VERSION ""

NS_ :

BS_:

BU_: BSM BSM2 CADM CVADAS ECM EPS ORC CANOE EVCU2

BO_ 2654552167 TRSC_Detection_DebugMessage: 64 CVADAS
 SG_ FD14_averageIllumination : 384|32@1+ (0.1,0) [0|300] ""  CANOE
 SG_ FD14_hitchCalibrationAngle : 352|32@1- (0.1,0) [-110|110] "deg"  CANOE
 SG_ FD14_rightCalibrationAngle : 320|32@1- (0.1,0) [-110|110] "deg"  CANOE
 SG_ FD14_leftCalibrationAngle : 288|32@1- (0.1,0) [-110|110] "deg"  CANOE
 SG_ FD14_Trailer_tracking_confidence : 95|32@1- (1,0) [0|100] ""  CANOE
 SG_ FD14_Trailer_Recognition_Confide : 127|32@1- (1,0) [0|100] ""  CANOE
 SG_ FD14_OBTLRecalibrate : 48|1@1+ (1,0) [0|1] ""  CANOE
 SG_ FD14_Presentinfo : 49|3@1+ (1,0) [0|2] ""  CANOE
 SG_ FD14_RecognitionInfo : 52|1@1+ (1,0) [0|1] ""  CANOE
 SG_ FD14_trailerCalibrationDelay : 47|1@1+ (1,0) [0|1] ""  CANOE
 SG_ FD14_trailerCalibrationCount : 70|11@1+ (1,0) [0|10] ""  CANOE
 SG_ FD14_TrailerCalFailInfo : 53|3@1+ (1,0) [0|2] ""  CANOE
 SG_ FD14_Trailercalinfo : 56|3@1+ (1,0) [0|2] ""  CANOE
 SG_ FD14_turnaroundSubState : 59|3@1+ (1,0) [0|2] ""  CANOE
 SG_ FD14_calibrationCompleted : 39|1@1+ (1,0) [0|1] ""  CANOE
 SG_ FD14_JackknifeThrAngle : 159|32@1- (0.01,0) [-110|110] "deg"  CANOE
 SG_ FD14_JackknifeAngle : 191|32@1- (0.01,0) [-110|110] "deg"  CANOE
 SG_ FD14_hitchLength : 223|32@1- (0.01,0) [1000|2500] "mm"  CANOE
 SG_ FD14_curState : 62|8@1+ (1,0) [0|7] ""  CANOE
 SG_ FD14_CurrentTrailer_ID : 40|7@1+ (1,0) [0|6] ""  CANOE
 SG_ FD14_calibrationSubState : 36|3@1+ (1,0) [0|2] ""  CANOE
 SG_ FD14_TADAngleRate : 255|32@1- (0.01,0) [-110|110] "deg"  CANOE
 SG_ FD14_TrailerAngleSign : 32|4@1+ (1,0) [0|3] ""  CANOE
 SG_ FD14_trailerAngle : 0|32@1- (0.01,0) [-110|110] "deg"  CANOE

BO_ 2654552168 TRSC_FID_DebugMessage: 64 CVADAS
 SG_ FD14_m_QM_FID_TRSC_ASCMDef : 40|8@1+ (1,0) [0|255] ""  CANOE
 SG_ FD14_m_QM_FID_TRSC_LIMITED_DefVi : 32|8@1+ (1,0) [0|255] ""  CANOE
 SG_ FD14_m_QM_FID_TRSC_CAM_CAL_ABORT : 24|8@1+ (1,0) [0|255] ""  CANOE
 SG_ FD14_m_QM_FID_TRSC_LIMITED_View : 16|8@1+ (1,0) [0|255] ""  CANOE
 SG_ FD14_m_QM_FID_TRSC_DISABLED : 8|8@1+ (1,0) [0|255] ""  CANOE

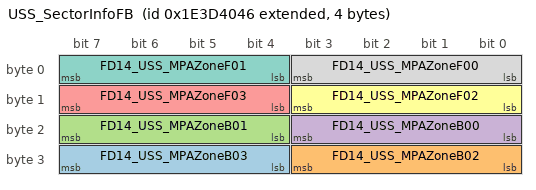
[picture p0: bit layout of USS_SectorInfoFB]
BO_ 2654814278 USS_SectorInfoFB: 4 CVADAS
 SG_ FD14_USS_MPAZoneB03 : 28|4@1+ (1,0) [0|15] ""  CANOE
 SG_ FD14_USS_MPAZoneB02 : 24|4@1+ (1,0) [0|15] ""  CANOE
 SG_ FD14_USS_MPAZoneB01 : 20|4@1+ (1,0) [0|15] ""  CANOE
 SG_ FD14_USS_MPAZoneB00 : 16|4@1+ (1,0) [0|15] ""  CANOE
 SG_ FD14_USS_MPAZoneF03 : 12|4@1+ (1,0) [0|15] ""  CANOE
 SG_ FD14_USS_MPAZoneF02 : 8|4@1+ (1,0) [0|15] ""  CANOE
 SG_ FD14_USS_MPAZoneF01 : 4|4@1+ (1,0) [0|15] ""  CANOE
 SG_ FD14_USS_MPAZoneF00 : 0|4@1+ (1,0) [0|15] ""  CANOE

BO_ 2654552328 USSDebugInfo1: 64 CVADAS
 SG_ FD14_stUSSParkingSlot1DataSlotID : 296|8@1+ (1,0) [0|6] ""  CANOE
 SG_ FD14_stUSSParkingSlot4DataSlotSi : 288|8@1+ (1,0) [0|2] ""  CANOE
 SG_ FD14_stUSSParkingSlot1DataSlotSi : 280|8@1+ (1,0) [0|2] ""  CANOE
 SG_ FD14_stUSSParkingSlot4SlotType : 40|8@1+ (1,0) [0|3] ""  CANOE
 SG_ FD14_stUSSParkingSlot1SlotType : 272|8@1+ (1,0) [0|3] ""  CANOE
 SG_ FD14_stUSSParkingSlot4RearRightY : 240|32@1- (1,0) [0|640] ""  CANOE
 SG_ FD14_stUSSParkingSlot4FrontLeftY : 208|32@1- (1,0) [0|640] ""  CANOE
 SG_ FD14_stUSSParkingSlot1RearRightY : 176|32@1- (1,0) [0|640] ""  CANOE
 SG_ FD14_stUSSParkingSlot1FrontLeftY : 144|32@1- (1,0) [0|640] ""  CANOE
 SG_ FD14_stUSSParkingSlot4RearRightX : 112|32@1- (1,0) [0|400] ""  CANOE
 SG_ FD14_stUSSParkingSlot4FrontLeftX : 80|32@1- (1,0) [0|400] ""  CANOE
 SG_ FD14_stUSSParkingSlot1RearRightX : 48|32@1- (1,0) [0|400] ""  CANOE
 SG_ FD14_stUSSParkingSlot1FrontLeftX : 7|32@1- (1,0) [0|400] ""  CANOE
 SG_ FD14_stUSSParkingSlot6SlotValid : 6|1@1+ (1,0) [0|1] ""  CANOE
 SG_ FD14_stUSSParkingSlot5SlotValid : 5|1@1+ (1,0) [0|1] ""  CANOE
 SG_ FD14_stUSSParkingSlot4SlotValid : 4|1@1+ (1,0) [0|1] ""  CANOE
 SG_ FD14_stUSSParkingSlot3SlotValid : 3|1@1+ (1,0) [0|1] ""  CANOE
 SG_ FD14_stUSSParkingSlot2SlotValid : 2|1@1+ (1,0) [0|1] ""  CANOE
 SG_ FD14_stUSSParkingSlot1SlotValid : 1|1@1+ (1,0) [0|1] ""  CANOE
 SG_ FD14_isUSSInitSuccess_b : 0|1@1+ (1,0) [0|1] ""  CANOE

BO_ 2654552329 USSDebugInfo2: 64 CVADAS
 SG_ FD14_stnumPointsR : 192|16@1+ (1,0) [0|400] ""  CANOE
 SG_ FD14_stnumPointsL : 161|16@1+ (1,0) [0|400] ""  CANOE
 SG_ FD14_stRightObjectList4Valid : 160|1@1+ (1,0) [0|1] ""  CANOE
 SG_ FD14_stRightObjectList3Valid : 159|1@1+ (1,0) [0|1] ""  CANOE
 SG_ FD14_stRightObjectList2Valid : 158|1@1+ (1,0) [0|1] ""  CANOE
 SG_ FD14_stRightObjectList1Valid : 157|1@1+ (1,0) [0|1] ""  CANOE
 SG_ FD14_stLeftObjectList4Valid : 156|1@1+ (1,0) [0|1] ""  CANOE
 SG_ FD14_stLeftObjectList3Valid : 155|1@1+ (1,0) [0|1] ""  CANOE
 SG_ FD14_stLeftObjectList2Valid : 154|1@1+ (1,0) [0|1] ""  CANOE
 SG_ FD14_stLeftObjectList1Valid : 153|1@1+ (1,0) [0|1] ""  CANOE
 SG_ FD14_stUSSLockedSlotDataSlotVali : 152|1@1+ (1,0) [0|1] ""  CANOE
 SG_ FD14_stUSSLockedSlotDataSlotID : 144|8@1+ (1,0) [0|6] ""  CANOE
 SG_ FD14_stUSSLockedSlotDataSlotSide : 136|8@1+ (1,0) [0|2] ""  CANOE
 SG_ FD14_stUSSLockedSlotDataSlotType : 128|8@1+ (1,0) [0|3] ""  CANOE
 SG_ FD14_stUSSLockedSlotDataRearRigh : 96|32@1- (1,0) [0|640] ""  CANOE
 SG_ FD14_stUSSLockedSlotDataFrontLef : 64|32@1- (1,0) [0|640] ""  CANOE
 SG_ FD14_stUSSLockedSlotDataRea_0000 : 32|32@1- (1,0) [0|400] ""  CANOE
 SG_ FD14_stUSSLockedSlotDataFro_0000 : 0|32@1- (1,0) [0|400] ""  CANOE

BO_ 1456 ADAS_FD_HMI: 32 CADM
 SG_ FD14_ACC_Blind : 75|1@0+ (1,0) [0|1] "-"  BSM,ORC
 SG_ FD14_ACC_DispPopupSts : 22|7@0+ (1,0) [0|127] "-"  ORC
 SG_ FD14_ACC_FailSts : 81|1@0+ (1,0) [0|1] "-"  BSM,ORC
 SG_ FD14_ACC_Limit_Fail : 73|1@0+ (1,0) [0|1] "-"  ORC
 SG_ FD14_ACC_Limited : 87|1@0+ (1,0) [0|1] "-"  ORC
 SG_ FD14_ACC_Set_Speed_Strike : 92|1@0+ (1,0) [0|1] "-" Vector__XXX
 SG_ FD14_AEB_Blind : 76|1@0+ (1,0) [0|1] "-"  ORC
 SG_ FD14_AEB_DispPopupSts : 37|6@0+ (1,0) [0|63] "-"  ORC
 SG_ FD14_AEB_FailSts : 83|1@0+ (1,0) [0|1] "-"  BSM,BSM2,ORC
 SG_ FD14_AEB_Limit_Fail : 74|1@0+ (1,0) [0|1] "-"  ORC
 SG_ FD14_AEB_Limited : 72|1@0+ (1,0) [0|1] "-"  BSM,ORC
 SG_ FD14_BlindSpotLeftWarn : 105|2@0+ (1,0) [0|2] ""  ORC
 SG_ FD14_BlindSpotRightWarn : 171|2@0+ (1,0) [0|2] ""  ORC
 SG_ FD14_BSS_Blind_RQSts : 101|1@0+ (1,0) [0|1] ""  ORC
 SG_ FD14_BSS_CFG_STATSts : 103|2@0+ (1,0) [0|2] ""  ORC
 SG_ FD14_BSS_SRV_RQSts : 88|1@0+ (1,0) [0|1] ""  ORC
 SG_ FD14_Chime_Priority : 91|3@0+ (1,0) [0|4] "-" Vector__XXX
 SG_ FD14_Chime_RepRate : 43|4@0+ (1,0) [0|15] "Hz" Vector__XXX
 SG_ FD14_Chime_TypSts : 47|4@0+ (1,0) [0|15] "-"  ORC
 SG_ FD14_CRC_ADAS_FD_HMI : 191|8@0+ (1,0) [0|255] "-"  BSM,BSM2,ECM,EPS
 SG_ FD14_DDD_DispPopupSts : 39|2@0+ (1,0) [0|2] "-"  ORC
 SG_ FD14_DDD_FailSts : 96|1@0+ (1,0) [0|1] "" Vector__XXX
 SG_ FD14_DisplaySts_ACC : 51|4@0+ (1,0) [0|15] "-"  ORC
 SG_ FD14_DisplaySts_Curve : 109|2@0+ (1,0) [0|2] "" Vector__XXX
 SG_ FD14_DisplaySts_OFF : 68|3@0+ (1,0) [0|7] "-" Vector__XXX
 SG_ FD14_DisplaySts_Veh : 63|3@0+ (1,0) [0|7] "-" Vector__XXX
 SG_ FD14_Driver_Model : 107|2@0+ (1,0) [0|3] ""  ORC
 SG_ FD14_FCW_Setting_Avail : 77|1@0+ (1,0) [0|1] "-" Vector__XXX
 SG_ FD14_HAS_Blind : 85|1@0+ (1,0) [0|1] "-"  ORC
 SG_ FD14_HAS_Escalation_Sts : 117|4@0+ (1,0) [0|8] "" Vector__XXX
 SG_ FD14_HAS_FailSts : 80|1@0+ (1,0) [0|1] "-"  ORC
 SG_ FD14_HAS_TelltaleSts : 54|3@0+ (1,0) [0|6] "-"  ORC
 SG_ FD14_HAS_TurnSignalRequest : 111|2@0+ (1,0) [0|2] "" Vector__XXX
 SG_ FD14_ICA_Blind : 55|1@0+ (1,0) [0|1] "-" Vector__XXX
 SG_ FD14_Lane_DisplaySts_Left : 71|3@0+ (1,0) [0|7] "-"  ORC
 SG_ FD14_Lane_DisplaySts_Right : 60|3@0+ (1,0) [0|7] "-"  ORC
 SG_ FD14_Lane_DispPopupSts : 127|8@0+ (1,0) [0|255] "-"  ORC
 SG_ FD14_LF_Chime_RqSts : 93|1@0+ (1,0) [0|1] "-"  ORC
 SG_ FD14_LKA_Blind : 86|1@0+ (1,0) [0|1] "-"  ORC
 SG_ FD14_LKA_FailSts : 84|1@0+ (1,0) [0|1] "-"  ORC
 SG_ FD14_LKA_Status : 23|1@0+ (1,0) [0|1] "-"  ORC
 SG_ FD14_LR_Chime_RqSts : 100|1@0+ (1,0) [0|1] ""  ORC
 SG_ FD14_MessageCounter_ADAS_FD_HMI : 179|4@0+ (1,0) [0|15] "-"  BSM,BSM2,ECM,EPS
 SG_ FD14_NCC_FailSts : 82|1@0+ (1,0) [0|1] "-"  ORC
 SG_ FD14_PEB_Setting_Avail : 78|1@0+ (1,0) [0|1] "-" Vector__XXX
 SG_ FD14_RF_Chime_RqSts : 95|1@0+ (1,0) [0|1] "-"  ORC
 SG_ FD14_RR_Chime_RqSts : 99|1@0+ (1,0) [0|1] ""  ORC
 SG_ FD14_Set_Speed_KPH : 7|8@0+ (1,0) [0|255] "kph"  ECM,ORC
 SG_ FD14_Set_Speed_MPH : 15|8@0+ (1,0) [0|255] "mph"  ECM
 SG_ FD14_SVI_Request : 31|2@0+ (1,0) [0|3] "-" Vector__XXX

BO_ 280 ADAS_FD_INFO: 32 CADM
 SG_ FD14_ACC_Drive_Cmd : 151|1@0+ (1,0) [0|1] "-"  BSM
 SG_ FD14_ACC_StopStart : 97|2@0+ (1,0) [0|2] "-"  ECM
 SG_ FD14_ACC_Systemsts : 183|4@0+ (1,0) [0|14] "-"  BSM,BSM2,CVADAS,ORC
 SG_ FD14_AEB_Sensitivity_Setting : 1|2@0+ (1,0) [0|2] "" Vector__XXX
 SG_ FD14_AEB_Systemsts : 99|2@0+ (1,0) [0|2] "-"  ORC
 SG_ FD14_AEB_Type : 167|4@0+ (1,0) [0|14] "-"  BSM,BSM2,ORC
 SG_ FD14_Brake_Jerk_Req : 100|1@0+ (1,0) [0|1] "-"  BSM,BSM2
 SG_ FD14_CADM_OpStat : 7|3@0+ (1,0) [0|5] "" Vector__XXX
 SG_ FD14_CADM2_EPSSEC_FAIL : 8|1@0+ (1,0) [0|1] ""  EPS
 SG_ FD14_CIPV_Fused : 101|1@0+ (1,0) [0|1] "-"  ORC
 SG_ FD14_CRC_ADAS_FD_INFO : 191|8@0+ (1,0) [0|255] "-"  BSM,BSM2,CVADAS,ECM,EPS
 SG_ FD14_DDD_Setting_Avail : 102|1@0+ (1,0) [0|1] "-" Vector__XXX
 SG_ FD14_DDD_SystemSts : 103|1@0+ (1,0) [0|1] "-"  ORC
 SG_ FD14_ESA_FailSts : 17|1@0+ (1,0) [0|1] "-"  BSM,EPS
 SG_ FD14_ESA_LaneClear_Status : 26|3@0+ (1,0) [0|6] "-"  BSM
 SG_ FD14_ESA_LAT_CTRL_RequestSts : 28|2@0+ (1,0) [0|2] "-"  EPS
 SG_ FD14_ESA_TorqueOverlaySteeringRe : 39|32@0+ (0.0048828125,-5) [-5|20971514.9951172] "-"  EPS
 SG_ FD14_ESASystemSts : 31|3@0+ (1,0) [0|6] "-"  BSM,EPS
 SG_ FD14_ESCALATION_TYPE : 12|3@0+ (1,0) [0|4] ""  ORC
 SG_ FD14_GrMax_Rq_ACC : 150|4@0+ (1,0) [0|15] "-"  BSM
 SG_ FD14_HAS_LAT_CTRL_RequestSts : 110|2@0+ (1,0) [0|3] "-"  EPS
 SG_ FD14_HAS_OpStat_Prim : 4|3@0+ (1,0) [0|5] ""  ORC
 SG_ FD14_HAS_Status : 106|2@0+ (1,0) [0|3] ""  BSM,BSM2,CVADAS
 SG_ FD14_HIS_Req : 89|1@0+ (1,0) [0|1] "-"  BSM,BSM2,ORC
 SG_ FD14_Intervention : 163|12@0+ (0.01,-16) [-16|24.95] "m/s2"  BSM,BSM2,ORC
 SG_ FD14_LANE_CHANGE_SIDE : 95|2@0+ (1,0) [0|2] ""  ORC
 SG_ FD14_LANE_CHANGE_STATUS : 71|4@0+ (1,0) [0|14] ""  ORC
 SG_ FD14_LC_Jerk : 104|1@0+ (1,0) [0|1] "-"  BSM
 SG_ FD14_LKA_LAT_CTRL_RequestSts : 108|2@0+ (1,0) [0|3] "-"  EPS
 SG_ FD14_MessageCounter_ADAS_FD_INFO : 179|4@0+ (1,0) [0|15] "-"  BSM,BSM2,CVADAS,ECM,EPS
 SG_ FD14_MRM_STATUS : 23|3@0+ (1,0) [0|6] ""  BSM,ORC
 SG_ FD14_Object_Dist : 127|8@0+ (1,0) [0|255] "m"  BSM,ORC
 SG_ FD14_PEB_SystemSts : 90|1@0+ (1,0) [0|1] "-"  ORC
 SG_ FD14_Prefill_Req : 91|1@0+ (1,0) [0|1] "-"  BSM,BSM2
 SG_ FD14_SteeringVibration_Rq : 135|1@0+ (1,0) [0|1] "-"  EPS
 SG_ FD14_SteeringVibration_Type : 67|4@0+ (1,0) [0|14] "-"  EPS
 SG_ FD14_TorqueOverlaySteeringReq : 130|11@0+ (0.0048828125,-5) [-5|4.995117188] "-"  EPS,ORC

BO_ 299 ADAS_FD_INFO3: 32 CADM
 SG_ FD14_ACC_Axle_Torque : 7|16@0+ (2,-65534) [-65534|65536] "Nm"  BSM
 SG_ FD14_ACC_Axle_Torque_Enabled : 180|1@0+ (1,0) [0|1] ""  BSM
 SG_ FD14_CRC_ADAS_FD_INFO3 : 191|8@0+ (1,0) [0|255] "-"  BSM
 SG_ FD14_MessageCounter_ADAS_FD_0000 : 179|4@0+ (1,0) [0|15] "-"  BSM

BO_ 730 ADAS_FD_LANES_1: 64 CVADAS
 SG_ FD14_Camera_Status : 23|4@0+ (1,0) [0|15] ""  CADM
 SG_ FD14_Cntr_ADAS_FD_LANES_1 : 455|16@0+ (1,0) [0|65535] "-"  CADM
 SG_ FD14_CRC_ADAS_FD_LANES_1 : 447|8@0+ (1,0) [0|255] "-"  CADM
 SG_ FD14_FOD_Confidence : 335|2@0+ (1,0) [0|3] ""  CADM
 SG_ FD14_Frame_Index_Lanes_1 : 7|16@0+ (1,0) [0|65535] ""  CADM
 SG_ FD14_Health_Front_Object_Detecti : 17|2@0+ (1,0) [0|3] ""  CADM
 SG_ FD14_Health_Lane_Detection : 19|2@0+ (1,0) [0|3] ""  CADM
 SG_ FD14_Line_1_Confidence : 159|4@0+ (0.1,0) [0|1.5] ""  CADM
 SG_ FD14_Line_1_Curvature : 31|16@0+ (9.77E-007,-0.032) [-0.032|0.032027695] ""  CADM
 SG_ FD14_Line_1_Curvature_Rate : 95|16@0+ (3.7252902985E-009,-0.000122) [-0.000122|0.000122136899712198] ""  CADM
 SG_ FD14_Line_1_End_Range : 303|7@0+ (0.5,-25) [-25|38.5] "m"  CADM
 SG_ FD14_Line_1_Heading : 231|10@0+ (0.0009765625,-0.357) [-0.357|0.6420234375] "rad"  CADM
 SG_ FD14_Line_1_Offset : 191|10@0+ (0.01,-5) [-5|5.23] "m"  CADM
 SG_ FD14_Line_1_Start_Range : 271|7@0+ (0.5,-25) [-25|38.5] "m"  CADM
 SG_ FD14_Line_1_Type : 175|4@0+ (1,0) [0|15] ""  CADM
 SG_ FD14_Line_2_Confidence : 155|4@0+ (0.1,0) [0|1.5] ""  CADM
 SG_ FD14_Line_2_Curvature : 47|16@0+ (9.77E-007,-0.032) [-0.032|0.032027695] ""  CADM
 SG_ FD14_Line_2_Curvature_Rate : 111|16@0+ (3.7252902985E-009,-0.000122) [-0.000122|0.000122136899712198] ""  CADM
 SG_ FD14_Line_2_End_Range : 310|7@0+ (0.5,-25) [-25|38.5] "m"  CADM
 SG_ FD14_Line_2_Heading : 237|10@0+ (0.0009765625,-0.357) [-0.357|0.6420234375] "rad"  CADM
 SG_ FD14_Line_2_Offset : 197|10@0+ (0.01,-5) [-5|5.23] "m"  CADM
 SG_ FD14_Line_2_Start_Range : 278|7@0+ (0.5,-25) [-25|38.5] "m"  CADM
 SG_ FD14_Line_2_Type : 171|4@0+ (1,0) [0|15] ""  CADM
 SG_ FD14_Line_3_Confidence : 167|4@0+ (0.1,0) [0|1.5] ""  CADM
 SG_ FD14_Line_3_Curvature : 63|16@0+ (9.77E-007,-0.032) [-0.032|0.032027695] ""  CADM
 SG_ FD14_Line_3_Curvature_Rate : 127|16@0+ (3.7252902985E-009,-0.000122) [-0.000122|0.000122136899712198] ""  CADM
 SG_ FD14_Line_3_End_Range : 319|7@0+ (0.5,-25) [-25|38.5] "m"  CADM
 SG_ FD14_Line_3_Heading : 243|10@0+ (0.0009765625,-0.357) [-0.357|0.6420234375] "rad"  CADM
 SG_ FD14_Line_3_Offset : 203|10@0+ (0.01,-5) [-5|5.23] "m"  CADM
 SG_ FD14_Line_3_Start_Range : 287|7@0+ (0.5,-25) [-25|38.5] "m"  CADM
 SG_ FD14_Line_3_Type : 183|4@0+ (1,0) [0|15] ""  CADM
 SG_ FD14_Line_4_Confidence : 163|4@0+ (0.1,0) [0|1.5] ""  CADM
 SG_ FD14_Line_4_Curvature : 79|16@0+ (9.77E-007,-0.032) [-0.032|0.032027695] ""  CADM
 SG_ FD14_Line_4_Curvature_Rate : 143|16@0+ (3.7252902985E-009,-0.000122) [-0.000122|0.000122136899712198] ""  CADM
 SG_ FD14_Line_4_End_Range : 326|7@0+ (0.5,-25) [-25|38.5] "m"  CADM
 SG_ FD14_Line_4_Heading : 249|10@0+ (0.0009765625,-0.357) [-0.357|0.6420234375] "rad"  CADM
 SG_ FD14_Line_4_Offset : 209|10@0+ (0.01,-5) [-5|5.23] "m"  CADM
 SG_ FD14_Line_4_Start_Range : 294|7@0+ (0.5,-25) [-25|38.5] "m"  CADM
 SG_ FD14_Line_4_Type : 179|4@0+ (1,0) [0|15] ""  CADM
 SG_ FD14_MAC_ADAS_FD_LANES_1 : 471|48@0+ (1,0) [0|0] "-"  CADM
 SG_ FD14_MessageCounter_ADAS_FD_LANE : 435|4@0+ (1,0) [0|15] "-"  CADM
 SG_ FD14_Reserved_for_functional_saf : 431|12@0+ (1,0) [0|0] ""  CADM

BO_ 734 ADAS_FD_LANES_2: 64 CVADAS
 SG_ FD14_Cntr_ADAS_FD_LANES_2 : 455|16@0+ (1,0) [0|65535] "-"  CADM
 SG_ FD14_CRC_ADAS_FD_LANES_2 : 447|8@0+ (1,0) [0|255] "-"  CADM
 SG_ FD14_Frame_Index_Lanes_2 : 7|16@0+ (1,0) [0|65535] ""  CADM
 SG_ FD14_MAC_ADAS_FD_LANES_2 : 471|48@0+ (1,0) [0|0] "-"  CADM
 SG_ FD14_MessageCounter_ADAS_FD_0001 : 435|4@0+ (1,0) [0|15] "-"  CADM
 SG_ FD14_Reserved_for_functiona_0000 : 431|12@0+ (1,0) [0|0] ""  CADM
 SG_ FD14_Segment_1_Confidence : 391|4@0+ (0.1,0) [0|1.5] ""  CADM
 SG_ FD14_Segment_1_ID : 23|4@0+ (1,0) [0|15] ""  CADM
 SG_ FD14_Segment_1_X1 : 55|11@0+ (0.03,-21) [-21|40.41] "m"  CADM
 SG_ FD14_Segment_1_X2 : 223|11@0+ (0.03,-21) [-21|40.41] "m"  CADM
 SG_ FD14_Segment_1_Y1 : 143|10@0+ (0.01,-5) [-5|5.23] "m"  CADM
 SG_ FD14_Segment_1_Y2 : 311|10@0+ (0.01,-5) [-5|5.23] "m"  CADM
 SG_ FD14_Segment_2_Confidence : 387|4@0+ (0.1,0) [0|1.5] ""  CADM
 SG_ FD14_Segment_2_ID : 19|4@0+ (1,0) [0|15] ""  CADM
 SG_ FD14_Segment_2_X1 : 60|11@0+ (0.03,-21) [-21|40.41] "m"  CADM
 SG_ FD14_Segment_2_X2 : 228|11@0+ (0.03,-21) [-21|40.41] "m"  CADM
 SG_ FD14_Segment_2_Y1 : 149|10@0+ (0.01,-5) [-5|5.23] "m"  CADM
 SG_ FD14_Segment_2_Y2 : 317|10@0+ (0.01,-5) [-5|5.23] "m"  CADM
 SG_ FD14_Segment_3_Confidence : 399|4@0+ (0.1,0) [0|1.5] ""  CADM
 SG_ FD14_Segment_3_ID : 31|4@0+ (1,0) [0|15] ""  CADM
 SG_ FD14_Segment_3_X1 : 65|11@0+ (0.03,-21) [-21|40.41] "m"  CADM
 SG_ FD14_Segment_3_X2 : 233|11@0+ (0.03,-21) [-21|40.41] "m"  CADM
 SG_ FD14_Segment_3_Y1 : 155|10@0+ (0.01,-5) [-5|5.23] "m"  CADM
 SG_ FD14_Segment_3_Y2 : 323|10@0+ (0.01,-5) [-5|5.23] "m"  CADM
 SG_ FD14_Segment_4_Confidence : 395|4@0+ (0.1,0) [0|1.5] ""  CADM
 SG_ FD14_Segment_4_ID : 27|4@0+ (1,0) [0|15] ""  CADM
 SG_ FD14_Segment_4_X1 : 86|11@0+ (0.03,-21) [-21|40.41] "m"  CADM
 SG_ FD14_Segment_4_X2 : 254|11@0+ (0.03,-21) [-21|40.41] "m"  CADM
 SG_ FD14_Segment_4_Y1 : 161|10@0+ (0.01,-5) [-5|5.23] "m"  CADM
 SG_ FD14_Segment_4_Y2 : 329|10@0+ (0.01,-5) [-5|5.23] "m"  CADM
 SG_ FD14_Segment_5_Confidence : 407|4@0+ (0.1,0) [0|1.5] ""  CADM
 SG_ FD14_Segment_5_ID : 39|4@0+ (1,0) [0|15] ""  CADM
 SG_ FD14_Segment_5_X1 : 91|11@0+ (0.03,-21) [-21|40.41] "m"  CADM
 SG_ FD14_Segment_5_X2 : 259|11@0+ (0.03,-21) [-21|40.41] "m"  CADM
 SG_ FD14_Segment_5_Y1 : 183|10@0+ (0.01,-5) [-5|5.23] "m"  CADM
 SG_ FD14_Segment_5_Y2 : 351|10@0+ (0.01,-5) [-5|5.23] "m"  CADM
 SG_ FD14_Segment_6_Confidence : 403|4@0+ (0.1,0) [0|1.5] ""  CADM
 SG_ FD14_Segment_6_ID : 35|4@0+ (1,0) [0|15] ""  CADM
 SG_ FD14_Segment_6_X1 : 96|11@0+ (0.03,-21) [-21|40.41] "m"  CADM
 SG_ FD14_Segment_6_X2 : 264|11@0+ (0.03,-21) [-21|40.41] "m"  CADM
 SG_ FD14_Segment_6_Y1 : 189|10@0+ (0.01,-5) [-5|5.23] "m"  CADM
 SG_ FD14_Segment_6_Y2 : 357|10@0+ (0.01,-5) [-5|5.23] "m"  CADM
 SG_ FD14_Segment_7_Confidence : 415|4@0+ (0.1,0) [0|1.5] ""  CADM
 SG_ FD14_Segment_7_ID : 47|4@0+ (1,0) [0|15] ""  CADM
 SG_ FD14_Segment_7_X1 : 117|11@0+ (0.03,-21) [-21|40.41] "m"  CADM
 SG_ FD14_Segment_7_X2 : 285|11@0+ (0.03,-21) [-21|40.41] "m"  CADM
 SG_ FD14_Segment_7_Y1 : 195|10@0+ (0.01,-5) [-5|5.23] "m"  CADM
 SG_ FD14_Segment_7_Y2 : 363|10@0+ (0.01,-5) [-5|5.23] "m"  CADM
 SG_ FD14_Segment_8_Confidence : 411|4@0+ (0.1,0) [0|1.5] ""  CADM
 SG_ FD14_Segment_8_ID : 43|4@0+ (1,0) [0|15] ""  CADM
 SG_ FD14_Segment_8_X1 : 122|11@0+ (0.03,-21) [-21|40.41] "m"  CADM
 SG_ FD14_Segment_8_X2 : 290|11@0+ (0.03,-21) [-21|40.41] "m"  CADM
 SG_ FD14_Segment_8_Y1 : 201|10@0+ (0.01,-5) [-5|5.23] "m"  CADM
 SG_ FD14_Segment_8_Y2 : 369|10@0+ (0.01,-5) [-5|5.23] "m"  CADM

BO_ 204 AXLE_TORQUE_FD_1: 48 ECM
 SG_ FD14_Axle_Torque_DrvReqMod : 55|16@0+ (2,-65534) [-65534|65536] "Nm"  CADM
 SG_ FD14_Axle_TorqueStatic_D_TTC : 39|16@0+ (2,-65534) [-65534|65536] "Nm"  CADM
 SG_ FD14_CRC_AXLE_TORQUE_FD_1 : 319|8@0+ (1,0) [0|255] "-"  BSM,CADM
 SG_ FD14_MessageCounter_AXLE_TORQUE_ : 307|4@0+ (1,0) [0|15] "-"  BSM,CADM
 SG_ FD14_Total_AxleTorque_Max : 7|16@0+ (2,-65534) [-65534|65536] "Nm"  CADM
 SG_ FD14_Total_AxleTorque_Min : 23|16@0+ (2,-65534) [-65534|65536] "Nm"  CADM

BO_ 513 BRAKE_FD_1: 32 BSM
 SG_ FD14_ACCFSafe : 7|8@0+ (1,0) [0|255] "-"  BSM2,CADM
 SG_ FD14_Brk_Jrk_Resp : 60|1@0+ (1,0) [0|1] "-"  CADM,ORC
 SG_ FD14_Brk_Thermdl : 151|1@0+ (1,0) [0|1] "-"  CADM
 SG_ FD14_BrkTrq : 94|15@0+ (3,0) [0|98301] "Nm"  CADM,CVADAS
 SG_ FD14_BrkTrq_Driver : 150|15@0+ (3,0) [0|98301] "Nm"  BSM2,CADM,CVADAS
 SG_ FD14_CRC_BRAKE1 : 191|8@0+ (1,0) [0|255] "-"  BSM2,CADM
 SG_ FD14_DASEngReqPos : 61|1@0+ (1,0) [0|1] "-"  CADM
 SG_ FD14_EngSpdInterv : 163|16@0+ (1,0) [0|65535] "rpm" Vector__XXX
 SG_ FD14_EngSpdIntervReq : 95|1@0+ (1,0) [0|1] "-" Vector__XXX
 SG_ FD14_ExternalBrkRequestsDisabled : 109|2@0+ (1,0) [0|2] "-"  CADM,CVADAS
 SG_ FD14_GrMax_Rq_BSM : 123|4@0+ (1,0) [0|15] "-"  CADM
 SG_ FD14_GrMin_Rq_BSM : 139|4@0+ (1,0) [0|15] "-" Vector__XXX
 SG_ FD14_MessageCounter_BRAKE1 : 179|4@0+ (1,0) [0|15] "-"  BSM2,CADM
 SG_ FD14_REF_VEH_SPEED : 57|10@0+ (0.5,0) [0|511] "kph"  CVADAS
 SG_ FD14_SelectSpdSts : 165|2@0+ (1,0) [0|2] "-" Vector__XXX
 SG_ FD14_SelSpdLmp : 59|2@0+ (1,0) [0|0] "-" Vector__XXX
 SG_ FD14_VehicleStandStillSts : 111|2@0+ (1,0) [0|2] "-"  BSM2,CADM,CVADAS,EPS

BO_ 258 BRAKE_FD_2: 64 BSM
 SG_ FD14_ABSActive : 83|1@0+ (1,0) [0|1] "-"  CADM,ECM
 SG_ FD14_BrakeBoostPressure : 370|11@0+ (0.1,0) [0|200] "bar" Vector__XXX
 SG_ FD14_BrakeBoostStat : 439|4@0+ (1,0) [0|14] "-" Vector__XXX
 SG_ FD14_BrakeInterventionSts : 103|1@0+ (1,0) [0|1] "-"  BSM2,CADM
 SG_ FD14_BrakePedalPressure : 386|11@0+ (0.1,0) [0|200] "bar" Vector__XXX
 SG_ FD14_Brk_Stat : 343|2@0+ (1,0) [0|2] "-"  CADM,CVADAS,ECM
 SG_ FD14_BSM_ESASystemSts : 239|3@0+ (1,0) [0|6] ""  CADM,EPS
 SG_ FD14_CRC_BRAKE2 : 447|8@0+ (1,0) [0|255] "-"  BSM2,CADM,CVADAS,ECM,EPS
 SG_ FD14_ESCActive : 84|1@0+ (1,0) [0|1] "-"  CADM
 SG_ FD14_ESP_Sys_Stat : 71|2@0+ (1,0) [0|3] "-" Vector__XXX
 SG_ FD14_InternalError_BSM : 191|1@0+ (1,0) [0|1] "-"  CADM
 SG_ FD14_LatAcceleration_BSM : 19|12@0+ (0.02,-40.96) [-40.96|40.92] "m/s^2"  CADM,CVADAS,EPS
 SG_ FD14_LatAccelerationFailSts_BSM : 68|1@0+ (1,0) [0|1] "-"  CADM,CVADAS
 SG_ FD14_LongAcceleration_BSM : 35|12@0+ (0.02,-40.96) [-40.96|40.92] "m/s^2"  CADM,CVADAS,EPS
 SG_ FD14_LongAccelerationFailSts_BSM : 69|1@0+ (1,0) [0|1] "-"  CADM,CVADAS
 SG_ FD14_MessageCounter_BRAKE2 : 435|4@0+ (1,0) [0|15] "-"  BSM2,CADM,CVADAS,ECM,EPS
 SG_ FD14_ParkingGearShiftReq_BSM : 22|3@0+ (1,0) [0|6] ""  CVADAS
 SG_ FD14_ParkingInterventionSts : 7|2@0+ (1,0) [0|3] ""  CVADAS
 SG_ FD14_PrefillActive : 86|1@0+ (1,0) [0|1] "-"  CADM
 SG_ FD14_Slope : 135|8@0+ (1,-100) [-100|154] "%"  CVADAS
 SG_ FD14_VehicleSpeedVSOSig : 4|13@0+ (0.0625,0) [0|511.875] "Km/h"  BSM2,CADM,CVADAS,EPS
 SG_ FD14_WheelRPM_FL : 279|16@0+ (0.001953125,0) [0|127.9961] "Rev/s"  EPS
 SG_ FD14_WheelRPM_FR : 295|16@0+ (0.001953125,0) [0|127.9961] "Rev/s"  EPS
 SG_ FD14_YawRate_BSM : 67|12@0+ (0.08,-163.84) [-163.84|163.68] "deg/s"  CADM,CVADAS,EPS
 SG_ FD14_YawRateFailSts_BSM : 87|1@0+ (1,0) [0|1] "-"  CADM,CVADAS,EPS

BO_ 259 BRAKE_FD_3: 32 BSM
 SG_ FD14_CRC__BRAKE3 : 191|8@0+ (1,0) [0|255] "-"  BSM2,CADM,CVADAS,EPS
 SG_ FD14_LatAccelerationOffset_BSM : 127|8@0+ (0.02,-2.56) [-2.56|2.52] "m/s^2"  BSM2,CVADAS
 SG_ FD14_LHF_FastPulseCounter : 167|8@0+ (1,0) [0|255] "pulse"  BSM2,CADM,CVADAS,EPS
 SG_ FD14_LHF_Spin : 23|2@0+ (1,0) [0|3] "-"  BSM2,CADM,CVADAS,EPS
 SG_ FD14_LHF_WheelSensorFailSts : 181|1@0+ (1,0) [0|1] "-"  BSM2,CADM,CVADAS,EPS
 SG_ FD14_LHFWheelSpeed : 20|13@0+ (0.0625,0) [0|511.875] "Km/h"  BSM2,CADM,CVADAS,EPS
 SG_ FD14_LHR_FastPulseCounter : 151|8@0+ (1,0) [0|255] "pulse"  BSM2,CADM,CVADAS,EPS
 SG_ FD14_LHR_Spin : 86|2@0+ (1,0) [0|3] "-"  BSM2,CADM,CVADAS
 SG_ FD14_LHR_WheelSensorFailSts : 87|1@0+ (1,0) [0|1] "-"  BSM2,CADM,CVADAS,EPS
 SG_ FD14_LHRWheelSpeed : 4|13@0+ (0.0625,0) [0|511.875] "Km/h"  BSM2,CADM,CVADAS,EPS
 SG_ FD14_LongAccelerationOffset_BSM : 119|8@0+ (0.02,-2.56) [-2.56|2.52] "m/s^2"  BSM2,CVADAS
 SG_ FD14_LwsAngleOffset_BSM : 81|10@0+ (0.1,-51.1) [-51.1|51.1] "°"  BSM2,CADM
 SG_ FD14_MessageCounter_BRAKE3 : 179|4@0+ (1,0) [0|15] "-"  BSM2,CADM,CVADAS,EPS
 SG_ FD14_RHF_FastPulseCounter : 175|8@0+ (1,0) [0|255] "pulse"  BSM2,CADM,CVADAS,EPS
 SG_ FD14_RHF_Spin : 7|2@0+ (1,0) [0|3] "-"  BSM2,CADM,CVADAS,EPS
 SG_ FD14_RHF_WheelSensorFailSts : 182|1@0+ (1,0) [0|1] "-"  BSM2,CADM,CVADAS,EPS
 SG_ FD14_RHFWheelSpeed : 52|13@0+ (0.0625,0) [0|511.875] "Km/h"  BSM2,CADM,CVADAS,EPS
 SG_ FD14_RHR_FastPulseCounter : 159|8@0+ (1,0) [0|255] "pulse"  BSM2,CADM,CVADAS,EPS
 SG_ FD14_RHR_Spin : 102|2@0+ (1,0) [0|3] "-"  BSM2,CADM,CVADAS
 SG_ FD14_RHR_WheelSensorFailSts : 103|1@0+ (1,0) [0|1] "-"  BSM2,CADM,CVADAS,EPS
 SG_ FD14_RHRWheelSpeed : 68|13@0+ (0.0625,0) [0|511.875] "Km/h"  BSM2,CADM,CVADAS,EPS
 SG_ FD14_YawRateOffset_BSM : 111|8@0+ (0.08,-10.24) [-6.96|6.96] "°/s"  BSM2

BO_ 609 BRAKE_FD_4: 32 BSM
 SG_ FD14_ASRActive : 90|1@0+ (1,0) [0|1] "-" Vector__XXX
 SG_ FD14_BSM_LnchAbrtSts : 33|2@0+ (1,0) [0|2] "-" Vector__XXX
 SG_ FD14_BSM_LnchCtrl_SftBtn_SelectS : 0|1@0+ (1,0) [0|1] "-" Vector__XXX
 SG_ FD14_BSM_LnchMode : 55|3@0+ (1,0) [0|6] "-" Vector__XXX
 SG_ FD14_CRC_BRAKE4 : 191|8@0+ (1,0) [0|255] "-"  CADM
 SG_ FD14_EPBSts : 115|4@0+ (1,0) [0|14] "-"  CADM,CVADAS
 SG_ FD14_ESC_OFF_Hrd_Sft_Button_sts : 151|3@0+ (1,0) [0|6] "-" Vector__XXX
 SG_ FD14_LaunchRPMsetting_BSM : 63|6@0+ (100,1000) [1000|7300] "rpm" Vector__XXX
 SG_ FD14_MessageCounter_BRAKE4 : 179|4@0+ (1,0) [0|15] "-"  CADM
 SG_ FD14_MSRActive : 92|1@0+ (1,0) [0|1] "-" Vector__XXX
 SG_ FD14_TravelDistance : 87|8@0+ (1,0) [0|255] "m" Vector__XXX

CM_ SG_ 2654552168 FD14_m_QM_FID_TRSC_ASCMDef "FID TRSC ASCMDef";
CM_ SG_ 2654552168 FD14_m_QM_FID_TRSC_LIMITED_DefVi "FID TRSC Limited DefView";
CM_ SG_ 2654552168 FD14_m_QM_FID_TRSC_CAM_CAL_ABORT "FID TRSC Camera Calibration Abort";
CM_ SG_ 2654552168 FD14_m_QM_FID_TRSC_LIMITED_View "FID TRSC Limited View";
CM_ SG_ 2654552168 FD14_m_QM_FID_TRSC_DISABLED "FID TRSC Disabled";
CM_ SG_ 1456 FD14_ACC_Blind "ACC_Blind";
CM_ SG_ 1456 FD14_ACC_DispPopupSts "ACC Dips Pop Up";
CM_ SG_ 1456 FD14_ACC_FailSts "ACC_FailSts";
CM_ SG_ 1456 FD14_ACC_Limit_Fail "ACC_Limit_Fail";
CM_ SG_ 1456 FD14_ACC_Limited "ACC_Limited";
CM_ SG_ 1456 FD14_ACC_Set_Speed_Strike "ACC Set Speed Strike";
CM_ SG_ 1456 FD14_AEB_Blind "AEB_Blind";
CM_ SG_ 1456 FD14_AEB_DispPopupSts "AEB Dips Pop Up";
CM_ SG_ 1456 FD14_AEB_FailSts "AEB_FailSts";
CM_ SG_ 1456 FD14_AEB_Limit_Fail "AEB_Limit_Fail";
CM_ SG_ 1456 FD14_AEB_Limited "AEB_Limited";
CM_ SG_ 1456 FD14_BlindSpotLeftWarn "BlindSpotLeftWarn";
CM_ SG_ 1456 FD14_BlindSpotRightWarn "BlindSpotRightWarn";
CM_ SG_ 1456 FD14_BSS_Blind_RQSts "Sensor blinded request from BSS";
CM_ SG_ 1456 FD14_BSS_CFG_STATSts "Blind Spot configuration status";
CM_ SG_ 1456 FD14_BSS_SRV_RQSts "BSS service warning request";
CM_ SG_ 1456 FD14_Chime_Priority "Chime Priority";
CM_ SG_ 1456 FD14_Chime_RepRate "DASM Chime Repetition Rate";
CM_ SG_ 1456 FD14_Chime_TypSts "DASM Chime Type Status";
CM_ SG_ 1456 FD14_CRC_ADAS_FD_HMI "CRC according to SAE J1850 standard at each frame transmission.";
CM_ SG_ 1456 FD14_DDD_DispPopupSts "DDD Disp Pop Up";
CM_ SG_ 1456 FD14_DDD_FailSts "DDD Fail Sts CADM2";
CM_ SG_ 1456 FD14_DisplaySts_ACC "Display status ACC";
CM_ SG_ 1456 FD14_DisplaySts_Curve "Indication that Curve Speed Control is reducing vehicle target speed in response to tight curve";
CM_ SG_ 1456 FD14_DisplaySts_OFF "Display Status Off";
CM_ SG_ 1456 FD14_DisplaySts_Veh "Display Status Veh";
CM_ SG_ 1456 FD14_Driver_Model "Overall assessment of whether driver is attentive to the driving task according to driver model";
CM_ SG_ 1456 FD14_FCW_Setting_Avail "FCW setting availability";
CM_ SG_ 1456 FD14_HAS_Blind "HAS_Blind";
CM_ SG_ 1456 FD14_HAS_Escalation_Sts "HAS_Escalation_Sts";
CM_ SG_ 1456 FD14_HAS_FailSts "HAS_FailSts";
CM_ SG_ 1456 FD14_HAS_TelltaleSts "Highway Assist telltale status in cluster";
CM_ SG_ 1456 FD14_HAS_TurnSignalRequest "Request from the primary controller to actuate the turn signals";
CM_ SG_ 1456 FD14_ICA_Blind "This signal is used to indicate the presence of an occlusion of the ICA feature";
CM_ SG_ 1456 FD14_Lane_DisplaySts_Left "Lane Display Status Left";
CM_ SG_ 1456 FD14_Lane_DisplaySts_Right "Lane Display Status Right";
CM_ SG_ 1456 FD14_Lane_DispPopupSts "Lane Management Pop-up Messages.TEXT MSG n corresponds to a raw value of 'n'";
CM_ SG_ 1456 FD14_LF_Chime_RqSts "DASM_LF_Chime_RqSts";
CM_ SG_ 1456 FD14_LKA_Blind "LKA_Blind";
CM_ SG_ 1456 FD14_LKA_FailSts "LKA_FailSts";
CM_ SG_ 1456 FD14_LKA_Status "None";
CM_ SG_ 1456 FD14_LR_Chime_RqSts "BSM Left rear chime on request";
CM_ SG_ 1456 FD14_MessageCounter_ADAS_FD_HMI "This signal is a counter used for safety checks strategies. This counter is incremented of 1 (one) unit at each frame transmission.";
CM_ SG_ 1456 FD14_NCC_FailSts "NCC_FailSts";
CM_ SG_ 1456 FD14_PEB_Setting_Avail "PEB setting availability";
CM_ SG_ 1456 FD14_RF_Chime_RqSts "DASM_RF_Chime_RqSts";
CM_ SG_ 1456 FD14_RR_Chime_RqSts "BSM right rear chime on request";
CM_ SG_ 1456 FD14_Set_Speed_KPH "Speed shown by IPC, which ACC is controlling in KPH";
CM_ SG_ 1456 FD14_Set_Speed_MPH "Speed shown by IPC, which ACC is controlling in MPH";
CM_ SG_ 1456 FD14_SVI_Request "Request to activate Secondary Visual Indication";
CM_ SG_ 280 FD14_ACC_Drive_Cmd "ACC Drive Command";
CM_ SG_ 280 FD14_ACC_StopStart "Allows StopStart when ACC is engaged";
CM_ SG_ 280 FD14_ACC_Systemsts "ACC System Status";
CM_ SG_ 280 FD14_AEB_Sensitivity_Setting "AEB sensitivity status";
CM_ SG_ 280 FD14_AEB_Systemsts "AEB System Status";
CM_ SG_ 280 FD14_AEB_Type "AEB Type";
CM_ SG_ 280 FD14_Brake_Jerk_Req "Request from DASM to perform Jerk Warning";
CM_ SG_ 280 FD14_CADM_OpStat "Capability of primary controller to sense and compute a valid trajectory path based on external data dependencies and internal failures";
CM_ SG_ 280 FD14_CADM2_EPSSEC_FAIL "CADM2 detection of failure to communicate to EPS";
CM_ SG_ 280 FD14_CIPV_Fused "Closest in-path vehicle is fused True = 1";
CM_ SG_ 280 FD14_CRC_ADAS_FD_INFO "CRC according to SAE J1850 standard at each frame transmission.";
CM_ SG_ 280 FD14_DDD_Setting_Avail "DDD_Setting Av Status";
CM_ SG_ 280 FD14_DDD_SystemSts "DDD System Status";
CM_ SG_ 280 FD14_ESA_FailSts "ESA Failure Status";
CM_ SG_ 280 FD14_ESA_LaneClear_Status "Lane Clear Information";
CM_ SG_ 280 FD14_ESA_LAT_CTRL_RequestSts "ESA Lateral Control Request Status";
CM_ SG_ 280 FD14_ESA_TorqueOverlaySteeringRe "ESA Steering Torque Overlay Request";
CM_ SG_ 280 FD14_ESASystemSts "ESA System Status";
CM_ SG_ 280 FD14_ESCALATION_TYPE "Type of HMI escalation to be provided to driver from primary controller";
CM_ SG_ 280 FD14_GrMax_Rq_ACC "Used to request Max Gear from TCM";
CM_ SG_ 280 FD14_HAS_LAT_CTRL_RequestSts "HAS_LAT_CTRL_RequestSts";
CM_ SG_ 280 FD14_HAS_OpStat_Prim "Capability of the primary controller to perform sensing, computing, and actuation";
CM_ SG_ 280 FD14_HAS_Status "Highway Assist System Status as reported by the main controller";
CM_ SG_ 280 FD14_HIS_Req "Used to command Stop during Stop and Go ACC and FSFCW+";
CM_ SG_ 280 FD14_Intervention "Request to set target acceleration/deceleration for any feature";
CM_ SG_ 280 FD14_LANE_CHANGE_SIDE "Direction of the currently in-progress lane change from a vehicle perspective";
CM_ SG_ 280 FD14_LANE_CHANGE_STATUS "Status of assisted lane change maneuver";
CM_ SG_ 280 FD14_LC_Jerk "Lane Centering request for brake jerk";
CM_ SG_ 280 FD14_LKA_LAT_CTRL_RequestSts "LKA_LAT_CTRL_RequestSts";
CM_ SG_ 280 FD14_MessageCounter_ADAS_FD_INFO "This signal is a counter used for safety checks strategies. This counter is incremented of 1 (one) unit at each frame transmission.";
CM_ SG_ 280 FD14_MRM_STATUS "Status of the minimum risk maneuver to handle system faults or driver abuse as understood by primary controller";
CM_ SG_ 280 FD14_Object_Dist "It indicates the distance to the recognized object";
CM_ SG_ 280 FD14_PEB_SystemSts "PEB System Status";
CM_ SG_ 280 FD14_Prefill_Req "Prefill command of Brake System by DASM";
CM_ SG_ 280 FD14_SteeringVibration_Rq "Request to activate Steering Wheel Vibration";
CM_ SG_ 280 FD14_SteeringVibration_Type "Type of Steering Wheel Vibration Request";
CM_ SG_ 280 FD14_TorqueOverlaySteeringReq "TorqueOverlaySteeringReq";
CM_ SG_ 299 FD14_ACC_Axle_Torque "ACC requested Axle Torque";
CM_ SG_ 299 FD14_ACC_Axle_Torque_Enabled "An enable bit that axle torque commands should be followed";
CM_ SG_ 299 FD14_CRC_ADAS_FD_INFO3 "CRC according to SAE J1850 standard at each frame transmission.";
CM_ SG_ 299 FD14_MessageCounter_ADAS_FD_0000 "This signal is a counter used for safety checks strategies. This counter is incremented of 1 (one) unit at each frame transmission.";
CM_ SG_ 730 FD14_Camera_Status "List of which cameras are active";
CM_ SG_ 730 FD14_CRC_ADAS_FD_LANES_1 "CRC according to SAE J1850 standard at each frame transmission.";
CM_ SG_ 730 FD14_FOD_Confidence "Front Object Detection Confidence";
CM_ SG_ 730 FD14_Frame_Index_Lanes_1 "Frame index number for lanes_1 data";
CM_ SG_ 730 FD14_Health_Front_Object_Detecti "Health of the Front Object Detection system";
CM_ SG_ 730 FD14_Health_Lane_Detection "Health of the Lane Marker Detection system";
CM_ SG_ 730 FD14_Line_1_Confidence "Lane marker 1 confidence";
CM_ SG_ 730 FD14_Line_1_Curvature "Lane marker 1 curvature rate (2nd order)";
CM_ SG_ 730 FD14_Line_1_Curvature_Rate "Lane marker 1 curvature rate (3rd order)";
CM_ SG_ 730 FD14_Line_1_End_Range "Lane marker 1 end range/view range";
CM_ SG_ 730 FD14_Line_1_Heading "Lane marker 1 heading angle (1st order)";
CM_ SG_ 730 FD14_Line_1_Offset "Lane marker 1 offset distance";
CM_ SG_ 730 FD14_Line_1_Start_Range "Lane marker 1 start range/view range";
CM_ SG_ 730 FD14_Line_1_Type "Lane marker 1 type";
CM_ SG_ 730 FD14_Line_2_Confidence "Lane marker 2 confidence";
CM_ SG_ 730 FD14_Line_2_Curvature "Lane marker 2 curvature rate (2nd order)";
CM_ SG_ 730 FD14_Line_2_Curvature_Rate "Lane marker 2 curvature rate (3rd order)";
CM_ SG_ 730 FD14_Line_2_End_Range "Lane marker 2 end range/view range";
CM_ SG_ 730 FD14_Line_2_Heading "Lane marker 2 heading angle (1st order)";
CM_ SG_ 730 FD14_Line_2_Offset "Lane marker 2 offset distance";
CM_ SG_ 730 FD14_Line_2_Start_Range "Lane marker 2 start range/view range";
CM_ SG_ 730 FD14_Line_2_Type "Lane marker 2 type";
CM_ SG_ 730 FD14_Line_3_Confidence "Lane marker 3 confidence";
CM_ SG_ 730 FD14_Line_3_Curvature "Lane marker 3 curvature rate (2nd order)";
CM_ SG_ 730 FD14_Line_3_Curvature_Rate "Lane marker 3 curvature rate (3rd order)";
CM_ SG_ 730 FD14_Line_3_End_Range "Lane marker 3 end range/view range";
CM_ SG_ 730 FD14_Line_3_Heading "Lane marker 3 heading angle (1st order)";
CM_ SG_ 730 FD14_Line_3_Offset "Lane marker 3 offset distance";
CM_ SG_ 730 FD14_Line_3_Start_Range "Lane marker 3 start range/view range";
CM_ SG_ 730 FD14_Line_3_Type "Lane marker 3 type";
CM_ SG_ 730 FD14_Line_4_Confidence "Lane marker 4 confidence";
CM_ SG_ 730 FD14_Line_4_Curvature "Lane marker 4 curvature rate (2nd order)";
CM_ SG_ 730 FD14_Line_4_Curvature_Rate "Lane marker 4 curvature rate (3rd order)";
CM_ SG_ 730 FD14_Line_4_End_Range "Lane marker 4 end range/view range";
CM_ SG_ 730 FD14_Line_4_Heading "Lane marker 4 heading angle (1st order)";
CM_ SG_ 730 FD14_Line_4_Offset "Lane marker 4 offset distance";
CM_ SG_ 730 FD14_Line_4_Start_Range "Lane marker 4 start range/view range";
CM_ SG_ 730 FD14_Line_4_Type "Lane marker 4 type";
CM_ SG_ 730 FD14_MAC_ADAS_FD_LANES_1 "-";
CM_ SG_ 730 FD14_MessageCounter_ADAS_FD_LANE "This signal is a counter used for safety checks strategies. This counter is incremented of 1 (one) unit at each frame transmission.";
CM_ SG_ 734 FD14_CRC_ADAS_FD_LANES_2 "CRC according to SAE J1850 standard at each frame transmission.";
CM_ SG_ 734 FD14_Frame_Index_Lanes_2 "Frame index number for lanes_2 data";
CM_ SG_ 734 FD14_MAC_ADAS_FD_LANES_2 "-";
CM_ SG_ 734 FD14_MessageCounter_ADAS_FD_0001 "This signal is a counter used for safety checks strategies. This counter is incremented of 1 (one) unit at each frame transmission.";
CM_ SG_ 734 FD14_Segment_1_Confidence "Line segment 1 confidence";
CM_ SG_ 734 FD14_Segment_1_ID "ID value of line segment 1";
CM_ SG_ 734 FD14_Segment_1_X1 "Line segment 1 start point longitudinal position";
CM_ SG_ 734 FD14_Segment_1_X2 "Line segment 1 end point longitudinal position";
CM_ SG_ 734 FD14_Segment_1_Y1 "Line segment 1 start point lateral position";
CM_ SG_ 734 FD14_Segment_1_Y2 "Line segment 1 end point lateral position";
CM_ SG_ 734 FD14_Segment_2_Confidence "Line segment 2 confidence";
CM_ SG_ 734 FD14_Segment_2_ID "ID value of line segment 2";
CM_ SG_ 734 FD14_Segment_2_X1 "Line segment 2 start point longitudinal position";
CM_ SG_ 734 FD14_Segment_2_X2 "Line segment 2 end point longitudinal position";
CM_ SG_ 734 FD14_Segment_2_Y1 "Line segment 2 start point lateral position";
CM_ SG_ 734 FD14_Segment_2_Y2 "Line segment 2 end point lateral position";
CM_ SG_ 734 FD14_Segment_3_Confidence "Line segment 3 confidence";
CM_ SG_ 734 FD14_Segment_3_ID "ID value of line segment 3";
CM_ SG_ 734 FD14_Segment_3_X1 "Line segment 3 start point longitudinal position";
CM_ SG_ 734 FD14_Segment_3_X2 "Line segment 3 end point longitudinal position";
CM_ SG_ 734 FD14_Segment_3_Y1 "Line segment 3 start point lateral position";
CM_ SG_ 734 FD14_Segment_3_Y2 "Line segment 3 end point lateral position";
CM_ SG_ 734 FD14_Segment_4_Confidence "Line segment 4 confidence";
CM_ SG_ 734 FD14_Segment_4_ID "ID value of line segment 4";
CM_ SG_ 734 FD14_Segment_4_X1 "Line segment 4 start point longitudinal position";
CM_ SG_ 734 FD14_Segment_4_X2 "Line segment 4 end point longitudinal position";
CM_ SG_ 734 FD14_Segment_4_Y1 "Line segment 4 start point lateral position";
CM_ SG_ 734 FD14_Segment_4_Y2 "Line segment 4 end point lateral position";
CM_ SG_ 734 FD14_Segment_5_Confidence "Line segment 5 confidence";
CM_ SG_ 734 FD14_Segment_5_ID "ID value of line segment 5";
CM_ SG_ 734 FD14_Segment_5_X1 "Line segment 5 start point longitudinal position";
CM_ SG_ 734 FD14_Segment_5_X2 "Line segment 5 end point longitudinal position";
CM_ SG_ 734 FD14_Segment_5_Y1 "Line segment 5 start point lateral position";
CM_ SG_ 734 FD14_Segment_5_Y2 "Line segment 5 end point lateral position";
CM_ SG_ 734 FD14_Segment_6_Confidence "Line segment 6 confidence";
CM_ SG_ 734 FD14_Segment_6_ID "ID value of line segment 6";
CM_ SG_ 734 FD14_Segment_6_X1 "Line segment 6 start point longitudinal position";
CM_ SG_ 734 FD14_Segment_6_X2 "Line segment 6 end point longitudinal position";
CM_ SG_ 734 FD14_Segment_6_Y1 "Line segment 6 start point lateral position";
CM_ SG_ 734 FD14_Segment_6_Y2 "Line segment 6 end point lateral position";
CM_ SG_ 734 FD14_Segment_7_Confidence "Line segment 7 confidence";
CM_ SG_ 734 FD14_Segment_7_ID "ID value of line segment 7";
CM_ SG_ 734 FD14_Segment_7_X1 "Line segment 7 start point longitudinal position";
CM_ SG_ 734 FD14_Segment_7_X2 "Line segment 7 end point longitudinal position";
CM_ SG_ 734 FD14_Segment_7_Y1 "Line segment 7 start point lateral position";
CM_ SG_ 734 FD14_Segment_7_Y2 "Line segment 7 end point lateral position";
CM_ SG_ 734 FD14_Segment_8_Confidence "Line segment 8 confidence";
CM_ SG_ 734 FD14_Segment_8_ID "ID value of line segment 8";
CM_ SG_ 734 FD14_Segment_8_X1 "Line segment 8 start point longitudinal position";
CM_ SG_ 734 FD14_Segment_8_X2 "Line segment 8 end point longitudinal position";
CM_ SG_ 734 FD14_Segment_8_Y1 "Line segment 8 start point lateral position";
CM_ SG_ 734 FD14_Segment_8_Y2 "Line segment 8 end point lateral position";
CM_ SG_ 204 FD14_Axle_Torque_DrvReqMod "Driver requested Axle torque raw (no torque shaping)";
CM_ SG_ 204 FD14_Axle_TorqueStatic_D_TTC "Driver requested Axle torque (filtered/ torque shaped)";
CM_ SG_ 204 FD14_CRC_AXLE_TORQUE_FD_1 "CRC according to SAE J1850 standard at each frame transmission.";
CM_ SG_ 204 FD14_MessageCounter_AXLE_TORQUE_ "This signal is a counter used for safety checks strategies. This counter is incremented of 1 (one) unit at each frame transmission.";
CM_ SG_ 204 FD14_Total_AxleTorque_Max "Maximum total Axle torque";
CM_ SG_ 204 FD14_Total_AxleTorque_Min "Minimum total Axle torque";
CM_ SG_ 513 FD14_ACCFSafe "0";
CM_ SG_ 513 FD14_Brk_Jrk_Resp "0";
CM_ SG_ 513 FD14_Brk_Thermdl "This signal indicate when the estimated brake temperature is over a predefined threshold.";
CM_ SG_ 513 FD14_BrkTrq "0";
CM_ SG_ 513 FD14_BrkTrq_Driver "0";
CM_ SG_ 513 FD14_CRC_BRAKE1 "CRC according to SAE J1850 standard at each frame transmission.";
CM_ SG_ 513 FD14_DASEngReqPos "0";
CM_ SG_ 513 FD14_EngSpdInterv "Engine speed intervention value";
CM_ SG_ 513 FD14_EngSpdIntervReq "Engine speed intervention request (1=active)";
CM_ SG_ 513 FD14_ExternalBrkRequestsDisabled "0";
CM_ SG_ 513 FD14_GrMax_Rq_BSM "Requested gear, upper limit";
CM_ SG_ 513 FD14_GrMin_Rq_BSM "Requested gear, lower limit";
CM_ SG_ 513 FD14_MessageCounter_BRAKE1 "This signal is a counter used for safety checks strategies. This counter is incremented of 1 (one) unit at each frame transmission.";
CM_ SG_ 513 FD14_REF_VEH_SPEED "0";
CM_ SG_ 513 FD14_SelectSpdSts "0";
CM_ SG_ 513 FD14_SelSpdLmp "Select speed lamp status";
CM_ SG_ 513 FD14_VehicleStandStillSts "This signal indicates if the car is in stand still condition";
CM_ SG_ 258 FD14_ABSActive "This signal is set to Active when the ABS functionality is active.";
CM_ SG_ 258 FD14_BrakeBoostPressure "Pressure Information from Brake Booster Pressure Sensor";
CM_ SG_ 258 FD14_BrakeBoostStat "eBoost System Status INIT, eBOOST, PUSH-THROUGH, SNA";
CM_ SG_ 258 FD14_BrakeInterventionSts "This signal is ?active? when the brake intervention is due to BSM events and ?not active? when the brake intervention is due to the driver";
CM_ SG_ 258 FD14_BrakePedalPressure "Pressure Information from Brake Pedal Simulator Pressure Sensor";
CM_ SG_ 258 FD14_Brk_Stat "Brake state";
CM_ SG_ 258 FD14_BSM_ESASystemSts "Brake System ESA Status";
CM_ SG_ 258 FD14_CRC_BRAKE2 "CRC according to SAE J1850 standard at each frame transmission.";
CM_ SG_ 258 FD14_ESCActive "This signal is set to Active when the brake intervention by ESC is active.";
CM_ SG_ 258 FD14_ESP_Sys_Stat "0";
CM_ SG_ 258 FD14_InternalError_BSM "This signal indicates if an internal error has been processed";
CM_ SG_ 258 FD14_LatAcceleration_BSM "This signal indicates the Lateral Acceleration Value";
CM_ SG_ 258 FD14_LatAccelerationFailSts_BSM "This signal indicates the status of Lateral Acceleration Signal";
CM_ SG_ 258 FD14_LongAcceleration_BSM "This signal indicates the Longitudinal Acceleration Value";
CM_ SG_ 258 FD14_LongAccelerationFailSts_BSM "This signal indicates the status of Longitudinal acceleration signal";
CM_ SG_ 258 FD14_MessageCounter_BRAKE2 "This signal is a counter used for safety checks strategies. This counter is incremented of 1 (one) unit at each frame transmission.";
CM_ SG_ 258 FD14_ParkingGearShiftReq_BSM "CVPAM Request to autonomously shift gears";
CM_ SG_ 258 FD14_ParkingInterventionSts "Current status of BSM during Autonomous Parking Maneuver";
CM_ SG_ 258 FD14_PrefillActive "This signal indicates the prefill function status.";
CM_ SG_ 258 FD14_Slope "Slope value detected by BSM";
CM_ SG_ 258 FD14_VehicleSpeedVSOSig "It is the average vehicle speed calculated.";
CM_ SG_ 258 FD14_WheelRPM_FL "Wheel RPM front left";
CM_ SG_ 258 FD14_WheelRPM_FR "Wheel RPM front right";
CM_ SG_ 258 FD14_YawRate_BSM "This signal indicates the Yaw Rate Value";
CM_ SG_ 258 FD14_YawRateFailSts_BSM "This signal indicates the Status of Yaw Rate Signal";
CM_ SG_ 259 FD14_CRC__BRAKE3 "CRC according to SAE J1850 standard at each frame transmission.";
CM_ SG_ 259 FD14_LatAccelerationOffset_BSM "LatAccelerationOffset_BSM";
CM_ SG_ 259 FD14_LHF_FastPulseCounter "This signal is the left front wheel pulse counter.";
CM_ SG_ 259 FD14_LHF_Spin "This signal indicates the left hand front wheel status";
CM_ SG_ 259 FD14_LHF_WheelSensorFailSts "This signal indicates the fail status of LHF sensor";
CM_ SG_ 259 FD14_LHFWheelSpeed "This is the value of the left front wheel speed";
CM_ SG_ 259 FD14_LHR_FastPulseCounter "This signal is the left rear wheel pulse counter.";
CM_ SG_ 259 FD14_LHR_Spin "This signal indicates the left hand rear wheel status";
CM_ SG_ 259 FD14_LHR_WheelSensorFailSts "This signal indicates the fail status of LHR sensor";
CM_ SG_ 259 FD14_LHRWheelSpeed "This is the value of the left rear wheel speed";
CM_ SG_ 259 FD14_LongAccelerationOffset_BSM "LongAccelerationOffset_BSM";
CM_ SG_ 259 FD14_LwsAngleOffset_BSM "LwsAngleOffset_BSM";
CM_ SG_ 259 FD14_MessageCounter_BRAKE3 "This signal is a counter used for safety checks strategies. This counter is incremented of 1 (one) unit at each frame transmission.";
CM_ SG_ 259 FD14_RHF_FastPulseCounter "This signal is the right front wheel pulse counter.";
CM_ SG_ 259 FD14_RHF_Spin "This signal indicates the right hand front wheel status";
CM_ SG_ 259 FD14_RHF_WheelSensorFailSts "This signal indicates the fail status of RHF sensor";
CM_ SG_ 259 FD14_RHFWheelSpeed "This is the value of the right front wheel speed";
CM_ SG_ 259 FD14_RHR_FastPulseCounter "This signal is the right rear wheel pulse counter.";
CM_ SG_ 259 FD14_RHR_Spin "This signal indicates the right hand rear wheel status";
CM_ SG_ 259 FD14_RHR_WheelSensorFailSts "This signal indicates the fail status of RHR sensor";
CM_ SG_ 259 FD14_RHRWheelSpeed "This is the value of the right rear wheel speed";
CM_ SG_ 259 FD14_YawRateOffset_BSM "YawRateOffset_BSM";
CM_ SG_ 609 FD14_ASRActive "This signal is set to Active when the intervention by ASR is Active";
CM_ SG_ 609 FD14_BSM_LnchAbrtSts "Launch Control Abort Status";
CM_ SG_ 609 FD14_BSM_LnchCtrl_SftBtn_SelectS "Soft button launch selected; Launch selected = [1]";
CM_ SG_ 609 FD14_BSM_LnchMode "Launch Control Status";
CM_ SG_ 609 FD14_CRC_BRAKE4 "CRC according to SAE J1850 standard at each frame transmission.";
CM_ SG_ 609 FD14_EPBSts "0";
CM_ SG_ 609 FD14_ESC_OFF_Hrd_Sft_Button_sts "ESC hard button status";
CM_ SG_ 609 FD14_LaunchRPMsetting_BSM "BSM  Launch RPM setting";
CM_ SG_ 609 FD14_MessageCounter_BRAKE4 "This signal is a counter used for safety checks strategies. This counter is incremented of 1 (one) unit at each frame transmission.";
CM_ SG_ 609 FD14_MSRActive "0";
CM_ SG_ 609 FD14_TravelDistance "This signal indicates the travel distance value.";
BA_DEF_ SG_  "GenSigStartValue" INT 0 2147483647;
BA_DEF_ SG_  "GenSigInactiveValue" INT 0 2147483647;
BA_DEF_ SG_  "GenSigSendType" ENUM  "NotUsed","OnWrite","OnWriteWithRepetition","OnChange","OnChangeWithRepetition","IfActive","IfActiveWithRepetition","NoSigSendType";
BA_DEF_ SG_  "GenSigTimeoutTime_BSM" INT 0 65535;
BA_DEF_ SG_  "GenSigTimeoutTime_BSM2" INT 0 65535;
BA_DEF_ SG_  "GenSigTimeoutTime_CADM" INT 0 65535;
BA_DEF_ SG_  "GenSigTimeoutTime_CVADAS" INT 0 65535;
BA_DEF_ SG_  "GenSigTimeoutTime_ECM" INT 0 65535;
BA_DEF_ SG_  "GenSigTimeoutTime_EPS" INT 0 65535;
BA_DEF_ SG_  "GenSigTimeoutTime_EVCU2" INT 0 65535;
BA_DEF_ SG_  "GenSigTimeoutTime_ORC" INT 0 65535;
BA_DEF_ BO_  "DiagRequest" ENUM  "No","Yes";
BA_DEF_ BO_  "Type" ENUM  "P","C","PE","COC","PE_Cntrl","E","E_Cntrl","OC","S","BAF","DC","EM","MM","ISO-TP","-";
BA_DEF_ BO_  "DiagResponse" ENUM  "No","Yes";
BA_DEF_ BO_  "NmMessage" ENUM  "No","Yes";
BA_DEF_ BO_  "GenMsgSendType" ENUM  "Cyclic","NotUsed","NotUsed","NotUsed","NotUsed","NotUsed","NotUsed","NotUsed","NoMsgSendType";
BA_DEF_ BO_  "GenMsgNrOfRepetition" INT 0 255;
BA_DEF_ BO_  "GenMsgILSupport" ENUM  "No","Yes";
BA_DEF_ BO_  "GenMsgCycleTimeFast" INT 0 65535;
BA_DEF_ BO_  "GenMsgCycleTime" INT 0 65535;
BA_DEF_ BO_  "GenMsgDelayTime" INT 0 65535;
BA_DEF_ BO_  "NmAsrMessage" ENUM  "No","Yes";
BA_DEF_ BO_  "DiagState" ENUM  "No","Yes";
BA_DEF_ BO_  "DiagConnection" HEX 0 65535;
BA_DEF_ BO_  "VFrameFormat" ENUM  "StandardCAN","ExtendedCAN","reserved","reserved","reserved","reserved","reserved","reserved","reserved","reserved","reserved","reserved","reserved","reserved","StandardCAN_FD","ExtendedCAN_FD";
BA_DEF_ BO_  "CANFD_BRS" ENUM  "No","Yes";
BA_DEF_ SG_  "SystemSignalLongSymbol" STRING ;
BA_DEF_DEF_  "GenSigStartValue" 0;
BA_DEF_DEF_  "GenSigInactiveValue" 0;
BA_DEF_DEF_  "GenSigSendType" "NoSigSendType";
BA_DEF_DEF_  "GenSigTimeoutTime_BSM" 2500;
BA_DEF_DEF_  "GenSigTimeoutTime_BSM2" 2500;
BA_DEF_DEF_  "GenSigTimeoutTime_CADM" 2500;
BA_DEF_DEF_  "GenSigTimeoutTime_CVADAS" 2500;
BA_DEF_DEF_  "GenSigTimeoutTime_ECM" 2500;
BA_DEF_DEF_  "GenSigTimeoutTime_EPS" 2500;
BA_DEF_DEF_  "GenSigTimeoutTime_EVCU2" 2500;
BA_DEF_DEF_  "GenSigTimeoutTime_ORC" 2500;
BA_DEF_DEF_  "DiagRequest" "No";
BA_DEF_DEF_  "Type" "-";
BA_DEF_DEF_  "DiagResponse" "No";
BA_DEF_DEF_  "NmMessage" "No";
BA_DEF_DEF_  "GenMsgSendType" "NoMsgSendType";
BA_DEF_DEF_  "GenMsgNrOfRepetition" 0;
BA_DEF_DEF_  "GenMsgILSupport" "No";
BA_DEF_DEF_  "GenMsgCycleTimeFast" 0;
BA_DEF_DEF_  "GenMsgCycleTime" 0;
BA_DEF_DEF_  "GenMsgDelayTime" 0;
BA_DEF_DEF_  "NmAsrMessage" "No";
BA_DEF_DEF_  "DiagState" "No";
BA_DEF_DEF_  "DiagConnection" 0;
BA_DEF_DEF_  "VFrameFormat" "StandardCAN_FD";
BA_DEF_DEF_  "CANFD_BRS" "No";
BA_DEF_DEF_  "SystemSignalLongSymbol" "";
BA_ "CANFD_BRS" BO_ 2654552167 1;
BA_ "GenMsgILSupport" BO_ 2654552167 1;
BA_ "GenMsgSendType" BO_ 2654552167 0;
BA_ "GenMsgCycleTime" BO_ 2654552167 1000;
BA_ "VFrameFormat" BO_ 2654552167 15;
BA_ "CANFD_BRS" BO_ 2654552168 1;
BA_ "GenMsgILSupport" BO_ 2654552168 1;
BA_ "GenMsgSendType" BO_ 2654552168 0;
BA_ "GenMsgCycleTime" BO_ 2654552168 1000;
BA_ "VFrameFormat" BO_ 2654552168 15;
BA_ "CANFD_BRS" BO_ 2654814278 1;
BA_ "GenMsgILSupport" BO_ 2654814278 1;
BA_ "VFrameFormat" BO_ 2654814278 15;
BA_ "CANFD_BRS" BO_ 2654552328 1;
BA_ "GenMsgILSupport" BO_ 2654552328 1;
BA_ "VFrameFormat" BO_ 2654552328 15;
BA_ "CANFD_BRS" BO_ 2654552329 1;
BA_ "GenMsgILSupport" BO_ 2654552329 1;
BA_ "VFrameFormat" BO_ 2654552329 15;
BA_ "Type" BO_ 1456 3;
BA_ "GenMsgSendType" BO_ 1456 0;
BA_ "GenMsgILSupport" BO_ 1456 1;
BA_ "GenMsgCycleTime" BO_ 1456 100;
BA_ "GenMsgDelayTime" BO_ 1456 20;
BA_ "CANFD_BRS" BO_ 1456 1;
BA_ "Type" BO_ 280 1;
BA_ "GenMsgSendType" BO_ 280 0;
BA_ "GenMsgILSupport" BO_ 280 1;
BA_ "GenMsgCycleTime" BO_ 280 10;
BA_ "CANFD_BRS" BO_ 280 1;
BA_ "Type" BO_ 299 1;
BA_ "GenMsgSendType" BO_ 299 0;
BA_ "GenMsgILSupport" BO_ 299 1;
BA_ "GenMsgCycleTime" BO_ 299 10;
BA_ "CANFD_BRS" BO_ 299 1;
BA_ "Type" BO_ 730 1;
BA_ "GenMsgSendType" BO_ 730 0;
BA_ "GenMsgILSupport" BO_ 730 1;
BA_ "GenMsgCycleTime" BO_ 730 40;
BA_ "CANFD_BRS" BO_ 730 1;
BA_ "Type" BO_ 734 1;
BA_ "GenMsgSendType" BO_ 734 0;
BA_ "GenMsgILSupport" BO_ 734 1;
BA_ "GenMsgCycleTime" BO_ 734 40;
BA_ "CANFD_BRS" BO_ 734 1;
BA_ "Type" BO_ 204 1;
BA_ "GenMsgSendType" BO_ 204 0;
BA_ "GenMsgILSupport" BO_ 204 1;
BA_ "GenMsgCycleTime" BO_ 204 10;
BA_ "CANFD_BRS" BO_ 204 1;
BA_ "Type" BO_ 513 1;
BA_ "GenMsgSendType" BO_ 513 0;
BA_ "GenMsgILSupport" BO_ 513 1;
BA_ "GenMsgCycleTime" BO_ 513 20;
BA_ "CANFD_BRS" BO_ 513 1;
BA_ "Type" BO_ 258 1;
BA_ "GenMsgSendType" BO_ 258 0;
BA_ "GenMsgILSupport" BO_ 258 1;
BA_ "GenMsgCycleTime" BO_ 258 10;
BA_ "CANFD_BRS" BO_ 258 1;
BA_ "Type" BO_ 259 1;
BA_ "GenMsgSendType" BO_ 259 0;
BA_ "GenMsgILSupport" BO_ 259 1;
BA_ "GenMsgCycleTime" BO_ 259 10;
BA_ "CANFD_BRS" BO_ 259 1;
BA_ "Type" BO_ 609 3;
BA_ "GenMsgSendType" BO_ 609 0;
BA_ "GenMsgNrOfRepetition" BO_ 609 2;
BA_ "GenMsgILSupport" BO_ 609 1;
BA_ "GenMsgCycleTimeFast" BO_ 609 20;
BA_ "GenMsgCycleTime" BO_ 609 100;
BA_ "CANFD_BRS" BO_ 609 1;
BA_ "GenSigSendType" SG_ 2654552167 FD14_averageIllumination 1;
BA_ "GenSigSendType" SG_ 2654552167 FD14_hitchCalibrationAngle 1;
BA_ "GenSigSendType" SG_ 2654552167 FD14_rightCalibrationAngle 1;
BA_ "GenSigSendType" SG_ 2654552167 FD14_leftCalibrationAngle 1;
BA_ "GenSigSendType" SG_ 2654552167 FD14_Trailer_tracking_confidence 1;
BA_ "GenSigSendType" SG_ 2654552167 FD14_Trailer_Recognition_Confide 1;
BA_ "SystemSignalLongSymbol" SG_ 2654552167 FD14_Trailer_Recognition_Confide "FD14_Trailer_Recognition_Confidence";
BA_ "GenSigSendType" SG_ 2654552167 FD14_OBTLRecalibrate 1;
BA_ "GenSigSendType" SG_ 2654552167 FD14_Presentinfo 1;
BA_ "GenSigSendType" SG_ 2654552167 FD14_RecognitionInfo 1;
BA_ "GenSigSendType" SG_ 2654552167 FD14_trailerCalibrationDelay 1;
BA_ "GenSigSendType" SG_ 2654552167 FD14_trailerCalibrationCount 1;
BA_ "GenSigSendType" SG_ 2654552167 FD14_TrailerCalFailInfo 1;
BA_ "GenSigStartValue" SG_ 2654552167 FD14_Trailercalinfo 2;
BA_ "GenSigSendType" SG_ 2654552167 FD14_Trailercalinfo 1;
BA_ "GenSigSendType" SG_ 2654552167 FD14_turnaroundSubState 1;
BA_ "GenSigSendType" SG_ 2654552167 FD14_calibrationCompleted 1;
BA_ "GenSigSendType" SG_ 2654552167 FD14_JackknifeThrAngle 1;
BA_ "GenSigSendType" SG_ 2654552167 FD14_JackknifeAngle 1;
BA_ "GenSigStartValue" SG_ 2654552167 FD14_hitchLength 100000;
BA_ "GenSigSendType" SG_ 2654552167 FD14_hitchLength 1;
BA_ "GenSigSendType" SG_ 2654552167 FD14_curState 1;
BA_ "GenSigStartValue" SG_ 2654552167 FD14_CurrentTrailer_ID 6;
BA_ "GenSigSendType" SG_ 2654552167 FD14_CurrentTrailer_ID 1;
BA_ "GenSigSendType" SG_ 2654552167 FD14_calibrationSubState 1;
BA_ "GenSigSendType" SG_ 2654552167 FD14_TADAngleRate 1;
BA_ "GenSigStartValue" SG_ 2654552167 FD14_TrailerAngleSign 3;
BA_ "GenSigSendType" SG_ 2654552167 FD14_TrailerAngleSign 1;
BA_ "GenSigSendType" SG_ 2654552167 FD14_trailerAngle 1;
BA_ "GenSigSendType" SG_ 2654552168 FD14_m_QM_FID_TRSC_ASCMDef 1;
BA_ "GenSigSendType" SG_ 2654552168 FD14_m_QM_FID_TRSC_LIMITED_DefVi 1;
BA_ "SystemSignalLongSymbol" SG_ 2654552168 FD14_m_QM_FID_TRSC_LIMITED_DefVi "FD14_m_QM_FID_TRSC_LIMITED_DefView";
BA_ "GenSigSendType" SG_ 2654552168 FD14_m_QM_FID_TRSC_CAM_CAL_ABORT 1;
BA_ "GenSigSendType" SG_ 2654552168 FD14_m_QM_FID_TRSC_LIMITED_View 1;
BA_ "GenSigSendType" SG_ 2654552168 FD14_m_QM_FID_TRSC_DISABLED 1;
BA_ "GenSigSendType" SG_ 2654814278 FD14_USS_MPAZoneB03 1;
BA_ "GenSigSendType" SG_ 2654814278 FD14_USS_MPAZoneB02 1;
BA_ "GenSigSendType" SG_ 2654814278 FD14_USS_MPAZoneB01 1;
BA_ "GenSigSendType" SG_ 2654814278 FD14_USS_MPAZoneB00 1;
BA_ "GenSigSendType" SG_ 2654814278 FD14_USS_MPAZoneF03 1;
BA_ "GenSigSendType" SG_ 2654814278 FD14_USS_MPAZoneF02 1;
BA_ "GenSigSendType" SG_ 2654814278 FD14_USS_MPAZoneF01 1;
BA_ "GenSigSendType" SG_ 2654814278 FD14_USS_MPAZoneF00 1;
BA_ "GenSigSendType" SG_ 2654552328 FD14_stUSSParkingSlot1DataSlotID 1;
BA_ "GenSigSendType" SG_ 2654552328 FD14_stUSSParkingSlot4DataSlotSi 1;
BA_ "SystemSignalLongSymbol" SG_ 2654552328 FD14_stUSSParkingSlot4DataSlotSi "FD14_stUSSParkingSlot4DataSlotSide";
BA_ "GenSigSendType" SG_ 2654552328 FD14_stUSSParkingSlot1DataSlotSi 1;
BA_ "SystemSignalLongSymbol" SG_ 2654552328 FD14_stUSSParkingSlot1DataSlotSi "FD14_stUSSParkingSlot1DataSlotSide";
BA_ "GenSigSendType" SG_ 2654552328 FD14_stUSSParkingSlot4SlotType 1;
BA_ "GenSigSendType" SG_ 2654552328 FD14_stUSSParkingSlot1SlotType 1;
BA_ "GenSigSendType" SG_ 2654552328 FD14_stUSSParkingSlot4RearRightY 1;
BA_ "GenSigSendType" SG_ 2654552328 FD14_stUSSParkingSlot4FrontLeftY 1;
BA_ "GenSigSendType" SG_ 2654552328 FD14_stUSSParkingSlot1RearRightY 1;
BA_ "GenSigSendType" SG_ 2654552328 FD14_stUSSParkingSlot1FrontLeftY 1;
BA_ "GenSigSendType" SG_ 2654552328 FD14_stUSSParkingSlot4RearRightX 1;
BA_ "GenSigSendType" SG_ 2654552328 FD14_stUSSParkingSlot4FrontLeftX 1;
BA_ "GenSigSendType" SG_ 2654552328 FD14_stUSSParkingSlot1RearRightX 1;
BA_ "GenSigSendType" SG_ 2654552328 FD14_stUSSParkingSlot1FrontLeftX 1;
BA_ "GenSigSendType" SG_ 2654552328 FD14_stUSSParkingSlot6SlotValid 1;
BA_ "GenSigSendType" SG_ 2654552328 FD14_stUSSParkingSlot5SlotValid 1;
BA_ "GenSigSendType" SG_ 2654552328 FD14_stUSSParkingSlot4SlotValid 1;
BA_ "GenSigSendType" SG_ 2654552328 FD14_stUSSParkingSlot3SlotValid 1;
BA_ "GenSigSendType" SG_ 2654552328 FD14_stUSSParkingSlot2SlotValid 1;
BA_ "GenSigSendType" SG_ 2654552328 FD14_stUSSParkingSlot1SlotValid 1;
BA_ "GenSigSendType" SG_ 2654552328 FD14_isUSSInitSuccess_b 1;
BA_ "GenSigSendType" SG_ 2654552329 FD14_stnumPointsR 1;
BA_ "GenSigSendType" SG_ 2654552329 FD14_stnumPointsL 1;
BA_ "GenSigSendType" SG_ 2654552329 FD14_stRightObjectList4Valid 1;
BA_ "GenSigSendType" SG_ 2654552329 FD14_stRightObjectList3Valid 1;
BA_ "GenSigSendType" SG_ 2654552329 FD14_stRightObjectList2Valid 1;
BA_ "GenSigSendType" SG_ 2654552329 FD14_stRightObjectList1Valid 1;
BA_ "GenSigSendType" SG_ 2654552329 FD14_stLeftObjectList4Valid 1;
BA_ "GenSigSendType" SG_ 2654552329 FD14_stLeftObjectList3Valid 1;
BA_ "GenSigSendType" SG_ 2654552329 FD14_stLeftObjectList2Valid 1;
BA_ "GenSigSendType" SG_ 2654552329 FD14_stLeftObjectList1Valid 1;
BA_ "GenSigSendType" SG_ 2654552329 FD14_stUSSLockedSlotDataSlotVali 1;
BA_ "SystemSignalLongSymbol" SG_ 2654552329 FD14_stUSSLockedSlotDataSlotVali "FD14_stUSSLockedSlotDataSlotValid";
BA_ "GenSigSendType" SG_ 2654552329 FD14_stUSSLockedSlotDataSlotID 1;
BA_ "GenSigSendType" SG_ 2654552329 FD14_stUSSLockedSlotDataSlotSide 1;
BA_ "GenSigSendType" SG_ 2654552329 FD14_stUSSLockedSlotDataSlotType 1;
BA_ "GenSigSendType" SG_ 2654552329 FD14_stUSSLockedSlotDataRearRigh 1;
BA_ "SystemSignalLongSymbol" SG_ 2654552329 FD14_stUSSLockedSlotDataRearRigh "FD14_stUSSLockedSlotDataRearRightY";
BA_ "GenSigSendType" SG_ 2654552329 FD14_stUSSLockedSlotDataFrontLef 1;
BA_ "SystemSignalLongSymbol" SG_ 2654552329 FD14_stUSSLockedSlotDataFrontLef "FD14_stUSSLockedSlotDataFrontLeftY";
BA_ "GenSigSendType" SG_ 2654552329 FD14_stUSSLockedSlotDataRea_0000 1;
BA_ "SystemSignalLongSymbol" SG_ 2654552329 FD14_stUSSLockedSlotDataRea_0000 "FD14_stUSSLockedSlotDataRearRightX";
BA_ "GenSigSendType" SG_ 2654552329 FD14_stUSSLockedSlotDataFro_0000 1;
BA_ "SystemSignalLongSymbol" SG_ 2654552329 FD14_stUSSLockedSlotDataFro_0000 "FD14_stUSSLockedSlotDataFrontLeftX";
BA_ "GenSigSendType" SG_ 1456 FD14_ACC_Blind 3;
BA_ "GenSigTimeoutTime_BSM2" SG_ 1456 FD14_ACC_Blind 0;
BA_ "GenSigTimeoutTime_CADM" SG_ 1456 FD14_ACC_Blind 0;
BA_ "GenSigTimeoutTime_CVADAS" SG_ 1456 FD14_ACC_Blind 0;
BA_ "GenSigTimeoutTime_ECM" SG_ 1456 FD14_ACC_Blind 0;
BA_ "GenSigTimeoutTime_EPS" SG_ 1456 FD14_ACC_Blind 0;
BA_ "GenSigSendType" SG_ 1456 FD14_ACC_DispPopupSts 3;
BA_ "GenSigTimeoutTime_BSM" SG_ 1456 FD14_ACC_DispPopupSts 0;
BA_ "GenSigTimeoutTime_BSM2" SG_ 1456 FD14_ACC_DispPopupSts 0;
BA_ "GenSigTimeoutTime_CADM" SG_ 1456 FD14_ACC_DispPopupSts 0;
BA_ "GenSigTimeoutTime_CVADAS" SG_ 1456 FD14_ACC_DispPopupSts 0;
BA_ "GenSigTimeoutTime_ECM" SG_ 1456 FD14_ACC_DispPopupSts 0;
BA_ "GenSigTimeoutTime_EPS" SG_ 1456 FD14_ACC_DispPopupSts 0;
BA_ "GenSigSendType" SG_ 1456 FD14_ACC_FailSts 3;
BA_ "GenSigTimeoutTime_BSM2" SG_ 1456 FD14_ACC_FailSts 0;
BA_ "GenSigTimeoutTime_CADM" SG_ 1456 FD14_ACC_FailSts 0;
BA_ "GenSigTimeoutTime_CVADAS" SG_ 1456 FD14_ACC_FailSts 0;
BA_ "GenSigTimeoutTime_ECM" SG_ 1456 FD14_ACC_FailSts 0;
BA_ "GenSigTimeoutTime_EPS" SG_ 1456 FD14_ACC_FailSts 0;
BA_ "GenSigSendType" SG_ 1456 FD14_ACC_Limit_Fail 3;
BA_ "GenSigTimeoutTime_BSM" SG_ 1456 FD14_ACC_Limit_Fail 0;
BA_ "GenSigTimeoutTime_BSM2" SG_ 1456 FD14_ACC_Limit_Fail 0;
BA_ "GenSigTimeoutTime_CADM" SG_ 1456 FD14_ACC_Limit_Fail 0;
BA_ "GenSigTimeoutTime_CVADAS" SG_ 1456 FD14_ACC_Limit_Fail 0;
BA_ "GenSigTimeoutTime_ECM" SG_ 1456 FD14_ACC_Limit_Fail 0;
BA_ "GenSigTimeoutTime_EPS" SG_ 1456 FD14_ACC_Limit_Fail 0;
BA_ "GenSigSendType" SG_ 1456 FD14_ACC_Limited 3;
BA_ "GenSigTimeoutTime_BSM" SG_ 1456 FD14_ACC_Limited 0;
BA_ "GenSigTimeoutTime_BSM2" SG_ 1456 FD14_ACC_Limited 0;
BA_ "GenSigTimeoutTime_CADM" SG_ 1456 FD14_ACC_Limited 0;
BA_ "GenSigTimeoutTime_CVADAS" SG_ 1456 FD14_ACC_Limited 0;
BA_ "GenSigTimeoutTime_ECM" SG_ 1456 FD14_ACC_Limited 0;
BA_ "GenSigTimeoutTime_EPS" SG_ 1456 FD14_ACC_Limited 0;
BA_ "GenSigSendType" SG_ 1456 FD14_ACC_Set_Speed_Strike 3;
BA_ "GenSigTimeoutTime_BSM" SG_ 1456 FD14_ACC_Set_Speed_Strike 0;
BA_ "GenSigTimeoutTime_BSM2" SG_ 1456 FD14_ACC_Set_Speed_Strike 0;
BA_ "GenSigTimeoutTime_CADM" SG_ 1456 FD14_ACC_Set_Speed_Strike 0;
BA_ "GenSigTimeoutTime_CVADAS" SG_ 1456 FD14_ACC_Set_Speed_Strike 0;
BA_ "GenSigTimeoutTime_ECM" SG_ 1456 FD14_ACC_Set_Speed_Strike 0;
BA_ "GenSigTimeoutTime_EPS" SG_ 1456 FD14_ACC_Set_Speed_Strike 0;
BA_ "GenSigTimeoutTime_ORC" SG_ 1456 FD14_ACC_Set_Speed_Strike 0;
BA_ "GenSigSendType" SG_ 1456 FD14_AEB_Blind 3;
BA_ "GenSigTimeoutTime_BSM" SG_ 1456 FD14_AEB_Blind 0;
BA_ "GenSigTimeoutTime_BSM2" SG_ 1456 FD14_AEB_Blind 0;
BA_ "GenSigTimeoutTime_CADM" SG_ 1456 FD14_AEB_Blind 0;
BA_ "GenSigTimeoutTime_CVADAS" SG_ 1456 FD14_AEB_Blind 0;
BA_ "GenSigTimeoutTime_ECM" SG_ 1456 FD14_AEB_Blind 0;
BA_ "GenSigTimeoutTime_EPS" SG_ 1456 FD14_AEB_Blind 0;
BA_ "GenSigSendType" SG_ 1456 FD14_AEB_DispPopupSts 3;
BA_ "GenSigTimeoutTime_BSM" SG_ 1456 FD14_AEB_DispPopupSts 0;
BA_ "GenSigTimeoutTime_BSM2" SG_ 1456 FD14_AEB_DispPopupSts 0;
BA_ "GenSigTimeoutTime_CADM" SG_ 1456 FD14_AEB_DispPopupSts 0;
BA_ "GenSigTimeoutTime_CVADAS" SG_ 1456 FD14_AEB_DispPopupSts 0;
BA_ "GenSigTimeoutTime_ECM" SG_ 1456 FD14_AEB_DispPopupSts 0;
BA_ "GenSigTimeoutTime_EPS" SG_ 1456 FD14_AEB_DispPopupSts 0;
BA_ "GenSigSendType" SG_ 1456 FD14_AEB_FailSts 3;
BA_ "GenSigTimeoutTime_CADM" SG_ 1456 FD14_AEB_FailSts 0;
BA_ "GenSigTimeoutTime_CVADAS" SG_ 1456 FD14_AEB_FailSts 0;
BA_ "GenSigTimeoutTime_ECM" SG_ 1456 FD14_AEB_FailSts 0;
BA_ "GenSigTimeoutTime_EPS" SG_ 1456 FD14_AEB_FailSts 0;
BA_ "GenSigSendType" SG_ 1456 FD14_AEB_Limit_Fail 3;
BA_ "GenSigTimeoutTime_BSM" SG_ 1456 FD14_AEB_Limit_Fail 0;
BA_ "GenSigTimeoutTime_BSM2" SG_ 1456 FD14_AEB_Limit_Fail 0;
BA_ "GenSigTimeoutTime_CADM" SG_ 1456 FD14_AEB_Limit_Fail 0;
BA_ "GenSigTimeoutTime_CVADAS" SG_ 1456 FD14_AEB_Limit_Fail 0;
BA_ "GenSigTimeoutTime_ECM" SG_ 1456 FD14_AEB_Limit_Fail 0;
BA_ "GenSigTimeoutTime_EPS" SG_ 1456 FD14_AEB_Limit_Fail 0;
BA_ "GenSigSendType" SG_ 1456 FD14_AEB_Limited 3;
BA_ "GenSigTimeoutTime_BSM2" SG_ 1456 FD14_AEB_Limited 0;
BA_ "GenSigTimeoutTime_CADM" SG_ 1456 FD14_AEB_Limited 0;
BA_ "GenSigTimeoutTime_CVADAS" SG_ 1456 FD14_AEB_Limited 0;
BA_ "GenSigTimeoutTime_ECM" SG_ 1456 FD14_AEB_Limited 0;
BA_ "GenSigTimeoutTime_EPS" SG_ 1456 FD14_AEB_Limited 0;
BA_ "GenSigSendType" SG_ 1456 FD14_BlindSpotLeftWarn 3;
BA_ "GenSigTimeoutTime_BSM" SG_ 1456 FD14_BlindSpotLeftWarn 0;
BA_ "GenSigTimeoutTime_BSM2" SG_ 1456 FD14_BlindSpotLeftWarn 0;
BA_ "GenSigTimeoutTime_CADM" SG_ 1456 FD14_BlindSpotLeftWarn 0;
BA_ "GenSigTimeoutTime_CVADAS" SG_ 1456 FD14_BlindSpotLeftWarn 0;
BA_ "GenSigTimeoutTime_ECM" SG_ 1456 FD14_BlindSpotLeftWarn 0;
BA_ "GenSigTimeoutTime_EPS" SG_ 1456 FD14_BlindSpotLeftWarn 0;
BA_ "GenSigSendType" SG_ 1456 FD14_BlindSpotRightWarn 3;
BA_ "GenSigTimeoutTime_BSM" SG_ 1456 FD14_BlindSpotRightWarn 0;
BA_ "GenSigTimeoutTime_BSM2" SG_ 1456 FD14_BlindSpotRightWarn 0;
BA_ "GenSigTimeoutTime_CADM" SG_ 1456 FD14_BlindSpotRightWarn 0;
BA_ "GenSigTimeoutTime_CVADAS" SG_ 1456 FD14_BlindSpotRightWarn 0;
BA_ "GenSigTimeoutTime_ECM" SG_ 1456 FD14_BlindSpotRightWarn 0;
BA_ "GenSigTimeoutTime_EPS" SG_ 1456 FD14_BlindSpotRightWarn 0;
BA_ "GenSigSendType" SG_ 1456 FD14_BSS_Blind_RQSts 3;
BA_ "GenSigTimeoutTime_BSM" SG_ 1456 FD14_BSS_Blind_RQSts 0;
BA_ "GenSigTimeoutTime_BSM2" SG_ 1456 FD14_BSS_Blind_RQSts 0;
BA_ "GenSigTimeoutTime_CADM" SG_ 1456 FD14_BSS_Blind_RQSts 0;
BA_ "GenSigTimeoutTime_CVADAS" SG_ 1456 FD14_BSS_Blind_RQSts 0;
BA_ "GenSigTimeoutTime_ECM" SG_ 1456 FD14_BSS_Blind_RQSts 0;
BA_ "GenSigTimeoutTime_EPS" SG_ 1456 FD14_BSS_Blind_RQSts 0;
BA_ "GenSigSendType" SG_ 1456 FD14_BSS_CFG_STATSts 3;
BA_ "GenSigTimeoutTime_BSM" SG_ 1456 FD14_BSS_CFG_STATSts 0;
BA_ "GenSigTimeoutTime_BSM2" SG_ 1456 FD14_BSS_CFG_STATSts 0;
BA_ "GenSigTimeoutTime_CADM" SG_ 1456 FD14_BSS_CFG_STATSts 0;
BA_ "GenSigTimeoutTime_CVADAS" SG_ 1456 FD14_BSS_CFG_STATSts 0;
BA_ "GenSigTimeoutTime_ECM" SG_ 1456 FD14_BSS_CFG_STATSts 0;
BA_ "GenSigTimeoutTime_EPS" SG_ 1456 FD14_BSS_CFG_STATSts 0;
BA_ "GenSigSendType" SG_ 1456 FD14_BSS_SRV_RQSts 3;
BA_ "GenSigTimeoutTime_BSM" SG_ 1456 FD14_BSS_SRV_RQSts 0;
BA_ "GenSigTimeoutTime_BSM2" SG_ 1456 FD14_BSS_SRV_RQSts 0;
BA_ "GenSigTimeoutTime_CADM" SG_ 1456 FD14_BSS_SRV_RQSts 0;
BA_ "GenSigTimeoutTime_CVADAS" SG_ 1456 FD14_BSS_SRV_RQSts 0;
BA_ "GenSigTimeoutTime_ECM" SG_ 1456 FD14_BSS_SRV_RQSts 0;
BA_ "GenSigTimeoutTime_EPS" SG_ 1456 FD14_BSS_SRV_RQSts 0;
BA_ "GenSigSendType" SG_ 1456 FD14_Chime_Priority 3;
BA_ "GenSigTimeoutTime_BSM" SG_ 1456 FD14_Chime_Priority 0;
BA_ "GenSigTimeoutTime_BSM2" SG_ 1456 FD14_Chime_Priority 0;
BA_ "GenSigTimeoutTime_CADM" SG_ 1456 FD14_Chime_Priority 0;
BA_ "GenSigTimeoutTime_CVADAS" SG_ 1456 FD14_Chime_Priority 0;
BA_ "GenSigTimeoutTime_ECM" SG_ 1456 FD14_Chime_Priority 0;
BA_ "GenSigTimeoutTime_EPS" SG_ 1456 FD14_Chime_Priority 0;
BA_ "GenSigTimeoutTime_ORC" SG_ 1456 FD14_Chime_Priority 0;
BA_ "GenSigSendType" SG_ 1456 FD14_Chime_RepRate 3;
BA_ "GenSigTimeoutTime_BSM" SG_ 1456 FD14_Chime_RepRate 0;
BA_ "GenSigTimeoutTime_BSM2" SG_ 1456 FD14_Chime_RepRate 0;
BA_ "GenSigTimeoutTime_CADM" SG_ 1456 FD14_Chime_RepRate 0;
BA_ "GenSigTimeoutTime_CVADAS" SG_ 1456 FD14_Chime_RepRate 0;
BA_ "GenSigTimeoutTime_ECM" SG_ 1456 FD14_Chime_RepRate 0;
BA_ "GenSigTimeoutTime_EPS" SG_ 1456 FD14_Chime_RepRate 0;
BA_ "GenSigTimeoutTime_ORC" SG_ 1456 FD14_Chime_RepRate 0;
BA_ "GenSigSendType" SG_ 1456 FD14_Chime_TypSts 3;
BA_ "GenSigTimeoutTime_BSM" SG_ 1456 FD14_Chime_TypSts 0;
BA_ "GenSigTimeoutTime_BSM2" SG_ 1456 FD14_Chime_TypSts 0;
BA_ "GenSigTimeoutTime_CADM" SG_ 1456 FD14_Chime_TypSts 0;
BA_ "GenSigTimeoutTime_CVADAS" SG_ 1456 FD14_Chime_TypSts 0;
BA_ "GenSigTimeoutTime_ECM" SG_ 1456 FD14_Chime_TypSts 0;
BA_ "GenSigTimeoutTime_EPS" SG_ 1456 FD14_Chime_TypSts 0;
BA_ "GenSigTimeoutTime_CADM" SG_ 1456 FD14_CRC_ADAS_FD_HMI 0;
BA_ "GenSigTimeoutTime_CVADAS" SG_ 1456 FD14_CRC_ADAS_FD_HMI 0;
BA_ "GenSigTimeoutTime_ORC" SG_ 1456 FD14_CRC_ADAS_FD_HMI 0;
BA_ "GenSigSendType" SG_ 1456 FD14_DDD_DispPopupSts 3;
BA_ "GenSigTimeoutTime_BSM" SG_ 1456 FD14_DDD_DispPopupSts 0;
BA_ "GenSigTimeoutTime_BSM2" SG_ 1456 FD14_DDD_DispPopupSts 0;
BA_ "GenSigTimeoutTime_CADM" SG_ 1456 FD14_DDD_DispPopupSts 0;
BA_ "GenSigTimeoutTime_CVADAS" SG_ 1456 FD14_DDD_DispPopupSts 0;
BA_ "GenSigTimeoutTime_ECM" SG_ 1456 FD14_DDD_DispPopupSts 0;
BA_ "GenSigTimeoutTime_EPS" SG_ 1456 FD14_DDD_DispPopupSts 0;
BA_ "GenSigSendType" SG_ 1456 FD14_DDD_FailSts 3;
BA_ "GenSigTimeoutTime_BSM" SG_ 1456 FD14_DDD_FailSts 0;
BA_ "GenSigTimeoutTime_BSM2" SG_ 1456 FD14_DDD_FailSts 0;
BA_ "GenSigTimeoutTime_CADM" SG_ 1456 FD14_DDD_FailSts 0;
BA_ "GenSigTimeoutTime_CVADAS" SG_ 1456 FD14_DDD_FailSts 0;
BA_ "GenSigTimeoutTime_ECM" SG_ 1456 FD14_DDD_FailSts 0;
BA_ "GenSigTimeoutTime_EPS" SG_ 1456 FD14_DDD_FailSts 0;
BA_ "GenSigTimeoutTime_ORC" SG_ 1456 FD14_DDD_FailSts 0;
BA_ "GenSigSendType" SG_ 1456 FD14_DisplaySts_ACC 3;
BA_ "GenSigTimeoutTime_BSM" SG_ 1456 FD14_DisplaySts_ACC 0;
BA_ "GenSigTimeoutTime_BSM2" SG_ 1456 FD14_DisplaySts_ACC 0;
BA_ "GenSigTimeoutTime_CADM" SG_ 1456 FD14_DisplaySts_ACC 0;
BA_ "GenSigTimeoutTime_CVADAS" SG_ 1456 FD14_DisplaySts_ACC 0;
BA_ "GenSigTimeoutTime_ECM" SG_ 1456 FD14_DisplaySts_ACC 0;
BA_ "GenSigTimeoutTime_EPS" SG_ 1456 FD14_DisplaySts_ACC 0;
BA_ "GenSigSendType" SG_ 1456 FD14_DisplaySts_Curve 3;
BA_ "GenSigTimeoutTime_BSM" SG_ 1456 FD14_DisplaySts_Curve 0;
BA_ "GenSigTimeoutTime_BSM2" SG_ 1456 FD14_DisplaySts_Curve 0;
BA_ "GenSigTimeoutTime_CADM" SG_ 1456 FD14_DisplaySts_Curve 0;
BA_ "GenSigTimeoutTime_CVADAS" SG_ 1456 FD14_DisplaySts_Curve 0;
BA_ "GenSigTimeoutTime_ECM" SG_ 1456 FD14_DisplaySts_Curve 0;
BA_ "GenSigTimeoutTime_EPS" SG_ 1456 FD14_DisplaySts_Curve 0;
BA_ "GenSigTimeoutTime_ORC" SG_ 1456 FD14_DisplaySts_Curve 0;
BA_ "GenSigSendType" SG_ 1456 FD14_DisplaySts_OFF 3;
BA_ "GenSigTimeoutTime_BSM" SG_ 1456 FD14_DisplaySts_OFF 0;
BA_ "GenSigTimeoutTime_BSM2" SG_ 1456 FD14_DisplaySts_OFF 0;
BA_ "GenSigTimeoutTime_CADM" SG_ 1456 FD14_DisplaySts_OFF 0;
BA_ "GenSigTimeoutTime_CVADAS" SG_ 1456 FD14_DisplaySts_OFF 0;
BA_ "GenSigTimeoutTime_ECM" SG_ 1456 FD14_DisplaySts_OFF 0;
BA_ "GenSigTimeoutTime_EPS" SG_ 1456 FD14_DisplaySts_OFF 0;
BA_ "GenSigTimeoutTime_ORC" SG_ 1456 FD14_DisplaySts_OFF 0;
BA_ "GenSigSendType" SG_ 1456 FD14_DisplaySts_Veh 3;
BA_ "GenSigTimeoutTime_BSM" SG_ 1456 FD14_DisplaySts_Veh 0;
BA_ "GenSigTimeoutTime_BSM2" SG_ 1456 FD14_DisplaySts_Veh 0;
BA_ "GenSigTimeoutTime_CADM" SG_ 1456 FD14_DisplaySts_Veh 0;
BA_ "GenSigTimeoutTime_CVADAS" SG_ 1456 FD14_DisplaySts_Veh 0;
BA_ "GenSigTimeoutTime_ECM" SG_ 1456 FD14_DisplaySts_Veh 0;
BA_ "GenSigTimeoutTime_EPS" SG_ 1456 FD14_DisplaySts_Veh 0;
BA_ "GenSigTimeoutTime_ORC" SG_ 1456 FD14_DisplaySts_Veh 0;
BA_ "GenSigSendType" SG_ 1456 FD14_Driver_Model 3;
BA_ "GenSigTimeoutTime_BSM" SG_ 1456 FD14_Driver_Model 0;
BA_ "GenSigTimeoutTime_BSM2" SG_ 1456 FD14_Driver_Model 0;
BA_ "GenSigTimeoutTime_CADM" SG_ 1456 FD14_Driver_Model 0;
BA_ "GenSigTimeoutTime_CVADAS" SG_ 1456 FD14_Driver_Model 0;
BA_ "GenSigTimeoutTime_ECM" SG_ 1456 FD14_Driver_Model 0;
BA_ "GenSigTimeoutTime_EPS" SG_ 1456 FD14_Driver_Model 0;
BA_ "GenSigSendType" SG_ 1456 FD14_FCW_Setting_Avail 3;
BA_ "GenSigTimeoutTime_BSM" SG_ 1456 FD14_FCW_Setting_Avail 0;
BA_ "GenSigTimeoutTime_BSM2" SG_ 1456 FD14_FCW_Setting_Avail 0;
BA_ "GenSigTimeoutTime_CADM" SG_ 1456 FD14_FCW_Setting_Avail 0;
BA_ "GenSigTimeoutTime_CVADAS" SG_ 1456 FD14_FCW_Setting_Avail 0;
BA_ "GenSigTimeoutTime_ECM" SG_ 1456 FD14_FCW_Setting_Avail 0;
BA_ "GenSigTimeoutTime_EPS" SG_ 1456 FD14_FCW_Setting_Avail 0;
BA_ "GenSigTimeoutTime_ORC" SG_ 1456 FD14_FCW_Setting_Avail 0;
BA_ "GenSigSendType" SG_ 1456 FD14_HAS_Blind 3;
BA_ "GenSigTimeoutTime_BSM" SG_ 1456 FD14_HAS_Blind 0;
BA_ "GenSigTimeoutTime_BSM2" SG_ 1456 FD14_HAS_Blind 0;
BA_ "GenSigTimeoutTime_CADM" SG_ 1456 FD14_HAS_Blind 0;
BA_ "GenSigTimeoutTime_CVADAS" SG_ 1456 FD14_HAS_Blind 0;
BA_ "GenSigTimeoutTime_ECM" SG_ 1456 FD14_HAS_Blind 0;
BA_ "GenSigTimeoutTime_EPS" SG_ 1456 FD14_HAS_Blind 0;
BA_ "GenSigSendType" SG_ 1456 FD14_HAS_Escalation_Sts 3;
BA_ "GenSigTimeoutTime_BSM" SG_ 1456 FD14_HAS_Escalation_Sts 0;
BA_ "GenSigTimeoutTime_BSM2" SG_ 1456 FD14_HAS_Escalation_Sts 0;
BA_ "GenSigTimeoutTime_CADM" SG_ 1456 FD14_HAS_Escalation_Sts 0;
BA_ "GenSigTimeoutTime_CVADAS" SG_ 1456 FD14_HAS_Escalation_Sts 0;
BA_ "GenSigTimeoutTime_ECM" SG_ 1456 FD14_HAS_Escalation_Sts 0;
BA_ "GenSigTimeoutTime_EPS" SG_ 1456 FD14_HAS_Escalation_Sts 0;
BA_ "GenSigTimeoutTime_ORC" SG_ 1456 FD14_HAS_Escalation_Sts 0;
BA_ "GenSigSendType" SG_ 1456 FD14_HAS_FailSts 3;
BA_ "GenSigTimeoutTime_BSM" SG_ 1456 FD14_HAS_FailSts 0;
BA_ "GenSigTimeoutTime_BSM2" SG_ 1456 FD14_HAS_FailSts 0;
BA_ "GenSigTimeoutTime_CADM" SG_ 1456 FD14_HAS_FailSts 0;
BA_ "GenSigTimeoutTime_CVADAS" SG_ 1456 FD14_HAS_FailSts 0;
BA_ "GenSigTimeoutTime_ECM" SG_ 1456 FD14_HAS_FailSts 0;
BA_ "GenSigTimeoutTime_EPS" SG_ 1456 FD14_HAS_FailSts 0;
BA_ "GenSigSendType" SG_ 1456 FD14_HAS_TelltaleSts 3;
BA_ "GenSigTimeoutTime_BSM" SG_ 1456 FD14_HAS_TelltaleSts 0;
BA_ "GenSigTimeoutTime_BSM2" SG_ 1456 FD14_HAS_TelltaleSts 0;
BA_ "GenSigTimeoutTime_CADM" SG_ 1456 FD14_HAS_TelltaleSts 0;
BA_ "GenSigTimeoutTime_CVADAS" SG_ 1456 FD14_HAS_TelltaleSts 0;
BA_ "GenSigTimeoutTime_ECM" SG_ 1456 FD14_HAS_TelltaleSts 0;
BA_ "GenSigTimeoutTime_EPS" SG_ 1456 FD14_HAS_TelltaleSts 0;
BA_ "GenSigSendType" SG_ 1456 FD14_HAS_TurnSignalRequest 3;
BA_ "GenSigTimeoutTime_BSM" SG_ 1456 FD14_HAS_TurnSignalRequest 0;
BA_ "GenSigTimeoutTime_BSM2" SG_ 1456 FD14_HAS_TurnSignalRequest 0;
BA_ "GenSigTimeoutTime_CADM" SG_ 1456 FD14_HAS_TurnSignalRequest 0;
BA_ "GenSigTimeoutTime_CVADAS" SG_ 1456 FD14_HAS_TurnSignalRequest 0;
BA_ "GenSigTimeoutTime_ECM" SG_ 1456 FD14_HAS_TurnSignalRequest 0;
BA_ "GenSigTimeoutTime_EPS" SG_ 1456 FD14_HAS_TurnSignalRequest 0;
BA_ "GenSigTimeoutTime_ORC" SG_ 1456 FD14_HAS_TurnSignalRequest 0;
BA_ "GenSigSendType" SG_ 1456 FD14_ICA_Blind 3;
BA_ "GenSigTimeoutTime_BSM" SG_ 1456 FD14_ICA_Blind 0;
BA_ "GenSigTimeoutTime_BSM2" SG_ 1456 FD14_ICA_Blind 0;
BA_ "GenSigTimeoutTime_CADM" SG_ 1456 FD14_ICA_Blind 0;
BA_ "GenSigTimeoutTime_CVADAS" SG_ 1456 FD14_ICA_Blind 0;
BA_ "GenSigTimeoutTime_ECM" SG_ 1456 FD14_ICA_Blind 0;
BA_ "GenSigTimeoutTime_EPS" SG_ 1456 FD14_ICA_Blind 0;
BA_ "GenSigTimeoutTime_ORC" SG_ 1456 FD14_ICA_Blind 0;
BA_ "GenSigSendType" SG_ 1456 FD14_Lane_DisplaySts_Left 3;
BA_ "GenSigTimeoutTime_BSM" SG_ 1456 FD14_Lane_DisplaySts_Left 0;
BA_ "GenSigTimeoutTime_BSM2" SG_ 1456 FD14_Lane_DisplaySts_Left 0;
BA_ "GenSigTimeoutTime_CADM" SG_ 1456 FD14_Lane_DisplaySts_Left 0;
BA_ "GenSigTimeoutTime_CVADAS" SG_ 1456 FD14_Lane_DisplaySts_Left 0;
BA_ "GenSigTimeoutTime_ECM" SG_ 1456 FD14_Lane_DisplaySts_Left 0;
BA_ "GenSigTimeoutTime_EPS" SG_ 1456 FD14_Lane_DisplaySts_Left 0;
BA_ "GenSigSendType" SG_ 1456 FD14_Lane_DisplaySts_Right 3;
BA_ "GenSigTimeoutTime_BSM" SG_ 1456 FD14_Lane_DisplaySts_Right 0;
BA_ "GenSigTimeoutTime_BSM2" SG_ 1456 FD14_Lane_DisplaySts_Right 0;
BA_ "GenSigTimeoutTime_CADM" SG_ 1456 FD14_Lane_DisplaySts_Right 0;
BA_ "GenSigTimeoutTime_CVADAS" SG_ 1456 FD14_Lane_DisplaySts_Right 0;
BA_ "GenSigTimeoutTime_ECM" SG_ 1456 FD14_Lane_DisplaySts_Right 0;
BA_ "GenSigTimeoutTime_EPS" SG_ 1456 FD14_Lane_DisplaySts_Right 0;
BA_ "GenSigSendType" SG_ 1456 FD14_Lane_DispPopupSts 3;
BA_ "GenSigTimeoutTime_BSM" SG_ 1456 FD14_Lane_DispPopupSts 0;
BA_ "GenSigTimeoutTime_BSM2" SG_ 1456 FD14_Lane_DispPopupSts 0;
BA_ "GenSigTimeoutTime_CADM" SG_ 1456 FD14_Lane_DispPopupSts 0;
BA_ "GenSigTimeoutTime_CVADAS" SG_ 1456 FD14_Lane_DispPopupSts 0;
BA_ "GenSigTimeoutTime_ECM" SG_ 1456 FD14_Lane_DispPopupSts 0;
BA_ "GenSigTimeoutTime_EPS" SG_ 1456 FD14_Lane_DispPopupSts 0;
BA_ "GenSigSendType" SG_ 1456 FD14_LF_Chime_RqSts 3;
BA_ "GenSigTimeoutTime_BSM" SG_ 1456 FD14_LF_Chime_RqSts 0;
BA_ "GenSigTimeoutTime_BSM2" SG_ 1456 FD14_LF_Chime_RqSts 0;
BA_ "GenSigTimeoutTime_CADM" SG_ 1456 FD14_LF_Chime_RqSts 0;
BA_ "GenSigTimeoutTime_CVADAS" SG_ 1456 FD14_LF_Chime_RqSts 0;
BA_ "GenSigTimeoutTime_ECM" SG_ 1456 FD14_LF_Chime_RqSts 0;
BA_ "GenSigTimeoutTime_EPS" SG_ 1456 FD14_LF_Chime_RqSts 0;
BA_ "GenSigSendType" SG_ 1456 FD14_LKA_Blind 3;
BA_ "GenSigTimeoutTime_BSM" SG_ 1456 FD14_LKA_Blind 0;
BA_ "GenSigTimeoutTime_BSM2" SG_ 1456 FD14_LKA_Blind 0;
BA_ "GenSigTimeoutTime_CADM" SG_ 1456 FD14_LKA_Blind 0;
BA_ "GenSigTimeoutTime_CVADAS" SG_ 1456 FD14_LKA_Blind 0;
BA_ "GenSigTimeoutTime_ECM" SG_ 1456 FD14_LKA_Blind 0;
BA_ "GenSigTimeoutTime_EPS" SG_ 1456 FD14_LKA_Blind 0;
BA_ "GenSigSendType" SG_ 1456 FD14_LKA_FailSts 3;
BA_ "GenSigTimeoutTime_BSM" SG_ 1456 FD14_LKA_FailSts 0;
BA_ "GenSigTimeoutTime_BSM2" SG_ 1456 FD14_LKA_FailSts 0;
BA_ "GenSigTimeoutTime_CADM" SG_ 1456 FD14_LKA_FailSts 0;
BA_ "GenSigTimeoutTime_CVADAS" SG_ 1456 FD14_LKA_FailSts 0;
BA_ "GenSigTimeoutTime_ECM" SG_ 1456 FD14_LKA_FailSts 0;
BA_ "GenSigTimeoutTime_EPS" SG_ 1456 FD14_LKA_FailSts 0;
BA_ "GenSigSendType" SG_ 1456 FD14_LKA_Status 3;
BA_ "GenSigTimeoutTime_BSM" SG_ 1456 FD14_LKA_Status 0;
BA_ "GenSigTimeoutTime_BSM2" SG_ 1456 FD14_LKA_Status 0;
BA_ "GenSigTimeoutTime_CADM" SG_ 1456 FD14_LKA_Status 0;
BA_ "GenSigTimeoutTime_CVADAS" SG_ 1456 FD14_LKA_Status 0;
BA_ "GenSigTimeoutTime_ECM" SG_ 1456 FD14_LKA_Status 0;
BA_ "GenSigTimeoutTime_EPS" SG_ 1456 FD14_LKA_Status 0;
BA_ "GenSigSendType" SG_ 1456 FD14_LR_Chime_RqSts 3;
BA_ "GenSigTimeoutTime_BSM" SG_ 1456 FD14_LR_Chime_RqSts 0;
BA_ "GenSigTimeoutTime_BSM2" SG_ 1456 FD14_LR_Chime_RqSts 0;
BA_ "GenSigTimeoutTime_CADM" SG_ 1456 FD14_LR_Chime_RqSts 0;
BA_ "GenSigTimeoutTime_CVADAS" SG_ 1456 FD14_LR_Chime_RqSts 0;
BA_ "GenSigTimeoutTime_ECM" SG_ 1456 FD14_LR_Chime_RqSts 0;
BA_ "GenSigTimeoutTime_EPS" SG_ 1456 FD14_LR_Chime_RqSts 0;
BA_ "GenSigTimeoutTime_CADM" SG_ 1456 FD14_MessageCounter_ADAS_FD_HMI 0;
BA_ "GenSigTimeoutTime_CVADAS" SG_ 1456 FD14_MessageCounter_ADAS_FD_HMI 0;
BA_ "GenSigTimeoutTime_ORC" SG_ 1456 FD14_MessageCounter_ADAS_FD_HMI 0;
BA_ "GenSigSendType" SG_ 1456 FD14_NCC_FailSts 3;
BA_ "GenSigTimeoutTime_BSM" SG_ 1456 FD14_NCC_FailSts 0;
BA_ "GenSigTimeoutTime_BSM2" SG_ 1456 FD14_NCC_FailSts 0;
BA_ "GenSigTimeoutTime_CADM" SG_ 1456 FD14_NCC_FailSts 0;
BA_ "GenSigTimeoutTime_CVADAS" SG_ 1456 FD14_NCC_FailSts 0;
BA_ "GenSigTimeoutTime_ECM" SG_ 1456 FD14_NCC_FailSts 0;
BA_ "GenSigTimeoutTime_EPS" SG_ 1456 FD14_NCC_FailSts 0;
BA_ "GenSigSendType" SG_ 1456 FD14_PEB_Setting_Avail 3;
BA_ "GenSigTimeoutTime_BSM" SG_ 1456 FD14_PEB_Setting_Avail 0;
BA_ "GenSigTimeoutTime_BSM2" SG_ 1456 FD14_PEB_Setting_Avail 0;
BA_ "GenSigTimeoutTime_CADM" SG_ 1456 FD14_PEB_Setting_Avail 0;
BA_ "GenSigTimeoutTime_CVADAS" SG_ 1456 FD14_PEB_Setting_Avail 0;
BA_ "GenSigTimeoutTime_ECM" SG_ 1456 FD14_PEB_Setting_Avail 0;
BA_ "GenSigTimeoutTime_EPS" SG_ 1456 FD14_PEB_Setting_Avail 0;
BA_ "GenSigTimeoutTime_ORC" SG_ 1456 FD14_PEB_Setting_Avail 0;
BA_ "GenSigSendType" SG_ 1456 FD14_RF_Chime_RqSts 3;
BA_ "GenSigTimeoutTime_BSM" SG_ 1456 FD14_RF_Chime_RqSts 0;
BA_ "GenSigTimeoutTime_BSM2" SG_ 1456 FD14_RF_Chime_RqSts 0;
BA_ "GenSigTimeoutTime_CADM" SG_ 1456 FD14_RF_Chime_RqSts 0;
BA_ "GenSigTimeoutTime_CVADAS" SG_ 1456 FD14_RF_Chime_RqSts 0;
BA_ "GenSigTimeoutTime_ECM" SG_ 1456 FD14_RF_Chime_RqSts 0;
BA_ "GenSigTimeoutTime_EPS" SG_ 1456 FD14_RF_Chime_RqSts 0;
BA_ "GenSigSendType" SG_ 1456 FD14_RR_Chime_RqSts 3;
BA_ "GenSigTimeoutTime_BSM" SG_ 1456 FD14_RR_Chime_RqSts 0;
BA_ "GenSigTimeoutTime_BSM2" SG_ 1456 FD14_RR_Chime_RqSts 0;
BA_ "GenSigTimeoutTime_CADM" SG_ 1456 FD14_RR_Chime_RqSts 0;
BA_ "GenSigTimeoutTime_CVADAS" SG_ 1456 FD14_RR_Chime_RqSts 0;
BA_ "GenSigTimeoutTime_ECM" SG_ 1456 FD14_RR_Chime_RqSts 0;
BA_ "GenSigTimeoutTime_EPS" SG_ 1456 FD14_RR_Chime_RqSts 0;
BA_ "GenSigSendType" SG_ 1456 FD14_Set_Speed_KPH 3;
BA_ "GenSigTimeoutTime_BSM" SG_ 1456 FD14_Set_Speed_KPH 0;
BA_ "GenSigTimeoutTime_BSM2" SG_ 1456 FD14_Set_Speed_KPH 0;
BA_ "GenSigTimeoutTime_CADM" SG_ 1456 FD14_Set_Speed_KPH 0;
BA_ "GenSigTimeoutTime_CVADAS" SG_ 1456 FD14_Set_Speed_KPH 0;
BA_ "GenSigTimeoutTime_EPS" SG_ 1456 FD14_Set_Speed_KPH 0;
BA_ "GenSigSendType" SG_ 1456 FD14_Set_Speed_MPH 3;
BA_ "GenSigTimeoutTime_BSM" SG_ 1456 FD14_Set_Speed_MPH 0;
BA_ "GenSigTimeoutTime_BSM2" SG_ 1456 FD14_Set_Speed_MPH 0;
BA_ "GenSigTimeoutTime_CADM" SG_ 1456 FD14_Set_Speed_MPH 0;
BA_ "GenSigTimeoutTime_CVADAS" SG_ 1456 FD14_Set_Speed_MPH 0;
BA_ "GenSigTimeoutTime_EPS" SG_ 1456 FD14_Set_Speed_MPH 0;
BA_ "GenSigTimeoutTime_ORC" SG_ 1456 FD14_Set_Speed_MPH 0;
BA_ "GenSigSendType" SG_ 1456 FD14_SVI_Request 3;
BA_ "GenSigTimeoutTime_BSM" SG_ 1456 FD14_SVI_Request 0;
BA_ "GenSigTimeoutTime_BSM2" SG_ 1456 FD14_SVI_Request 0;
BA_ "GenSigTimeoutTime_CADM" SG_ 1456 FD14_SVI_Request 0;
BA_ "GenSigTimeoutTime_CVADAS" SG_ 1456 FD14_SVI_Request 0;
BA_ "GenSigTimeoutTime_ECM" SG_ 1456 FD14_SVI_Request 0;
BA_ "GenSigTimeoutTime_EPS" SG_ 1456 FD14_SVI_Request 0;
BA_ "GenSigTimeoutTime_ORC" SG_ 1456 FD14_SVI_Request 0;
BA_ "GenSigTimeoutTime_BSM2" SG_ 280 FD14_ACC_Drive_Cmd 0;
BA_ "GenSigTimeoutTime_CADM" SG_ 280 FD14_ACC_Drive_Cmd 0;
BA_ "GenSigTimeoutTime_CVADAS" SG_ 280 FD14_ACC_Drive_Cmd 0;
BA_ "GenSigTimeoutTime_ECM" SG_ 280 FD14_ACC_Drive_Cmd 0;
BA_ "GenSigTimeoutTime_EPS" SG_ 280 FD14_ACC_Drive_Cmd 0;
BA_ "GenSigTimeoutTime_ORC" SG_ 280 FD14_ACC_Drive_Cmd 0;
BA_ "GenSigTimeoutTime_BSM" SG_ 280 FD14_ACC_StopStart 0;
BA_ "GenSigTimeoutTime_BSM2" SG_ 280 FD14_ACC_StopStart 0;
BA_ "GenSigTimeoutTime_CADM" SG_ 280 FD14_ACC_StopStart 0;
BA_ "GenSigTimeoutTime_CVADAS" SG_ 280 FD14_ACC_StopStart 0;
BA_ "GenSigTimeoutTime_EPS" SG_ 280 FD14_ACC_StopStart 0;
BA_ "GenSigTimeoutTime_ORC" SG_ 280 FD14_ACC_StopStart 0;
BA_ "GenSigTimeoutTime_CADM" SG_ 280 FD14_ACC_Systemsts 0;
BA_ "GenSigTimeoutTime_ECM" SG_ 280 FD14_ACC_Systemsts 0;
BA_ "GenSigTimeoutTime_EPS" SG_ 280 FD14_ACC_Systemsts 0;
BA_ "GenSigTimeoutTime_BSM" SG_ 280 FD14_AEB_Sensitivity_Setting 0;
BA_ "GenSigTimeoutTime_BSM2" SG_ 280 FD14_AEB_Sensitivity_Setting 0;
BA_ "GenSigTimeoutTime_CADM" SG_ 280 FD14_AEB_Sensitivity_Setting 0;
BA_ "GenSigTimeoutTime_CVADAS" SG_ 280 FD14_AEB_Sensitivity_Setting 0;
BA_ "GenSigTimeoutTime_ECM" SG_ 280 FD14_AEB_Sensitivity_Setting 0;
BA_ "GenSigTimeoutTime_EPS" SG_ 280 FD14_AEB_Sensitivity_Setting 0;
BA_ "GenSigTimeoutTime_ORC" SG_ 280 FD14_AEB_Sensitivity_Setting 0;
BA_ "GenSigTimeoutTime_BSM" SG_ 280 FD14_AEB_Systemsts 0;
BA_ "GenSigTimeoutTime_BSM2" SG_ 280 FD14_AEB_Systemsts 0;
BA_ "GenSigTimeoutTime_CADM" SG_ 280 FD14_AEB_Systemsts 0;
BA_ "GenSigTimeoutTime_CVADAS" SG_ 280 FD14_AEB_Systemsts 0;
BA_ "GenSigTimeoutTime_ECM" SG_ 280 FD14_AEB_Systemsts 0;
BA_ "GenSigTimeoutTime_EPS" SG_ 280 FD14_AEB_Systemsts 0;
BA_ "GenSigTimeoutTime_CADM" SG_ 280 FD14_AEB_Type 0;
BA_ "GenSigTimeoutTime_CVADAS" SG_ 280 FD14_AEB_Type 0;
BA_ "GenSigTimeoutTime_ECM" SG_ 280 FD14_AEB_Type 0;
BA_ "GenSigTimeoutTime_EPS" SG_ 280 FD14_AEB_Type 0;
BA_ "GenSigTimeoutTime_CADM" SG_ 280 FD14_Brake_Jerk_Req 0;
BA_ "GenSigTimeoutTime_CVADAS" SG_ 280 FD14_Brake_Jerk_Req 0;
BA_ "GenSigTimeoutTime_ECM" SG_ 280 FD14_Brake_Jerk_Req 0;
BA_ "GenSigTimeoutTime_EPS" SG_ 280 FD14_Brake_Jerk_Req 0;
BA_ "GenSigTimeoutTime_ORC" SG_ 280 FD14_Brake_Jerk_Req 0;
BA_ "GenSigTimeoutTime_BSM" SG_ 280 FD14_CADM_OpStat 0;
BA_ "GenSigTimeoutTime_BSM2" SG_ 280 FD14_CADM_OpStat 0;
BA_ "GenSigTimeoutTime_CADM" SG_ 280 FD14_CADM_OpStat 0;
BA_ "GenSigTimeoutTime_CVADAS" SG_ 280 FD14_CADM_OpStat 0;
BA_ "GenSigTimeoutTime_ECM" SG_ 280 FD14_CADM_OpStat 0;
BA_ "GenSigTimeoutTime_EPS" SG_ 280 FD14_CADM_OpStat 0;
BA_ "GenSigTimeoutTime_ORC" SG_ 280 FD14_CADM_OpStat 0;
BA_ "GenSigTimeoutTime_BSM" SG_ 280 FD14_CADM2_EPSSEC_FAIL 0;
BA_ "GenSigTimeoutTime_BSM2" SG_ 280 FD14_CADM2_EPSSEC_FAIL 0;
BA_ "GenSigTimeoutTime_CADM" SG_ 280 FD14_CADM2_EPSSEC_FAIL 0;
BA_ "GenSigTimeoutTime_CVADAS" SG_ 280 FD14_CADM2_EPSSEC_FAIL 0;
BA_ "GenSigTimeoutTime_ECM" SG_ 280 FD14_CADM2_EPSSEC_FAIL 0;
BA_ "GenSigTimeoutTime_ORC" SG_ 280 FD14_CADM2_EPSSEC_FAIL 0;
BA_ "GenSigTimeoutTime_BSM" SG_ 280 FD14_CIPV_Fused 0;
BA_ "GenSigTimeoutTime_BSM2" SG_ 280 FD14_CIPV_Fused 0;
BA_ "GenSigTimeoutTime_CADM" SG_ 280 FD14_CIPV_Fused 0;
BA_ "GenSigTimeoutTime_CVADAS" SG_ 280 FD14_CIPV_Fused 0;
BA_ "GenSigTimeoutTime_ECM" SG_ 280 FD14_CIPV_Fused 0;
BA_ "GenSigTimeoutTime_EPS" SG_ 280 FD14_CIPV_Fused 0;
BA_ "GenSigTimeoutTime_CADM" SG_ 280 FD14_CRC_ADAS_FD_INFO 0;
BA_ "GenSigTimeoutTime_ORC" SG_ 280 FD14_CRC_ADAS_FD_INFO 0;
BA_ "GenSigTimeoutTime_BSM" SG_ 280 FD14_DDD_Setting_Avail 0;
BA_ "GenSigTimeoutTime_BSM2" SG_ 280 FD14_DDD_Setting_Avail 0;
BA_ "GenSigTimeoutTime_CADM" SG_ 280 FD14_DDD_Setting_Avail 0;
BA_ "GenSigTimeoutTime_CVADAS" SG_ 280 FD14_DDD_Setting_Avail 0;
BA_ "GenSigTimeoutTime_ECM" SG_ 280 FD14_DDD_Setting_Avail 0;
BA_ "GenSigTimeoutTime_EPS" SG_ 280 FD14_DDD_Setting_Avail 0;
BA_ "GenSigTimeoutTime_ORC" SG_ 280 FD14_DDD_Setting_Avail 0;
BA_ "GenSigTimeoutTime_BSM" SG_ 280 FD14_DDD_SystemSts 0;
BA_ "GenSigTimeoutTime_BSM2" SG_ 280 FD14_DDD_SystemSts 0;
BA_ "GenSigTimeoutTime_CADM" SG_ 280 FD14_DDD_SystemSts 0;
BA_ "GenSigTimeoutTime_CVADAS" SG_ 280 FD14_DDD_SystemSts 0;
BA_ "GenSigTimeoutTime_ECM" SG_ 280 FD14_DDD_SystemSts 0;
BA_ "GenSigTimeoutTime_EPS" SG_ 280 FD14_DDD_SystemSts 0;
BA_ "GenSigTimeoutTime_BSM2" SG_ 280 FD14_ESA_FailSts 0;
BA_ "GenSigTimeoutTime_CADM" SG_ 280 FD14_ESA_FailSts 0;
BA_ "GenSigTimeoutTime_CVADAS" SG_ 280 FD14_ESA_FailSts 0;
BA_ "GenSigTimeoutTime_ECM" SG_ 280 FD14_ESA_FailSts 0;
BA_ "GenSigTimeoutTime_ORC" SG_ 280 FD14_ESA_FailSts 0;
BA_ "GenSigSendType" SG_ 280 FD14_ESA_LaneClear_Status 3;
BA_ "GenSigTimeoutTime_BSM2" SG_ 280 FD14_ESA_LaneClear_Status 0;
BA_ "GenSigTimeoutTime_CADM" SG_ 280 FD14_ESA_LaneClear_Status 0;
BA_ "GenSigTimeoutTime_CVADAS" SG_ 280 FD14_ESA_LaneClear_Status 0;
BA_ "GenSigTimeoutTime_ECM" SG_ 280 FD14_ESA_LaneClear_Status 0;
BA_ "GenSigTimeoutTime_EPS" SG_ 280 FD14_ESA_LaneClear_Status 0;
BA_ "GenSigTimeoutTime_ORC" SG_ 280 FD14_ESA_LaneClear_Status 0;
BA_ "GenSigTimeoutTime_BSM" SG_ 280 FD14_ESA_LAT_CTRL_RequestSts 0;
BA_ "GenSigTimeoutTime_BSM2" SG_ 280 FD14_ESA_LAT_CTRL_RequestSts 0;
BA_ "GenSigTimeoutTime_CADM" SG_ 280 FD14_ESA_LAT_CTRL_RequestSts 0;
BA_ "GenSigTimeoutTime_CVADAS" SG_ 280 FD14_ESA_LAT_CTRL_RequestSts 0;
BA_ "GenSigTimeoutTime_ECM" SG_ 280 FD14_ESA_LAT_CTRL_RequestSts 0;
BA_ "GenSigTimeoutTime_ORC" SG_ 280 FD14_ESA_LAT_CTRL_RequestSts 0;
BA_ "GenSigStartValue" SG_ 280 FD14_ESA_TorqueOverlaySteeringRe 1024;
BA_ "GenSigTimeoutTime_BSM" SG_ 280 FD14_ESA_TorqueOverlaySteeringRe 0;
BA_ "GenSigTimeoutTime_BSM2" SG_ 280 FD14_ESA_TorqueOverlaySteeringRe 0;
BA_ "GenSigTimeoutTime_CADM" SG_ 280 FD14_ESA_TorqueOverlaySteeringRe 0;
BA_ "GenSigTimeoutTime_CVADAS" SG_ 280 FD14_ESA_TorqueOverlaySteeringRe 0;
BA_ "GenSigTimeoutTime_ECM" SG_ 280 FD14_ESA_TorqueOverlaySteeringRe 0;
BA_ "GenSigTimeoutTime_ORC" SG_ 280 FD14_ESA_TorqueOverlaySteeringRe 0;
BA_ "SystemSignalLongSymbol" SG_ 280 FD14_ESA_TorqueOverlaySteeringRe "FD14_ESA_TorqueOverlaySteeringReq";
BA_ "GenSigTimeoutTime_BSM2" SG_ 280 FD14_ESASystemSts 0;
BA_ "GenSigTimeoutTime_CADM" SG_ 280 FD14_ESASystemSts 0;
BA_ "GenSigTimeoutTime_CVADAS" SG_ 280 FD14_ESASystemSts 0;
BA_ "GenSigTimeoutTime_ECM" SG_ 280 FD14_ESASystemSts 0;
BA_ "GenSigTimeoutTime_ORC" SG_ 280 FD14_ESASystemSts 0;
BA_ "GenSigTimeoutTime_BSM" SG_ 280 FD14_ESCALATION_TYPE 0;
BA_ "GenSigTimeoutTime_BSM2" SG_ 280 FD14_ESCALATION_TYPE 0;
BA_ "GenSigTimeoutTime_CADM" SG_ 280 FD14_ESCALATION_TYPE 0;
BA_ "GenSigTimeoutTime_CVADAS" SG_ 280 FD14_ESCALATION_TYPE 0;
BA_ "GenSigTimeoutTime_ECM" SG_ 280 FD14_ESCALATION_TYPE 0;
BA_ "GenSigTimeoutTime_EPS" SG_ 280 FD14_ESCALATION_TYPE 0;
BA_ "GenSigTimeoutTime_BSM2" SG_ 280 FD14_GrMax_Rq_ACC 0;
BA_ "GenSigTimeoutTime_CADM" SG_ 280 FD14_GrMax_Rq_ACC 0;
BA_ "GenSigTimeoutTime_CVADAS" SG_ 280 FD14_GrMax_Rq_ACC 0;
BA_ "GenSigTimeoutTime_ECM" SG_ 280 FD14_GrMax_Rq_ACC 0;
BA_ "GenSigTimeoutTime_EPS" SG_ 280 FD14_GrMax_Rq_ACC 0;
BA_ "GenSigTimeoutTime_ORC" SG_ 280 FD14_GrMax_Rq_ACC 0;
BA_ "GenSigTimeoutTime_BSM" SG_ 280 FD14_HAS_LAT_CTRL_RequestSts 0;
BA_ "GenSigTimeoutTime_BSM2" SG_ 280 FD14_HAS_LAT_CTRL_RequestSts 0;
BA_ "GenSigTimeoutTime_CADM" SG_ 280 FD14_HAS_LAT_CTRL_RequestSts 0;
BA_ "GenSigTimeoutTime_CVADAS" SG_ 280 FD14_HAS_LAT_CTRL_RequestSts 0;
BA_ "GenSigTimeoutTime_ECM" SG_ 280 FD14_HAS_LAT_CTRL_RequestSts 0;
BA_ "GenSigTimeoutTime_ORC" SG_ 280 FD14_HAS_LAT_CTRL_RequestSts 0;
BA_ "GenSigTimeoutTime_BSM" SG_ 280 FD14_HAS_OpStat_Prim 0;
BA_ "GenSigTimeoutTime_BSM2" SG_ 280 FD14_HAS_OpStat_Prim 0;
BA_ "GenSigTimeoutTime_CADM" SG_ 280 FD14_HAS_OpStat_Prim 0;
BA_ "GenSigTimeoutTime_CVADAS" SG_ 280 FD14_HAS_OpStat_Prim 0;
BA_ "GenSigTimeoutTime_ECM" SG_ 280 FD14_HAS_OpStat_Prim 0;
BA_ "GenSigTimeoutTime_EPS" SG_ 280 FD14_HAS_OpStat_Prim 0;
BA_ "GenSigTimeoutTime_CADM" SG_ 280 FD14_HAS_Status 0;
BA_ "GenSigTimeoutTime_ECM" SG_ 280 FD14_HAS_Status 0;
BA_ "GenSigTimeoutTime_EPS" SG_ 280 FD14_HAS_Status 0;
BA_ "GenSigTimeoutTime_ORC" SG_ 280 FD14_HAS_Status 0;
BA_ "GenSigTimeoutTime_CADM" SG_ 280 FD14_HIS_Req 0;
BA_ "GenSigTimeoutTime_CVADAS" SG_ 280 FD14_HIS_Req 0;
BA_ "GenSigTimeoutTime_ECM" SG_ 280 FD14_HIS_Req 0;
BA_ "GenSigTimeoutTime_EPS" SG_ 280 FD14_HIS_Req 0;
BA_ "GenSigStartValue" SG_ 280 FD14_Intervention 4095;
BA_ "GenSigTimeoutTime_CADM" SG_ 280 FD14_Intervention 0;
BA_ "GenSigTimeoutTime_CVADAS" SG_ 280 FD14_Intervention 0;
BA_ "GenSigTimeoutTime_ECM" SG_ 280 FD14_Intervention 0;
BA_ "GenSigTimeoutTime_EPS" SG_ 280 FD14_Intervention 0;
BA_ "GenSigTimeoutTime_BSM" SG_ 280 FD14_LANE_CHANGE_SIDE 0;
BA_ "GenSigTimeoutTime_BSM2" SG_ 280 FD14_LANE_CHANGE_SIDE 0;
BA_ "GenSigTimeoutTime_CADM" SG_ 280 FD14_LANE_CHANGE_SIDE 0;
BA_ "GenSigTimeoutTime_CVADAS" SG_ 280 FD14_LANE_CHANGE_SIDE 0;
BA_ "GenSigTimeoutTime_ECM" SG_ 280 FD14_LANE_CHANGE_SIDE 0;
BA_ "GenSigTimeoutTime_EPS" SG_ 280 FD14_LANE_CHANGE_SIDE 0;
BA_ "GenSigTimeoutTime_BSM" SG_ 280 FD14_LANE_CHANGE_STATUS 0;
BA_ "GenSigTimeoutTime_BSM2" SG_ 280 FD14_LANE_CHANGE_STATUS 0;
BA_ "GenSigTimeoutTime_CADM" SG_ 280 FD14_LANE_CHANGE_STATUS 0;
BA_ "GenSigTimeoutTime_CVADAS" SG_ 280 FD14_LANE_CHANGE_STATUS 0;
BA_ "GenSigTimeoutTime_ECM" SG_ 280 FD14_LANE_CHANGE_STATUS 0;
BA_ "GenSigTimeoutTime_EPS" SG_ 280 FD14_LANE_CHANGE_STATUS 0;
BA_ "GenSigTimeoutTime_BSM2" SG_ 280 FD14_LC_Jerk 0;
BA_ "GenSigTimeoutTime_CADM" SG_ 280 FD14_LC_Jerk 0;
BA_ "GenSigTimeoutTime_CVADAS" SG_ 280 FD14_LC_Jerk 0;
BA_ "GenSigTimeoutTime_ECM" SG_ 280 FD14_LC_Jerk 0;
BA_ "GenSigTimeoutTime_EPS" SG_ 280 FD14_LC_Jerk 0;
BA_ "GenSigTimeoutTime_ORC" SG_ 280 FD14_LC_Jerk 0;
BA_ "GenSigTimeoutTime_BSM" SG_ 280 FD14_LKA_LAT_CTRL_RequestSts 0;
BA_ "GenSigTimeoutTime_BSM2" SG_ 280 FD14_LKA_LAT_CTRL_RequestSts 0;
BA_ "GenSigTimeoutTime_CADM" SG_ 280 FD14_LKA_LAT_CTRL_RequestSts 0;
BA_ "GenSigTimeoutTime_CVADAS" SG_ 280 FD14_LKA_LAT_CTRL_RequestSts 0;
BA_ "GenSigTimeoutTime_ECM" SG_ 280 FD14_LKA_LAT_CTRL_RequestSts 0;
BA_ "GenSigTimeoutTime_ORC" SG_ 280 FD14_LKA_LAT_CTRL_RequestSts 0;
BA_ "GenSigTimeoutTime_CADM" SG_ 280 FD14_MessageCounter_ADAS_FD_INFO 0;
BA_ "GenSigTimeoutTime_ORC" SG_ 280 FD14_MessageCounter_ADAS_FD_INFO 0;
BA_ "GenSigTimeoutTime_BSM2" SG_ 280 FD14_MRM_STATUS 0;
BA_ "GenSigTimeoutTime_CADM" SG_ 280 FD14_MRM_STATUS 0;
BA_ "GenSigTimeoutTime_CVADAS" SG_ 280 FD14_MRM_STATUS 0;
BA_ "GenSigTimeoutTime_ECM" SG_ 280 FD14_MRM_STATUS 0;
BA_ "GenSigTimeoutTime_EPS" SG_ 280 FD14_MRM_STATUS 0;
BA_ "GenSigStartValue" SG_ 280 FD14_Object_Dist 255;
BA_ "GenSigTimeoutTime_BSM2" SG_ 280 FD14_Object_Dist 0;
BA_ "GenSigTimeoutTime_CADM" SG_ 280 FD14_Object_Dist 0;
BA_ "GenSigTimeoutTime_CVADAS" SG_ 280 FD14_Object_Dist 0;
BA_ "GenSigTimeoutTime_ECM" SG_ 280 FD14_Object_Dist 0;
BA_ "GenSigTimeoutTime_EPS" SG_ 280 FD14_Object_Dist 0;
BA_ "GenSigTimeoutTime_BSM" SG_ 280 FD14_PEB_SystemSts 0;
BA_ "GenSigTimeoutTime_BSM2" SG_ 280 FD14_PEB_SystemSts 0;
BA_ "GenSigTimeoutTime_CADM" SG_ 280 FD14_PEB_SystemSts 0;
BA_ "GenSigTimeoutTime_CVADAS" SG_ 280 FD14_PEB_SystemSts 0;
BA_ "GenSigTimeoutTime_ECM" SG_ 280 FD14_PEB_SystemSts 0;
BA_ "GenSigTimeoutTime_EPS" SG_ 280 FD14_PEB_SystemSts 0;
BA_ "GenSigTimeoutTime_CADM" SG_ 280 FD14_Prefill_Req 0;
BA_ "GenSigTimeoutTime_CVADAS" SG_ 280 FD14_Prefill_Req 0;
BA_ "GenSigTimeoutTime_ECM" SG_ 280 FD14_Prefill_Req 0;
BA_ "GenSigTimeoutTime_EPS" SG_ 280 FD14_Prefill_Req 0;
BA_ "GenSigTimeoutTime_ORC" SG_ 280 FD14_Prefill_Req 0;
BA_ "GenSigTimeoutTime_BSM" SG_ 280 FD14_SteeringVibration_Rq 0;
BA_ "GenSigTimeoutTime_BSM2" SG_ 280 FD14_SteeringVibration_Rq 0;
BA_ "GenSigTimeoutTime_CADM" SG_ 280 FD14_SteeringVibration_Rq 0;
BA_ "GenSigTimeoutTime_CVADAS" SG_ 280 FD14_SteeringVibration_Rq 0;
BA_ "GenSigTimeoutTime_ECM" SG_ 280 FD14_SteeringVibration_Rq 0;
BA_ "GenSigTimeoutTime_ORC" SG_ 280 FD14_SteeringVibration_Rq 0;
BA_ "GenSigTimeoutTime_BSM" SG_ 280 FD14_SteeringVibration_Type 0;
BA_ "GenSigTimeoutTime_BSM2" SG_ 280 FD14_SteeringVibration_Type 0;
BA_ "GenSigTimeoutTime_CADM" SG_ 280 FD14_SteeringVibration_Type 0;
BA_ "GenSigTimeoutTime_CVADAS" SG_ 280 FD14_SteeringVibration_Type 0;
BA_ "GenSigTimeoutTime_ECM" SG_ 280 FD14_SteeringVibration_Type 0;
BA_ "GenSigTimeoutTime_ORC" SG_ 280 FD14_SteeringVibration_Type 0;
BA_ "GenSigStartValue" SG_ 280 FD14_TorqueOverlaySteeringReq 1024;
BA_ "GenSigTimeoutTime_BSM" SG_ 280 FD14_TorqueOverlaySteeringReq 0;
BA_ "GenSigTimeoutTime_BSM2" SG_ 280 FD14_TorqueOverlaySteeringReq 0;
BA_ "GenSigTimeoutTime_CADM" SG_ 280 FD14_TorqueOverlaySteeringReq 0;
BA_ "GenSigTimeoutTime_CVADAS" SG_ 280 FD14_TorqueOverlaySteeringReq 0;
BA_ "GenSigTimeoutTime_ECM" SG_ 280 FD14_TorqueOverlaySteeringReq 0;
BA_ "GenSigStartValue" SG_ 299 FD14_ACC_Axle_Torque 32768;
BA_ "GenSigTimeoutTime_BSM2" SG_ 299 FD14_ACC_Axle_Torque 0;
BA_ "GenSigTimeoutTime_CADM" SG_ 299 FD14_ACC_Axle_Torque 0;
BA_ "GenSigTimeoutTime_CVADAS" SG_ 299 FD14_ACC_Axle_Torque 0;
BA_ "GenSigTimeoutTime_ECM" SG_ 299 FD14_ACC_Axle_Torque 0;
BA_ "GenSigTimeoutTime_EPS" SG_ 299 FD14_ACC_Axle_Torque 0;
BA_ "GenSigTimeoutTime_ORC" SG_ 299 FD14_ACC_Axle_Torque 0;
BA_ "GenSigTimeoutTime_BSM2" SG_ 299 FD14_ACC_Axle_Torque_Enabled 0;
BA_ "GenSigTimeoutTime_CADM" SG_ 299 FD14_ACC_Axle_Torque_Enabled 0;
BA_ "GenSigTimeoutTime_CVADAS" SG_ 299 FD14_ACC_Axle_Torque_Enabled 0;
BA_ "GenSigTimeoutTime_ECM" SG_ 299 FD14_ACC_Axle_Torque_Enabled 0;
BA_ "GenSigTimeoutTime_EPS" SG_ 299 FD14_ACC_Axle_Torque_Enabled 0;
BA_ "GenSigTimeoutTime_ORC" SG_ 299 FD14_ACC_Axle_Torque_Enabled 0;
BA_ "GenSigTimeoutTime_BSM2" SG_ 299 FD14_CRC_ADAS_FD_INFO3 0;
BA_ "GenSigTimeoutTime_CADM" SG_ 299 FD14_CRC_ADAS_FD_INFO3 0;
BA_ "GenSigTimeoutTime_CVADAS" SG_ 299 FD14_CRC_ADAS_FD_INFO3 0;
BA_ "GenSigTimeoutTime_ECM" SG_ 299 FD14_CRC_ADAS_FD_INFO3 0;
BA_ "GenSigTimeoutTime_EPS" SG_ 299 FD14_CRC_ADAS_FD_INFO3 0;
BA_ "GenSigTimeoutTime_ORC" SG_ 299 FD14_CRC_ADAS_FD_INFO3 0;
BA_ "GenSigTimeoutTime_BSM2" SG_ 299 FD14_MessageCounter_ADAS_FD_0000 0;
BA_ "GenSigTimeoutTime_CADM" SG_ 299 FD14_MessageCounter_ADAS_FD_0000 0;
BA_ "GenSigTimeoutTime_CVADAS" SG_ 299 FD14_MessageCounter_ADAS_FD_0000 0;
BA_ "GenSigTimeoutTime_ECM" SG_ 299 FD14_MessageCounter_ADAS_FD_0000 0;
BA_ "GenSigTimeoutTime_EPS" SG_ 299 FD14_MessageCounter_ADAS_FD_0000 0;
BA_ "GenSigTimeoutTime_ORC" SG_ 299 FD14_MessageCounter_ADAS_FD_0000 0;
BA_ "SystemSignalLongSymbol" SG_ 299 FD14_MessageCounter_ADAS_FD_0000 "FD14_MessageCounter_ADAS_FD_INFO3";
BA_ "GenSigTimeoutTime_BSM" SG_ 730 FD14_Camera_Status 0;
BA_ "GenSigTimeoutTime_BSM2" SG_ 730 FD14_Camera_Status 0;
BA_ "GenSigTimeoutTime_CVADAS" SG_ 730 FD14_Camera_Status 0;
BA_ "GenSigTimeoutTime_ECM" SG_ 730 FD14_Camera_Status 0;
BA_ "GenSigTimeoutTime_EPS" SG_ 730 FD14_Camera_Status 0;
BA_ "GenSigTimeoutTime_ORC" SG_ 730 FD14_Camera_Status 0;
BA_ "GenSigTimeoutTime_BSM" SG_ 730 FD14_Cntr_ADAS_FD_LANES_1 0;
BA_ "GenSigTimeoutTime_BSM2" SG_ 730 FD14_Cntr_ADAS_FD_LANES_1 0;
BA_ "GenSigTimeoutTime_CVADAS" SG_ 730 FD14_Cntr_ADAS_FD_LANES_1 0;
BA_ "GenSigTimeoutTime_ECM" SG_ 730 FD14_Cntr_ADAS_FD_LANES_1 0;
BA_ "GenSigTimeoutTime_EPS" SG_ 730 FD14_Cntr_ADAS_FD_LANES_1 0;
BA_ "GenSigTimeoutTime_ORC" SG_ 730 FD14_Cntr_ADAS_FD_LANES_1 0;
BA_ "GenSigTimeoutTime_BSM" SG_ 730 FD14_CRC_ADAS_FD_LANES_1 0;
BA_ "GenSigTimeoutTime_BSM2" SG_ 730 FD14_CRC_ADAS_FD_LANES_1 0;
BA_ "GenSigTimeoutTime_CVADAS" SG_ 730 FD14_CRC_ADAS_FD_LANES_1 0;
BA_ "GenSigTimeoutTime_ECM" SG_ 730 FD14_CRC_ADAS_FD_LANES_1 0;
BA_ "GenSigTimeoutTime_EPS" SG_ 730 FD14_CRC_ADAS_FD_LANES_1 0;
BA_ "GenSigTimeoutTime_ORC" SG_ 730 FD14_CRC_ADAS_FD_LANES_1 0;
BA_ "GenSigTimeoutTime_BSM" SG_ 730 FD14_FOD_Confidence 0;
BA_ "GenSigTimeoutTime_BSM2" SG_ 730 FD14_FOD_Confidence 0;
BA_ "GenSigTimeoutTime_CVADAS" SG_ 730 FD14_FOD_Confidence 0;
BA_ "GenSigTimeoutTime_ECM" SG_ 730 FD14_FOD_Confidence 0;
BA_ "GenSigTimeoutTime_EPS" SG_ 730 FD14_FOD_Confidence 0;
BA_ "GenSigTimeoutTime_ORC" SG_ 730 FD14_FOD_Confidence 0;
BA_ "GenSigTimeoutTime_BSM" SG_ 730 FD14_Frame_Index_Lanes_1 0;
BA_ "GenSigTimeoutTime_BSM2" SG_ 730 FD14_Frame_Index_Lanes_1 0;
BA_ "GenSigTimeoutTime_CVADAS" SG_ 730 FD14_Frame_Index_Lanes_1 0;
BA_ "GenSigTimeoutTime_ECM" SG_ 730 FD14_Frame_Index_Lanes_1 0;
BA_ "GenSigTimeoutTime_EPS" SG_ 730 FD14_Frame_Index_Lanes_1 0;
BA_ "GenSigTimeoutTime_ORC" SG_ 730 FD14_Frame_Index_Lanes_1 0;
BA_ "GenSigTimeoutTime_BSM" SG_ 730 FD14_Health_Front_Object_Detecti 0;
BA_ "GenSigTimeoutTime_BSM2" SG_ 730 FD14_Health_Front_Object_Detecti 0;
BA_ "GenSigTimeoutTime_CVADAS" SG_ 730 FD14_Health_Front_Object_Detecti 0;
BA_ "GenSigTimeoutTime_ECM" SG_ 730 FD14_Health_Front_Object_Detecti 0;
BA_ "GenSigTimeoutTime_EPS" SG_ 730 FD14_Health_Front_Object_Detecti 0;
BA_ "GenSigTimeoutTime_ORC" SG_ 730 FD14_Health_Front_Object_Detecti 0;
BA_ "SystemSignalLongSymbol" SG_ 730 FD14_Health_Front_Object_Detecti "FD14_Health_Front_Object_Detection";
BA_ "GenSigTimeoutTime_BSM" SG_ 730 FD14_Health_Lane_Detection 0;
BA_ "GenSigTimeoutTime_BSM2" SG_ 730 FD14_Health_Lane_Detection 0;
BA_ "GenSigTimeoutTime_CVADAS" SG_ 730 FD14_Health_Lane_Detection 0;
BA_ "GenSigTimeoutTime_ECM" SG_ 730 FD14_Health_Lane_Detection 0;
BA_ "GenSigTimeoutTime_EPS" SG_ 730 FD14_Health_Lane_Detection 0;
BA_ "GenSigTimeoutTime_ORC" SG_ 730 FD14_Health_Lane_Detection 0;
BA_ "GenSigTimeoutTime_BSM" SG_ 730 FD14_Line_1_Confidence 0;
BA_ "GenSigTimeoutTime_BSM2" SG_ 730 FD14_Line_1_Confidence 0;
BA_ "GenSigTimeoutTime_CVADAS" SG_ 730 FD14_Line_1_Confidence 0;
BA_ "GenSigTimeoutTime_ECM" SG_ 730 FD14_Line_1_Confidence 0;
BA_ "GenSigTimeoutTime_EPS" SG_ 730 FD14_Line_1_Confidence 0;
BA_ "GenSigTimeoutTime_ORC" SG_ 730 FD14_Line_1_Confidence 0;
BA_ "GenSigTimeoutTime_BSM" SG_ 730 FD14_Line_1_Curvature 0;
BA_ "GenSigTimeoutTime_BSM2" SG_ 730 FD14_Line_1_Curvature 0;
BA_ "GenSigTimeoutTime_CVADAS" SG_ 730 FD14_Line_1_Curvature 0;
BA_ "GenSigTimeoutTime_ECM" SG_ 730 FD14_Line_1_Curvature 0;
BA_ "GenSigTimeoutTime_EPS" SG_ 730 FD14_Line_1_Curvature 0;
BA_ "GenSigTimeoutTime_ORC" SG_ 730 FD14_Line_1_Curvature 0;
BA_ "GenSigTimeoutTime_BSM" SG_ 730 FD14_Line_1_Curvature_Rate 0;
BA_ "GenSigTimeoutTime_BSM2" SG_ 730 FD14_Line_1_Curvature_Rate 0;
BA_ "GenSigTimeoutTime_CVADAS" SG_ 730 FD14_Line_1_Curvature_Rate 0;
BA_ "GenSigTimeoutTime_ECM" SG_ 730 FD14_Line_1_Curvature_Rate 0;
BA_ "GenSigTimeoutTime_EPS" SG_ 730 FD14_Line_1_Curvature_Rate 0;
BA_ "GenSigTimeoutTime_ORC" SG_ 730 FD14_Line_1_Curvature_Rate 0;
BA_ "GenSigTimeoutTime_BSM" SG_ 730 FD14_Line_1_End_Range 0;
BA_ "GenSigTimeoutTime_BSM2" SG_ 730 FD14_Line_1_End_Range 0;
BA_ "GenSigTimeoutTime_CVADAS" SG_ 730 FD14_Line_1_End_Range 0;
BA_ "GenSigTimeoutTime_ECM" SG_ 730 FD14_Line_1_End_Range 0;
BA_ "GenSigTimeoutTime_EPS" SG_ 730 FD14_Line_1_End_Range 0;
BA_ "GenSigTimeoutTime_ORC" SG_ 730 FD14_Line_1_End_Range 0;
BA_ "GenSigTimeoutTime_BSM" SG_ 730 FD14_Line_1_Heading 0;
BA_ "GenSigTimeoutTime_BSM2" SG_ 730 FD14_Line_1_Heading 0;
BA_ "GenSigTimeoutTime_CVADAS" SG_ 730 FD14_Line_1_Heading 0;
BA_ "GenSigTimeoutTime_ECM" SG_ 730 FD14_Line_1_Heading 0;
BA_ "GenSigTimeoutTime_EPS" SG_ 730 FD14_Line_1_Heading 0;
BA_ "GenSigTimeoutTime_ORC" SG_ 730 FD14_Line_1_Heading 0;
BA_ "GenSigTimeoutTime_BSM" SG_ 730 FD14_Line_1_Offset 0;
BA_ "GenSigTimeoutTime_BSM2" SG_ 730 FD14_Line_1_Offset 0;
BA_ "GenSigTimeoutTime_CVADAS" SG_ 730 FD14_Line_1_Offset 0;
BA_ "GenSigTimeoutTime_ECM" SG_ 730 FD14_Line_1_Offset 0;
BA_ "GenSigTimeoutTime_EPS" SG_ 730 FD14_Line_1_Offset 0;
BA_ "GenSigTimeoutTime_ORC" SG_ 730 FD14_Line_1_Offset 0;
BA_ "GenSigTimeoutTime_BSM" SG_ 730 FD14_Line_1_Start_Range 0;
BA_ "GenSigTimeoutTime_BSM2" SG_ 730 FD14_Line_1_Start_Range 0;
BA_ "GenSigTimeoutTime_CVADAS" SG_ 730 FD14_Line_1_Start_Range 0;
BA_ "GenSigTimeoutTime_ECM" SG_ 730 FD14_Line_1_Start_Range 0;
BA_ "GenSigTimeoutTime_EPS" SG_ 730 FD14_Line_1_Start_Range 0;
BA_ "GenSigTimeoutTime_ORC" SG_ 730 FD14_Line_1_Start_Range 0;
BA_ "GenSigTimeoutTime_BSM" SG_ 730 FD14_Line_1_Type 0;
BA_ "GenSigTimeoutTime_BSM2" SG_ 730 FD14_Line_1_Type 0;
BA_ "GenSigTimeoutTime_CVADAS" SG_ 730 FD14_Line_1_Type 0;
BA_ "GenSigTimeoutTime_ECM" SG_ 730 FD14_Line_1_Type 0;
BA_ "GenSigTimeoutTime_EPS" SG_ 730 FD14_Line_1_Type 0;
BA_ "GenSigTimeoutTime_ORC" SG_ 730 FD14_Line_1_Type 0;
BA_ "GenSigTimeoutTime_BSM" SG_ 730 FD14_Line_2_Confidence 0;
BA_ "GenSigTimeoutTime_BSM2" SG_ 730 FD14_Line_2_Confidence 0;
BA_ "GenSigTimeoutTime_CVADAS" SG_ 730 FD14_Line_2_Confidence 0;
BA_ "GenSigTimeoutTime_ECM" SG_ 730 FD14_Line_2_Confidence 0;
BA_ "GenSigTimeoutTime_EPS" SG_ 730 FD14_Line_2_Confidence 0;
BA_ "GenSigTimeoutTime_ORC" SG_ 730 FD14_Line_2_Confidence 0;
BA_ "GenSigTimeoutTime_BSM" SG_ 730 FD14_Line_2_Curvature 0;
BA_ "GenSigTimeoutTime_BSM2" SG_ 730 FD14_Line_2_Curvature 0;
BA_ "GenSigTimeoutTime_CVADAS" SG_ 730 FD14_Line_2_Curvature 0;
BA_ "GenSigTimeoutTime_ECM" SG_ 730 FD14_Line_2_Curvature 0;
BA_ "GenSigTimeoutTime_EPS" SG_ 730 FD14_Line_2_Curvature 0;
BA_ "GenSigTimeoutTime_ORC" SG_ 730 FD14_Line_2_Curvature 0;
BA_ "GenSigTimeoutTime_BSM" SG_ 730 FD14_Line_2_Curvature_Rate 0;
BA_ "GenSigTimeoutTime_BSM2" SG_ 730 FD14_Line_2_Curvature_Rate 0;
BA_ "GenSigTimeoutTime_CVADAS" SG_ 730 FD14_Line_2_Curvature_Rate 0;
BA_ "GenSigTimeoutTime_ECM" SG_ 730 FD14_Line_2_Curvature_Rate 0;
BA_ "GenSigTimeoutTime_EPS" SG_ 730 FD14_Line_2_Curvature_Rate 0;
BA_ "GenSigTimeoutTime_ORC" SG_ 730 FD14_Line_2_Curvature_Rate 0;
BA_ "GenSigTimeoutTime_BSM" SG_ 730 FD14_Line_2_End_Range 0;
BA_ "GenSigTimeoutTime_BSM2" SG_ 730 FD14_Line_2_End_Range 0;
BA_ "GenSigTimeoutTime_CVADAS" SG_ 730 FD14_Line_2_End_Range 0;
BA_ "GenSigTimeoutTime_ECM" SG_ 730 FD14_Line_2_End_Range 0;
BA_ "GenSigTimeoutTime_EPS" SG_ 730 FD14_Line_2_End_Range 0;
BA_ "GenSigTimeoutTime_ORC" SG_ 730 FD14_Line_2_End_Range 0;
BA_ "GenSigTimeoutTime_BSM" SG_ 730 FD14_Line_2_Heading 0;
BA_ "GenSigTimeoutTime_BSM2" SG_ 730 FD14_Line_2_Heading 0;
BA_ "GenSigTimeoutTime_CVADAS" SG_ 730 FD14_Line_2_Heading 0;
BA_ "GenSigTimeoutTime_ECM" SG_ 730 FD14_Line_2_Heading 0;
BA_ "GenSigTimeoutTime_EPS" SG_ 730 FD14_Line_2_Heading 0;
BA_ "GenSigTimeoutTime_ORC" SG_ 730 FD14_Line_2_Heading 0;
BA_ "GenSigTimeoutTime_BSM" SG_ 730 FD14_Line_2_Offset 0;
BA_ "GenSigTimeoutTime_BSM2" SG_ 730 FD14_Line_2_Offset 0;
BA_ "GenSigTimeoutTime_CVADAS" SG_ 730 FD14_Line_2_Offset 0;
BA_ "GenSigTimeoutTime_ECM" SG_ 730 FD14_Line_2_Offset 0;
BA_ "GenSigTimeoutTime_EPS" SG_ 730 FD14_Line_2_Offset 0;
BA_ "GenSigTimeoutTime_ORC" SG_ 730 FD14_Line_2_Offset 0;
BA_ "GenSigTimeoutTime_BSM" SG_ 730 FD14_Line_2_Start_Range 0;
BA_ "GenSigTimeoutTime_BSM2" SG_ 730 FD14_Line_2_Start_Range 0;
BA_ "GenSigTimeoutTime_CVADAS" SG_ 730 FD14_Line_2_Start_Range 0;
BA_ "GenSigTimeoutTime_ECM" SG_ 730 FD14_Line_2_Start_Range 0;
BA_ "GenSigTimeoutTime_EPS" SG_ 730 FD14_Line_2_Start_Range 0;
BA_ "GenSigTimeoutTime_ORC" SG_ 730 FD14_Line_2_Start_Range 0;
BA_ "GenSigTimeoutTime_BSM" SG_ 730 FD14_Line_2_Type 0;
BA_ "GenSigTimeoutTime_BSM2" SG_ 730 FD14_Line_2_Type 0;
BA_ "GenSigTimeoutTime_CVADAS" SG_ 730 FD14_Line_2_Type 0;
BA_ "GenSigTimeoutTime_ECM" SG_ 730 FD14_Line_2_Type 0;
BA_ "GenSigTimeoutTime_EPS" SG_ 730 FD14_Line_2_Type 0;
BA_ "GenSigTimeoutTime_ORC" SG_ 730 FD14_Line_2_Type 0;
BA_ "GenSigTimeoutTime_BSM" SG_ 730 FD14_Line_3_Confidence 0;
BA_ "GenSigTimeoutTime_BSM2" SG_ 730 FD14_Line_3_Confidence 0;
BA_ "GenSigTimeoutTime_CVADAS" SG_ 730 FD14_Line_3_Confidence 0;
BA_ "GenSigTimeoutTime_ECM" SG_ 730 FD14_Line_3_Confidence 0;
BA_ "GenSigTimeoutTime_EPS" SG_ 730 FD14_Line_3_Confidence 0;
BA_ "GenSigTimeoutTime_ORC" SG_ 730 FD14_Line_3_Confidence 0;
BA_ "GenSigTimeoutTime_BSM" SG_ 730 FD14_Line_3_Curvature 0;
BA_ "GenSigTimeoutTime_BSM2" SG_ 730 FD14_Line_3_Curvature 0;
BA_ "GenSigTimeoutTime_CVADAS" SG_ 730 FD14_Line_3_Curvature 0;
BA_ "GenSigTimeoutTime_ECM" SG_ 730 FD14_Line_3_Curvature 0;
BA_ "GenSigTimeoutTime_EPS" SG_ 730 FD14_Line_3_Curvature 0;
BA_ "GenSigTimeoutTime_ORC" SG_ 730 FD14_Line_3_Curvature 0;
BA_ "GenSigTimeoutTime_BSM" SG_ 730 FD14_Line_3_Curvature_Rate 0;
BA_ "GenSigTimeoutTime_BSM2" SG_ 730 FD14_Line_3_Curvature_Rate 0;
BA_ "GenSigTimeoutTime_CVADAS" SG_ 730 FD14_Line_3_Curvature_Rate 0;
BA_ "GenSigTimeoutTime_ECM" SG_ 730 FD14_Line_3_Curvature_Rate 0;
BA_ "GenSigTimeoutTime_EPS" SG_ 730 FD14_Line_3_Curvature_Rate 0;
BA_ "GenSigTimeoutTime_ORC" SG_ 730 FD14_Line_3_Curvature_Rate 0;
BA_ "GenSigTimeoutTime_BSM" SG_ 730 FD14_Line_3_End_Range 0;
BA_ "GenSigTimeoutTime_BSM2" SG_ 730 FD14_Line_3_End_Range 0;
BA_ "GenSigTimeoutTime_CVADAS" SG_ 730 FD14_Line_3_End_Range 0;
BA_ "GenSigTimeoutTime_ECM" SG_ 730 FD14_Line_3_End_Range 0;
BA_ "GenSigTimeoutTime_EPS" SG_ 730 FD14_Line_3_End_Range 0;
BA_ "GenSigTimeoutTime_ORC" SG_ 730 FD14_Line_3_End_Range 0;
BA_ "GenSigTimeoutTime_BSM" SG_ 730 FD14_Line_3_Heading 0;
BA_ "GenSigTimeoutTime_BSM2" SG_ 730 FD14_Line_3_Heading 0;
BA_ "GenSigTimeoutTime_CVADAS" SG_ 730 FD14_Line_3_Heading 0;
BA_ "GenSigTimeoutTime_ECM" SG_ 730 FD14_Line_3_Heading 0;
BA_ "GenSigTimeoutTime_EPS" SG_ 730 FD14_Line_3_Heading 0;
BA_ "GenSigTimeoutTime_ORC" SG_ 730 FD14_Line_3_Heading 0;
BA_ "GenSigTimeoutTime_BSM" SG_ 730 FD14_Line_3_Offset 0;
BA_ "GenSigTimeoutTime_BSM2" SG_ 730 FD14_Line_3_Offset 0;
BA_ "GenSigTimeoutTime_CVADAS" SG_ 730 FD14_Line_3_Offset 0;
BA_ "GenSigTimeoutTime_ECM" SG_ 730 FD14_Line_3_Offset 0;
BA_ "GenSigTimeoutTime_EPS" SG_ 730 FD14_Line_3_Offset 0;
BA_ "GenSigTimeoutTime_ORC" SG_ 730 FD14_Line_3_Offset 0;
BA_ "GenSigTimeoutTime_BSM" SG_ 730 FD14_Line_3_Start_Range 0;
BA_ "GenSigTimeoutTime_BSM2" SG_ 730 FD14_Line_3_Start_Range 0;
BA_ "GenSigTimeoutTime_CVADAS" SG_ 730 FD14_Line_3_Start_Range 0;
BA_ "GenSigTimeoutTime_ECM" SG_ 730 FD14_Line_3_Start_Range 0;
BA_ "GenSigTimeoutTime_EPS" SG_ 730 FD14_Line_3_Start_Range 0;
BA_ "GenSigTimeoutTime_ORC" SG_ 730 FD14_Line_3_Start_Range 0;
BA_ "GenSigTimeoutTime_BSM" SG_ 730 FD14_Line_3_Type 0;
BA_ "GenSigTimeoutTime_BSM2" SG_ 730 FD14_Line_3_Type 0;
BA_ "GenSigTimeoutTime_CVADAS" SG_ 730 FD14_Line_3_Type 0;
BA_ "GenSigTimeoutTime_ECM" SG_ 730 FD14_Line_3_Type 0;
BA_ "GenSigTimeoutTime_EPS" SG_ 730 FD14_Line_3_Type 0;
BA_ "GenSigTimeoutTime_ORC" SG_ 730 FD14_Line_3_Type 0;
BA_ "GenSigTimeoutTime_BSM" SG_ 730 FD14_Line_4_Confidence 0;
BA_ "GenSigTimeoutTime_BSM2" SG_ 730 FD14_Line_4_Confidence 0;
BA_ "GenSigTimeoutTime_CVADAS" SG_ 730 FD14_Line_4_Confidence 0;
BA_ "GenSigTimeoutTime_ECM" SG_ 730 FD14_Line_4_Confidence 0;
BA_ "GenSigTimeoutTime_EPS" SG_ 730 FD14_Line_4_Confidence 0;
BA_ "GenSigTimeoutTime_ORC" SG_ 730 FD14_Line_4_Confidence 0;
BA_ "GenSigTimeoutTime_BSM" SG_ 730 FD14_Line_4_Curvature 0;
BA_ "GenSigTimeoutTime_BSM2" SG_ 730 FD14_Line_4_Curvature 0;
BA_ "GenSigTimeoutTime_CVADAS" SG_ 730 FD14_Line_4_Curvature 0;
BA_ "GenSigTimeoutTime_ECM" SG_ 730 FD14_Line_4_Curvature 0;
BA_ "GenSigTimeoutTime_EPS" SG_ 730 FD14_Line_4_Curvature 0;
BA_ "GenSigTimeoutTime_ORC" SG_ 730 FD14_Line_4_Curvature 0;
BA_ "GenSigTimeoutTime_BSM" SG_ 730 FD14_Line_4_Curvature_Rate 0;
BA_ "GenSigTimeoutTime_BSM2" SG_ 730 FD14_Line_4_Curvature_Rate 0;
BA_ "GenSigTimeoutTime_CVADAS" SG_ 730 FD14_Line_4_Curvature_Rate 0;
BA_ "GenSigTimeoutTime_ECM" SG_ 730 FD14_Line_4_Curvature_Rate 0;
BA_ "GenSigTimeoutTime_EPS" SG_ 730 FD14_Line_4_Curvature_Rate 0;
BA_ "GenSigTimeoutTime_ORC" SG_ 730 FD14_Line_4_Curvature_Rate 0;
BA_ "GenSigTimeoutTime_BSM" SG_ 730 FD14_Line_4_End_Range 0;
BA_ "GenSigTimeoutTime_BSM2" SG_ 730 FD14_Line_4_End_Range 0;
BA_ "GenSigTimeoutTime_CVADAS" SG_ 730 FD14_Line_4_End_Range 0;
BA_ "GenSigTimeoutTime_ECM" SG_ 730 FD14_Line_4_End_Range 0;
BA_ "GenSigTimeoutTime_EPS" SG_ 730 FD14_Line_4_End_Range 0;
BA_ "GenSigTimeoutTime_ORC" SG_ 730 FD14_Line_4_End_Range 0;
BA_ "GenSigTimeoutTime_BSM" SG_ 730 FD14_Line_4_Heading 0;
BA_ "GenSigTimeoutTime_BSM2" SG_ 730 FD14_Line_4_Heading 0;
BA_ "GenSigTimeoutTime_CVADAS" SG_ 730 FD14_Line_4_Heading 0;
BA_ "GenSigTimeoutTime_ECM" SG_ 730 FD14_Line_4_Heading 0;
BA_ "GenSigTimeoutTime_EPS" SG_ 730 FD14_Line_4_Heading 0;
BA_ "GenSigTimeoutTime_ORC" SG_ 730 FD14_Line_4_Heading 0;
BA_ "GenSigTimeoutTime_BSM" SG_ 730 FD14_Line_4_Offset 0;
BA_ "GenSigTimeoutTime_BSM2" SG_ 730 FD14_Line_4_Offset 0;
BA_ "GenSigTimeoutTime_CVADAS" SG_ 730 FD14_Line_4_Offset 0;
BA_ "GenSigTimeoutTime_ECM" SG_ 730 FD14_Line_4_Offset 0;
BA_ "GenSigTimeoutTime_EPS" SG_ 730 FD14_Line_4_Offset 0;
BA_ "GenSigTimeoutTime_ORC" SG_ 730 FD14_Line_4_Offset 0;
BA_ "GenSigTimeoutTime_BSM" SG_ 730 FD14_Line_4_Start_Range 0;
BA_ "GenSigTimeoutTime_BSM2" SG_ 730 FD14_Line_4_Start_Range 0;
BA_ "GenSigTimeoutTime_CVADAS" SG_ 730 FD14_Line_4_Start_Range 0;
BA_ "GenSigTimeoutTime_ECM" SG_ 730 FD14_Line_4_Start_Range 0;
BA_ "GenSigTimeoutTime_EPS" SG_ 730 FD14_Line_4_Start_Range 0;
BA_ "GenSigTimeoutTime_ORC" SG_ 730 FD14_Line_4_Start_Range 0;
BA_ "GenSigTimeoutTime_BSM" SG_ 730 FD14_Line_4_Type 0;
BA_ "GenSigTimeoutTime_BSM2" SG_ 730 FD14_Line_4_Type 0;
BA_ "GenSigTimeoutTime_CVADAS" SG_ 730 FD14_Line_4_Type 0;
BA_ "GenSigTimeoutTime_ECM" SG_ 730 FD14_Line_4_Type 0;
BA_ "GenSigTimeoutTime_EPS" SG_ 730 FD14_Line_4_Type 0;
BA_ "GenSigTimeoutTime_ORC" SG_ 730 FD14_Line_4_Type 0;
BA_ "GenSigTimeoutTime_BSM" SG_ 730 FD14_MAC_ADAS_FD_LANES_1 0;
BA_ "GenSigTimeoutTime_BSM2" SG_ 730 FD14_MAC_ADAS_FD_LANES_1 0;
BA_ "GenSigTimeoutTime_CVADAS" SG_ 730 FD14_MAC_ADAS_FD_LANES_1 0;
BA_ "GenSigTimeoutTime_ECM" SG_ 730 FD14_MAC_ADAS_FD_LANES_1 0;
BA_ "GenSigTimeoutTime_EPS" SG_ 730 FD14_MAC_ADAS_FD_LANES_1 0;
BA_ "GenSigTimeoutTime_ORC" SG_ 730 FD14_MAC_ADAS_FD_LANES_1 0;
BA_ "GenSigTimeoutTime_BSM" SG_ 730 FD14_MessageCounter_ADAS_FD_LANE 0;
BA_ "GenSigTimeoutTime_BSM2" SG_ 730 FD14_MessageCounter_ADAS_FD_LANE 0;
BA_ "GenSigTimeoutTime_CVADAS" SG_ 730 FD14_MessageCounter_ADAS_FD_LANE 0;
BA_ "GenSigTimeoutTime_ECM" SG_ 730 FD14_MessageCounter_ADAS_FD_LANE 0;
BA_ "GenSigTimeoutTime_EPS" SG_ 730 FD14_MessageCounter_ADAS_FD_LANE 0;
BA_ "GenSigTimeoutTime_ORC" SG_ 730 FD14_MessageCounter_ADAS_FD_LANE 0;
BA_ "SystemSignalLongSymbol" SG_ 730 FD14_MessageCounter_ADAS_FD_LANE "FD14_MessageCounter_ADAS_FD_LANES_1";
BA_ "GenSigTimeoutTime_BSM" SG_ 730 FD14_Reserved_for_functional_saf 0;
BA_ "GenSigTimeoutTime_BSM2" SG_ 730 FD14_Reserved_for_functional_saf 0;
BA_ "GenSigTimeoutTime_CVADAS" SG_ 730 FD14_Reserved_for_functional_saf 0;
BA_ "GenSigTimeoutTime_ECM" SG_ 730 FD14_Reserved_for_functional_saf 0;
BA_ "GenSigTimeoutTime_EPS" SG_ 730 FD14_Reserved_for_functional_saf 0;
BA_ "GenSigTimeoutTime_ORC" SG_ 730 FD14_Reserved_for_functional_saf 0;
BA_ "SystemSignalLongSymbol" SG_ 730 FD14_Reserved_for_functional_saf "FD14_Reserved_for_functional_safety";
BA_ "GenSigTimeoutTime_BSM" SG_ 734 FD14_Cntr_ADAS_FD_LANES_2 0;
BA_ "GenSigTimeoutTime_BSM2" SG_ 734 FD14_Cntr_ADAS_FD_LANES_2 0;
BA_ "GenSigTimeoutTime_CVADAS" SG_ 734 FD14_Cntr_ADAS_FD_LANES_2 0;
BA_ "GenSigTimeoutTime_ECM" SG_ 734 FD14_Cntr_ADAS_FD_LANES_2 0;
BA_ "GenSigTimeoutTime_EPS" SG_ 734 FD14_Cntr_ADAS_FD_LANES_2 0;
BA_ "GenSigTimeoutTime_ORC" SG_ 734 FD14_Cntr_ADAS_FD_LANES_2 0;
BA_ "GenSigTimeoutTime_BSM" SG_ 734 FD14_CRC_ADAS_FD_LANES_2 0;
BA_ "GenSigTimeoutTime_BSM2" SG_ 734 FD14_CRC_ADAS_FD_LANES_2 0;
BA_ "GenSigTimeoutTime_CVADAS" SG_ 734 FD14_CRC_ADAS_FD_LANES_2 0;
BA_ "GenSigTimeoutTime_ECM" SG_ 734 FD14_CRC_ADAS_FD_LANES_2 0;
BA_ "GenSigTimeoutTime_EPS" SG_ 734 FD14_CRC_ADAS_FD_LANES_2 0;
BA_ "GenSigTimeoutTime_ORC" SG_ 734 FD14_CRC_ADAS_FD_LANES_2 0;
BA_ "GenSigTimeoutTime_BSM" SG_ 734 FD14_Frame_Index_Lanes_2 0;
BA_ "GenSigTimeoutTime_BSM2" SG_ 734 FD14_Frame_Index_Lanes_2 0;
BA_ "GenSigTimeoutTime_CVADAS" SG_ 734 FD14_Frame_Index_Lanes_2 0;
BA_ "GenSigTimeoutTime_ECM" SG_ 734 FD14_Frame_Index_Lanes_2 0;
BA_ "GenSigTimeoutTime_EPS" SG_ 734 FD14_Frame_Index_Lanes_2 0;
BA_ "GenSigTimeoutTime_ORC" SG_ 734 FD14_Frame_Index_Lanes_2 0;
BA_ "GenSigTimeoutTime_BSM" SG_ 734 FD14_MAC_ADAS_FD_LANES_2 0;
BA_ "GenSigTimeoutTime_BSM2" SG_ 734 FD14_MAC_ADAS_FD_LANES_2 0;
BA_ "GenSigTimeoutTime_CVADAS" SG_ 734 FD14_MAC_ADAS_FD_LANES_2 0;
BA_ "GenSigTimeoutTime_ECM" SG_ 734 FD14_MAC_ADAS_FD_LANES_2 0;
BA_ "GenSigTimeoutTime_EPS" SG_ 734 FD14_MAC_ADAS_FD_LANES_2 0;
BA_ "GenSigTimeoutTime_ORC" SG_ 734 FD14_MAC_ADAS_FD_LANES_2 0;
BA_ "GenSigTimeoutTime_BSM" SG_ 734 FD14_MessageCounter_ADAS_FD_0001 0;
BA_ "GenSigTimeoutTime_BSM2" SG_ 734 FD14_MessageCounter_ADAS_FD_0001 0;
BA_ "GenSigTimeoutTime_CVADAS" SG_ 734 FD14_MessageCounter_ADAS_FD_0001 0;
BA_ "GenSigTimeoutTime_ECM" SG_ 734 FD14_MessageCounter_ADAS_FD_0001 0;
BA_ "GenSigTimeoutTime_EPS" SG_ 734 FD14_MessageCounter_ADAS_FD_0001 0;
BA_ "GenSigTimeoutTime_ORC" SG_ 734 FD14_MessageCounter_ADAS_FD_0001 0;
BA_ "SystemSignalLongSymbol" SG_ 734 FD14_MessageCounter_ADAS_FD_0001 "FD14_MessageCounter_ADAS_FD_LANES_2";
BA_ "GenSigTimeoutTime_BSM" SG_ 734 FD14_Reserved_for_functiona_0000 0;
BA_ "GenSigTimeoutTime_BSM2" SG_ 734 FD14_Reserved_for_functiona_0000 0;
BA_ "GenSigTimeoutTime_CVADAS" SG_ 734 FD14_Reserved_for_functiona_0000 0;
BA_ "GenSigTimeoutTime_ECM" SG_ 734 FD14_Reserved_for_functiona_0000 0;
BA_ "GenSigTimeoutTime_EPS" SG_ 734 FD14_Reserved_for_functiona_0000 0;
BA_ "GenSigTimeoutTime_ORC" SG_ 734 FD14_Reserved_for_functiona_0000 0;
BA_ "SystemSignalLongSymbol" SG_ 734 FD14_Reserved_for_functiona_0000 "FD14_Reserved_for_functional_safety";
BA_ "GenSigTimeoutTime_BSM" SG_ 734 FD14_Segment_1_Confidence 0;
BA_ "GenSigTimeoutTime_BSM2" SG_ 734 FD14_Segment_1_Confidence 0;
BA_ "GenSigTimeoutTime_CVADAS" SG_ 734 FD14_Segment_1_Confidence 0;
BA_ "GenSigTimeoutTime_ECM" SG_ 734 FD14_Segment_1_Confidence 0;
BA_ "GenSigTimeoutTime_EPS" SG_ 734 FD14_Segment_1_Confidence 0;
BA_ "GenSigTimeoutTime_ORC" SG_ 734 FD14_Segment_1_Confidence 0;
BA_ "GenSigTimeoutTime_BSM" SG_ 734 FD14_Segment_1_ID 0;
BA_ "GenSigTimeoutTime_BSM2" SG_ 734 FD14_Segment_1_ID 0;
BA_ "GenSigTimeoutTime_CVADAS" SG_ 734 FD14_Segment_1_ID 0;
BA_ "GenSigTimeoutTime_ECM" SG_ 734 FD14_Segment_1_ID 0;
BA_ "GenSigTimeoutTime_EPS" SG_ 734 FD14_Segment_1_ID 0;
BA_ "GenSigTimeoutTime_ORC" SG_ 734 FD14_Segment_1_ID 0;
BA_ "GenSigTimeoutTime_BSM" SG_ 734 FD14_Segment_1_X1 0;
BA_ "GenSigTimeoutTime_BSM2" SG_ 734 FD14_Segment_1_X1 0;
BA_ "GenSigTimeoutTime_CVADAS" SG_ 734 FD14_Segment_1_X1 0;
BA_ "GenSigTimeoutTime_ECM" SG_ 734 FD14_Segment_1_X1 0;
BA_ "GenSigTimeoutTime_EPS" SG_ 734 FD14_Segment_1_X1 0;
BA_ "GenSigTimeoutTime_ORC" SG_ 734 FD14_Segment_1_X1 0;
BA_ "GenSigTimeoutTime_BSM" SG_ 734 FD14_Segment_1_X2 0;
BA_ "GenSigTimeoutTime_BSM2" SG_ 734 FD14_Segment_1_X2 0;
BA_ "GenSigTimeoutTime_CVADAS" SG_ 734 FD14_Segment_1_X2 0;
BA_ "GenSigTimeoutTime_ECM" SG_ 734 FD14_Segment_1_X2 0;
BA_ "GenSigTimeoutTime_EPS" SG_ 734 FD14_Segment_1_X2 0;
BA_ "GenSigTimeoutTime_ORC" SG_ 734 FD14_Segment_1_X2 0;
BA_ "GenSigTimeoutTime_BSM" SG_ 734 FD14_Segment_1_Y1 0;
BA_ "GenSigTimeoutTime_BSM2" SG_ 734 FD14_Segment_1_Y1 0;
BA_ "GenSigTimeoutTime_CVADAS" SG_ 734 FD14_Segment_1_Y1 0;
BA_ "GenSigTimeoutTime_ECM" SG_ 734 FD14_Segment_1_Y1 0;
BA_ "GenSigTimeoutTime_EPS" SG_ 734 FD14_Segment_1_Y1 0;
BA_ "GenSigTimeoutTime_ORC" SG_ 734 FD14_Segment_1_Y1 0;
BA_ "GenSigTimeoutTime_BSM" SG_ 734 FD14_Segment_1_Y2 0;
BA_ "GenSigTimeoutTime_BSM2" SG_ 734 FD14_Segment_1_Y2 0;
BA_ "GenSigTimeoutTime_CVADAS" SG_ 734 FD14_Segment_1_Y2 0;
BA_ "GenSigTimeoutTime_ECM" SG_ 734 FD14_Segment_1_Y2 0;
BA_ "GenSigTimeoutTime_EPS" SG_ 734 FD14_Segment_1_Y2 0;
BA_ "GenSigTimeoutTime_ORC" SG_ 734 FD14_Segment_1_Y2 0;
BA_ "GenSigTimeoutTime_BSM" SG_ 734 FD14_Segment_2_Confidence 0;
BA_ "GenSigTimeoutTime_BSM2" SG_ 734 FD14_Segment_2_Confidence 0;
BA_ "GenSigTimeoutTime_CVADAS" SG_ 734 FD14_Segment_2_Confidence 0;
BA_ "GenSigTimeoutTime_ECM" SG_ 734 FD14_Segment_2_Confidence 0;
BA_ "GenSigTimeoutTime_EPS" SG_ 734 FD14_Segment_2_Confidence 0;
BA_ "GenSigTimeoutTime_ORC" SG_ 734 FD14_Segment_2_Confidence 0;
BA_ "GenSigTimeoutTime_BSM" SG_ 734 FD14_Segment_2_ID 0;
BA_ "GenSigTimeoutTime_BSM2" SG_ 734 FD14_Segment_2_ID 0;
BA_ "GenSigTimeoutTime_CVADAS" SG_ 734 FD14_Segment_2_ID 0;
BA_ "GenSigTimeoutTime_ECM" SG_ 734 FD14_Segment_2_ID 0;
BA_ "GenSigTimeoutTime_EPS" SG_ 734 FD14_Segment_2_ID 0;
BA_ "GenSigTimeoutTime_ORC" SG_ 734 FD14_Segment_2_ID 0;
BA_ "GenSigTimeoutTime_BSM" SG_ 734 FD14_Segment_2_X1 0;
BA_ "GenSigTimeoutTime_BSM2" SG_ 734 FD14_Segment_2_X1 0;
BA_ "GenSigTimeoutTime_CVADAS" SG_ 734 FD14_Segment_2_X1 0;
BA_ "GenSigTimeoutTime_ECM" SG_ 734 FD14_Segment_2_X1 0;
BA_ "GenSigTimeoutTime_EPS" SG_ 734 FD14_Segment_2_X1 0;
BA_ "GenSigTimeoutTime_ORC" SG_ 734 FD14_Segment_2_X1 0;
BA_ "GenSigTimeoutTime_BSM" SG_ 734 FD14_Segment_2_X2 0;
BA_ "GenSigTimeoutTime_BSM2" SG_ 734 FD14_Segment_2_X2 0;
BA_ "GenSigTimeoutTime_CVADAS" SG_ 734 FD14_Segment_2_X2 0;
BA_ "GenSigTimeoutTime_ECM" SG_ 734 FD14_Segment_2_X2 0;
BA_ "GenSigTimeoutTime_EPS" SG_ 734 FD14_Segment_2_X2 0;
BA_ "GenSigTimeoutTime_ORC" SG_ 734 FD14_Segment_2_X2 0;
BA_ "GenSigTimeoutTime_BSM" SG_ 734 FD14_Segment_2_Y1 0;
BA_ "GenSigTimeoutTime_BSM2" SG_ 734 FD14_Segment_2_Y1 0;
BA_ "GenSigTimeoutTime_CVADAS" SG_ 734 FD14_Segment_2_Y1 0;
BA_ "GenSigTimeoutTime_ECM" SG_ 734 FD14_Segment_2_Y1 0;
BA_ "GenSigTimeoutTime_EPS" SG_ 734 FD14_Segment_2_Y1 0;
BA_ "GenSigTimeoutTime_ORC" SG_ 734 FD14_Segment_2_Y1 0;
BA_ "GenSigTimeoutTime_BSM" SG_ 734 FD14_Segment_2_Y2 0;
BA_ "GenSigTimeoutTime_BSM2" SG_ 734 FD14_Segment_2_Y2 0;
BA_ "GenSigTimeoutTime_CVADAS" SG_ 734 FD14_Segment_2_Y2 0;
BA_ "GenSigTimeoutTime_ECM" SG_ 734 FD14_Segment_2_Y2 0;
BA_ "GenSigTimeoutTime_EPS" SG_ 734 FD14_Segment_2_Y2 0;
BA_ "GenSigTimeoutTime_ORC" SG_ 734 FD14_Segment_2_Y2 0;
BA_ "GenSigTimeoutTime_BSM" SG_ 734 FD14_Segment_3_Confidence 0;
BA_ "GenSigTimeoutTime_BSM2" SG_ 734 FD14_Segment_3_Confidence 0;
BA_ "GenSigTimeoutTime_CVADAS" SG_ 734 FD14_Segment_3_Confidence 0;
BA_ "GenSigTimeoutTime_ECM" SG_ 734 FD14_Segment_3_Confidence 0;
BA_ "GenSigTimeoutTime_EPS" SG_ 734 FD14_Segment_3_Confidence 0;
BA_ "GenSigTimeoutTime_ORC" SG_ 734 FD14_Segment_3_Confidence 0;
BA_ "GenSigTimeoutTime_BSM" SG_ 734 FD14_Segment_3_ID 0;
BA_ "GenSigTimeoutTime_BSM2" SG_ 734 FD14_Segment_3_ID 0;
BA_ "GenSigTimeoutTime_CVADAS" SG_ 734 FD14_Segment_3_ID 0;
BA_ "GenSigTimeoutTime_ECM" SG_ 734 FD14_Segment_3_ID 0;
BA_ "GenSigTimeoutTime_EPS" SG_ 734 FD14_Segment_3_ID 0;
BA_ "GenSigTimeoutTime_ORC" SG_ 734 FD14_Segment_3_ID 0;
BA_ "GenSigTimeoutTime_BSM" SG_ 734 FD14_Segment_3_X1 0;
BA_ "GenSigTimeoutTime_BSM2" SG_ 734 FD14_Segment_3_X1 0;
BA_ "GenSigTimeoutTime_CVADAS" SG_ 734 FD14_Segment_3_X1 0;
BA_ "GenSigTimeoutTime_ECM" SG_ 734 FD14_Segment_3_X1 0;
BA_ "GenSigTimeoutTime_EPS" SG_ 734 FD14_Segment_3_X1 0;
BA_ "GenSigTimeoutTime_ORC" SG_ 734 FD14_Segment_3_X1 0;
BA_ "GenSigTimeoutTime_BSM" SG_ 734 FD14_Segment_3_X2 0;
BA_ "GenSigTimeoutTime_BSM2" SG_ 734 FD14_Segment_3_X2 0;
BA_ "GenSigTimeoutTime_CVADAS" SG_ 734 FD14_Segment_3_X2 0;
BA_ "GenSigTimeoutTime_ECM" SG_ 734 FD14_Segment_3_X2 0;
BA_ "GenSigTimeoutTime_EPS" SG_ 734 FD14_Segment_3_X2 0;
BA_ "GenSigTimeoutTime_ORC" SG_ 734 FD14_Segment_3_X2 0;
BA_ "GenSigTimeoutTime_BSM" SG_ 734 FD14_Segment_3_Y1 0;
BA_ "GenSigTimeoutTime_BSM2" SG_ 734 FD14_Segment_3_Y1 0;
BA_ "GenSigTimeoutTime_CVADAS" SG_ 734 FD14_Segment_3_Y1 0;
BA_ "GenSigTimeoutTime_ECM" SG_ 734 FD14_Segment_3_Y1 0;
BA_ "GenSigTimeoutTime_EPS" SG_ 734 FD14_Segment_3_Y1 0;
BA_ "GenSigTimeoutTime_ORC" SG_ 734 FD14_Segment_3_Y1 0;
BA_ "GenSigTimeoutTime_BSM" SG_ 734 FD14_Segment_3_Y2 0;
BA_ "GenSigTimeoutTime_BSM2" SG_ 734 FD14_Segment_3_Y2 0;
BA_ "GenSigTimeoutTime_CVADAS" SG_ 734 FD14_Segment_3_Y2 0;
BA_ "GenSigTimeoutTime_ECM" SG_ 734 FD14_Segment_3_Y2 0;
BA_ "GenSigTimeoutTime_EPS" SG_ 734 FD14_Segment_3_Y2 0;
BA_ "GenSigTimeoutTime_ORC" SG_ 734 FD14_Segment_3_Y2 0;
BA_ "GenSigTimeoutTime_BSM" SG_ 734 FD14_Segment_4_Confidence 0;
BA_ "GenSigTimeoutTime_BSM2" SG_ 734 FD14_Segment_4_Confidence 0;
BA_ "GenSigTimeoutTime_CVADAS" SG_ 734 FD14_Segment_4_Confidence 0;
BA_ "GenSigTimeoutTime_ECM" SG_ 734 FD14_Segment_4_Confidence 0;
BA_ "GenSigTimeoutTime_EPS" SG_ 734 FD14_Segment_4_Confidence 0;
BA_ "GenSigTimeoutTime_ORC" SG_ 734 FD14_Segment_4_Confidence 0;
BA_ "GenSigTimeoutTime_BSM" SG_ 734 FD14_Segment_4_ID 0;
BA_ "GenSigTimeoutTime_BSM2" SG_ 734 FD14_Segment_4_ID 0;
BA_ "GenSigTimeoutTime_CVADAS" SG_ 734 FD14_Segment_4_ID 0;
BA_ "GenSigTimeoutTime_ECM" SG_ 734 FD14_Segment_4_ID 0;
BA_ "GenSigTimeoutTime_EPS" SG_ 734 FD14_Segment_4_ID 0;
BA_ "GenSigTimeoutTime_ORC" SG_ 734 FD14_Segment_4_ID 0;
BA_ "GenSigTimeoutTime_BSM" SG_ 734 FD14_Segment_4_X1 0;
BA_ "GenSigTimeoutTime_BSM2" SG_ 734 FD14_Segment_4_X1 0;
BA_ "GenSigTimeoutTime_CVADAS" SG_ 734 FD14_Segment_4_X1 0;
BA_ "GenSigTimeoutTime_ECM" SG_ 734 FD14_Segment_4_X1 0;
BA_ "GenSigTimeoutTime_EPS" SG_ 734 FD14_Segment_4_X1 0;
BA_ "GenSigTimeoutTime_ORC" SG_ 734 FD14_Segment_4_X1 0;
BA_ "GenSigTimeoutTime_BSM" SG_ 734 FD14_Segment_4_X2 0;
BA_ "GenSigTimeoutTime_BSM2" SG_ 734 FD14_Segment_4_X2 0;
BA_ "GenSigTimeoutTime_CVADAS" SG_ 734 FD14_Segment_4_X2 0;
BA_ "GenSigTimeoutTime_ECM" SG_ 734 FD14_Segment_4_X2 0;
BA_ "GenSigTimeoutTime_EPS" SG_ 734 FD14_Segment_4_X2 0;
BA_ "GenSigTimeoutTime_ORC" SG_ 734 FD14_Segment_4_X2 0;
BA_ "GenSigTimeoutTime_BSM" SG_ 734 FD14_Segment_4_Y1 0;
BA_ "GenSigTimeoutTime_BSM2" SG_ 734 FD14_Segment_4_Y1 0;
BA_ "GenSigTimeoutTime_CVADAS" SG_ 734 FD14_Segment_4_Y1 0;
BA_ "GenSigTimeoutTime_ECM" SG_ 734 FD14_Segment_4_Y1 0;
BA_ "GenSigTimeoutTime_EPS" SG_ 734 FD14_Segment_4_Y1 0;
BA_ "GenSigTimeoutTime_ORC" SG_ 734 FD14_Segment_4_Y1 0;
BA_ "GenSigTimeoutTime_BSM" SG_ 734 FD14_Segment_4_Y2 0;
BA_ "GenSigTimeoutTime_BSM2" SG_ 734 FD14_Segment_4_Y2 0;
BA_ "GenSigTimeoutTime_CVADAS" SG_ 734 FD14_Segment_4_Y2 0;
BA_ "GenSigTimeoutTime_ECM" SG_ 734 FD14_Segment_4_Y2 0;
BA_ "GenSigTimeoutTime_EPS" SG_ 734 FD14_Segment_4_Y2 0;
BA_ "GenSigTimeoutTime_ORC" SG_ 734 FD14_Segment_4_Y2 0;
BA_ "GenSigTimeoutTime_BSM" SG_ 734 FD14_Segment_5_Confidence 0;
BA_ "GenSigTimeoutTime_BSM2" SG_ 734 FD14_Segment_5_Confidence 0;
BA_ "GenSigTimeoutTime_CVADAS" SG_ 734 FD14_Segment_5_Confidence 0;
BA_ "GenSigTimeoutTime_ECM" SG_ 734 FD14_Segment_5_Confidence 0;
BA_ "GenSigTimeoutTime_EPS" SG_ 734 FD14_Segment_5_Confidence 0;
BA_ "GenSigTimeoutTime_ORC" SG_ 734 FD14_Segment_5_Confidence 0;
BA_ "GenSigTimeoutTime_BSM" SG_ 734 FD14_Segment_5_ID 0;
BA_ "GenSigTimeoutTime_BSM2" SG_ 734 FD14_Segment_5_ID 0;
BA_ "GenSigTimeoutTime_CVADAS" SG_ 734 FD14_Segment_5_ID 0;
BA_ "GenSigTimeoutTime_ECM" SG_ 734 FD14_Segment_5_ID 0;
BA_ "GenSigTimeoutTime_EPS" SG_ 734 FD14_Segment_5_ID 0;
BA_ "GenSigTimeoutTime_ORC" SG_ 734 FD14_Segment_5_ID 0;
BA_ "GenSigTimeoutTime_BSM" SG_ 734 FD14_Segment_5_X1 0;
BA_ "GenSigTimeoutTime_BSM2" SG_ 734 FD14_Segment_5_X1 0;
BA_ "GenSigTimeoutTime_CVADAS" SG_ 734 FD14_Segment_5_X1 0;
BA_ "GenSigTimeoutTime_ECM" SG_ 734 FD14_Segment_5_X1 0;
BA_ "GenSigTimeoutTime_EPS" SG_ 734 FD14_Segment_5_X1 0;
BA_ "GenSigTimeoutTime_ORC" SG_ 734 FD14_Segment_5_X1 0;
BA_ "GenSigTimeoutTime_BSM" SG_ 734 FD14_Segment_5_X2 0;
BA_ "GenSigTimeoutTime_BSM2" SG_ 734 FD14_Segment_5_X2 0;
BA_ "GenSigTimeoutTime_CVADAS" SG_ 734 FD14_Segment_5_X2 0;
BA_ "GenSigTimeoutTime_ECM" SG_ 734 FD14_Segment_5_X2 0;
BA_ "GenSigTimeoutTime_EPS" SG_ 734 FD14_Segment_5_X2 0;
BA_ "GenSigTimeoutTime_ORC" SG_ 734 FD14_Segment_5_X2 0;
BA_ "GenSigTimeoutTime_BSM" SG_ 734 FD14_Segment_5_Y1 0;
BA_ "GenSigTimeoutTime_BSM2" SG_ 734 FD14_Segment_5_Y1 0;
BA_ "GenSigTimeoutTime_CVADAS" SG_ 734 FD14_Segment_5_Y1 0;
BA_ "GenSigTimeoutTime_ECM" SG_ 734 FD14_Segment_5_Y1 0;
BA_ "GenSigTimeoutTime_EPS" SG_ 734 FD14_Segment_5_Y1 0;
BA_ "GenSigTimeoutTime_ORC" SG_ 734 FD14_Segment_5_Y1 0;
BA_ "GenSigTimeoutTime_BSM" SG_ 734 FD14_Segment_5_Y2 0;
BA_ "GenSigTimeoutTime_BSM2" SG_ 734 FD14_Segment_5_Y2 0;
BA_ "GenSigTimeoutTime_CVADAS" SG_ 734 FD14_Segment_5_Y2 0;
BA_ "GenSigTimeoutTime_ECM" SG_ 734 FD14_Segment_5_Y2 0;
BA_ "GenSigTimeoutTime_EPS" SG_ 734 FD14_Segment_5_Y2 0;
BA_ "GenSigTimeoutTime_ORC" SG_ 734 FD14_Segment_5_Y2 0;
BA_ "GenSigTimeoutTime_BSM" SG_ 734 FD14_Segment_6_Confidence 0;
BA_ "GenSigTimeoutTime_BSM2" SG_ 734 FD14_Segment_6_Confidence 0;
BA_ "GenSigTimeoutTime_CVADAS" SG_ 734 FD14_Segment_6_Confidence 0;
BA_ "GenSigTimeoutTime_ECM" SG_ 734 FD14_Segment_6_Confidence 0;
BA_ "GenSigTimeoutTime_EPS" SG_ 734 FD14_Segment_6_Confidence 0;
BA_ "GenSigTimeoutTime_ORC" SG_ 734 FD14_Segment_6_Confidence 0;
BA_ "GenSigTimeoutTime_BSM" SG_ 734 FD14_Segment_6_ID 0;
BA_ "GenSigTimeoutTime_BSM2" SG_ 734 FD14_Segment_6_ID 0;
BA_ "GenSigTimeoutTime_CVADAS" SG_ 734 FD14_Segment_6_ID 0;
BA_ "GenSigTimeoutTime_ECM" SG_ 734 FD14_Segment_6_ID 0;
BA_ "GenSigTimeoutTime_EPS" SG_ 734 FD14_Segment_6_ID 0;
BA_ "GenSigTimeoutTime_ORC" SG_ 734 FD14_Segment_6_ID 0;
BA_ "GenSigTimeoutTime_BSM" SG_ 734 FD14_Segment_6_X1 0;
BA_ "GenSigTimeoutTime_BSM2" SG_ 734 FD14_Segment_6_X1 0;
BA_ "GenSigTimeoutTime_CVADAS" SG_ 734 FD14_Segment_6_X1 0;
BA_ "GenSigTimeoutTime_ECM" SG_ 734 FD14_Segment_6_X1 0;
BA_ "GenSigTimeoutTime_EPS" SG_ 734 FD14_Segment_6_X1 0;
BA_ "GenSigTimeoutTime_ORC" SG_ 734 FD14_Segment_6_X1 0;
BA_ "GenSigTimeoutTime_BSM" SG_ 734 FD14_Segment_6_X2 0;
BA_ "GenSigTimeoutTime_BSM2" SG_ 734 FD14_Segment_6_X2 0;
BA_ "GenSigTimeoutTime_CVADAS" SG_ 734 FD14_Segment_6_X2 0;
BA_ "GenSigTimeoutTime_ECM" SG_ 734 FD14_Segment_6_X2 0;
BA_ "GenSigTimeoutTime_EPS" SG_ 734 FD14_Segment_6_X2 0;
BA_ "GenSigTimeoutTime_ORC" SG_ 734 FD14_Segment_6_X2 0;
BA_ "GenSigTimeoutTime_BSM" SG_ 734 FD14_Segment_6_Y1 0;
BA_ "GenSigTimeoutTime_BSM2" SG_ 734 FD14_Segment_6_Y1 0;
BA_ "GenSigTimeoutTime_CVADAS" SG_ 734 FD14_Segment_6_Y1 0;
BA_ "GenSigTimeoutTime_ECM" SG_ 734 FD14_Segment_6_Y1 0;
BA_ "GenSigTimeoutTime_EPS" SG_ 734 FD14_Segment_6_Y1 0;
BA_ "GenSigTimeoutTime_ORC" SG_ 734 FD14_Segment_6_Y1 0;
BA_ "GenSigTimeoutTime_BSM" SG_ 734 FD14_Segment_6_Y2 0;
BA_ "GenSigTimeoutTime_BSM2" SG_ 734 FD14_Segment_6_Y2 0;
BA_ "GenSigTimeoutTime_CVADAS" SG_ 734 FD14_Segment_6_Y2 0;
BA_ "GenSigTimeoutTime_ECM" SG_ 734 FD14_Segment_6_Y2 0;
BA_ "GenSigTimeoutTime_EPS" SG_ 734 FD14_Segment_6_Y2 0;
BA_ "GenSigTimeoutTime_ORC" SG_ 734 FD14_Segment_6_Y2 0;
BA_ "GenSigTimeoutTime_BSM" SG_ 734 FD14_Segment_7_Confidence 0;
BA_ "GenSigTimeoutTime_BSM2" SG_ 734 FD14_Segment_7_Confidence 0;
BA_ "GenSigTimeoutTime_CVADAS" SG_ 734 FD14_Segment_7_Confidence 0;
BA_ "GenSigTimeoutTime_ECM" SG_ 734 FD14_Segment_7_Confidence 0;
BA_ "GenSigTimeoutTime_EPS" SG_ 734 FD14_Segment_7_Confidence 0;
BA_ "GenSigTimeoutTime_ORC" SG_ 734 FD14_Segment_7_Confidence 0;
BA_ "GenSigTimeoutTime_BSM" SG_ 734 FD14_Segment_7_ID 0;
BA_ "GenSigTimeoutTime_BSM2" SG_ 734 FD14_Segment_7_ID 0;
BA_ "GenSigTimeoutTime_CVADAS" SG_ 734 FD14_Segment_7_ID 0;
BA_ "GenSigTimeoutTime_ECM" SG_ 734 FD14_Segment_7_ID 0;
BA_ "GenSigTimeoutTime_EPS" SG_ 734 FD14_Segment_7_ID 0;
BA_ "GenSigTimeoutTime_ORC" SG_ 734 FD14_Segment_7_ID 0;
BA_ "GenSigTimeoutTime_BSM" SG_ 734 FD14_Segment_7_X1 0;
BA_ "GenSigTimeoutTime_BSM2" SG_ 734 FD14_Segment_7_X1 0;
BA_ "GenSigTimeoutTime_CVADAS" SG_ 734 FD14_Segment_7_X1 0;
BA_ "GenSigTimeoutTime_ECM" SG_ 734 FD14_Segment_7_X1 0;
BA_ "GenSigTimeoutTime_EPS" SG_ 734 FD14_Segment_7_X1 0;
BA_ "GenSigTimeoutTime_ORC" SG_ 734 FD14_Segment_7_X1 0;
BA_ "GenSigTimeoutTime_BSM" SG_ 734 FD14_Segment_7_X2 0;
BA_ "GenSigTimeoutTime_BSM2" SG_ 734 FD14_Segment_7_X2 0;
BA_ "GenSigTimeoutTime_CVADAS" SG_ 734 FD14_Segment_7_X2 0;
BA_ "GenSigTimeoutTime_ECM" SG_ 734 FD14_Segment_7_X2 0;
BA_ "GenSigTimeoutTime_EPS" SG_ 734 FD14_Segment_7_X2 0;
BA_ "GenSigTimeoutTime_ORC" SG_ 734 FD14_Segment_7_X2 0;
BA_ "GenSigTimeoutTime_BSM" SG_ 734 FD14_Segment_7_Y1 0;
BA_ "GenSigTimeoutTime_BSM2" SG_ 734 FD14_Segment_7_Y1 0;
BA_ "GenSigTimeoutTime_CVADAS" SG_ 734 FD14_Segment_7_Y1 0;
BA_ "GenSigTimeoutTime_ECM" SG_ 734 FD14_Segment_7_Y1 0;
BA_ "GenSigTimeoutTime_EPS" SG_ 734 FD14_Segment_7_Y1 0;
BA_ "GenSigTimeoutTime_ORC" SG_ 734 FD14_Segment_7_Y1 0;
BA_ "GenSigTimeoutTime_BSM" SG_ 734 FD14_Segment_7_Y2 0;
BA_ "GenSigTimeoutTime_BSM2" SG_ 734 FD14_Segment_7_Y2 0;
BA_ "GenSigTimeoutTime_CVADAS" SG_ 734 FD14_Segment_7_Y2 0;
BA_ "GenSigTimeoutTime_ECM" SG_ 734 FD14_Segment_7_Y2 0;
BA_ "GenSigTimeoutTime_EPS" SG_ 734 FD14_Segment_7_Y2 0;
BA_ "GenSigTimeoutTime_ORC" SG_ 734 FD14_Segment_7_Y2 0;
BA_ "GenSigTimeoutTime_BSM" SG_ 734 FD14_Segment_8_Confidence 0;
BA_ "GenSigTimeoutTime_BSM2" SG_ 734 FD14_Segment_8_Confidence 0;
BA_ "GenSigTimeoutTime_CVADAS" SG_ 734 FD14_Segment_8_Confidence 0;
BA_ "GenSigTimeoutTime_ECM" SG_ 734 FD14_Segment_8_Confidence 0;
BA_ "GenSigTimeoutTime_EPS" SG_ 734 FD14_Segment_8_Confidence 0;
BA_ "GenSigTimeoutTime_ORC" SG_ 734 FD14_Segment_8_Confidence 0;
BA_ "GenSigTimeoutTime_BSM" SG_ 734 FD14_Segment_8_ID 0;
BA_ "GenSigTimeoutTime_BSM2" SG_ 734 FD14_Segment_8_ID 0;
BA_ "GenSigTimeoutTime_CVADAS" SG_ 734 FD14_Segment_8_ID 0;
BA_ "GenSigTimeoutTime_ECM" SG_ 734 FD14_Segment_8_ID 0;
BA_ "GenSigTimeoutTime_EPS" SG_ 734 FD14_Segment_8_ID 0;
BA_ "GenSigTimeoutTime_ORC" SG_ 734 FD14_Segment_8_ID 0;
BA_ "GenSigTimeoutTime_BSM" SG_ 734 FD14_Segment_8_X1 0;
BA_ "GenSigTimeoutTime_BSM2" SG_ 734 FD14_Segment_8_X1 0;
BA_ "GenSigTimeoutTime_CVADAS" SG_ 734 FD14_Segment_8_X1 0;
BA_ "GenSigTimeoutTime_ECM" SG_ 734 FD14_Segment_8_X1 0;
BA_ "GenSigTimeoutTime_EPS" SG_ 734 FD14_Segment_8_X1 0;
BA_ "GenSigTimeoutTime_ORC" SG_ 734 FD14_Segment_8_X1 0;
BA_ "GenSigTimeoutTime_BSM" SG_ 734 FD14_Segment_8_X2 0;
BA_ "GenSigTimeoutTime_BSM2" SG_ 734 FD14_Segment_8_X2 0;
BA_ "GenSigTimeoutTime_CVADAS" SG_ 734 FD14_Segment_8_X2 0;
BA_ "GenSigTimeoutTime_ECM" SG_ 734 FD14_Segment_8_X2 0;
BA_ "GenSigTimeoutTime_EPS" SG_ 734 FD14_Segment_8_X2 0;
BA_ "GenSigTimeoutTime_ORC" SG_ 734 FD14_Segment_8_X2 0;
BA_ "GenSigTimeoutTime_BSM" SG_ 734 FD14_Segment_8_Y1 0;
BA_ "GenSigTimeoutTime_BSM2" SG_ 734 FD14_Segment_8_Y1 0;
BA_ "GenSigTimeoutTime_CVADAS" SG_ 734 FD14_Segment_8_Y1 0;
BA_ "GenSigTimeoutTime_ECM" SG_ 734 FD14_Segment_8_Y1 0;
BA_ "GenSigTimeoutTime_EPS" SG_ 734 FD14_Segment_8_Y1 0;
BA_ "GenSigTimeoutTime_ORC" SG_ 734 FD14_Segment_8_Y1 0;
BA_ "GenSigTimeoutTime_BSM" SG_ 734 FD14_Segment_8_Y2 0;
BA_ "GenSigTimeoutTime_BSM2" SG_ 734 FD14_Segment_8_Y2 0;
BA_ "GenSigTimeoutTime_CVADAS" SG_ 734 FD14_Segment_8_Y2 0;
BA_ "GenSigTimeoutTime_ECM" SG_ 734 FD14_Segment_8_Y2 0;
BA_ "GenSigTimeoutTime_EPS" SG_ 734 FD14_Segment_8_Y2 0;
BA_ "GenSigTimeoutTime_ORC" SG_ 734 FD14_Segment_8_Y2 0;
BA_ "GenSigStartValue" SG_ 204 FD14_Axle_Torque_DrvReqMod 32768;
BA_ "GenSigTimeoutTime_BSM" SG_ 204 FD14_Axle_Torque_DrvReqMod 0;
BA_ "GenSigTimeoutTime_BSM2" SG_ 204 FD14_Axle_Torque_DrvReqMod 0;
BA_ "GenSigTimeoutTime_CVADAS" SG_ 204 FD14_Axle_Torque_DrvReqMod 0;
BA_ "GenSigTimeoutTime_ECM" SG_ 204 FD14_Axle_Torque_DrvReqMod 0;
BA_ "GenSigTimeoutTime_EPS" SG_ 204 FD14_Axle_Torque_DrvReqMod 0;
BA_ "GenSigTimeoutTime_ORC" SG_ 204 FD14_Axle_Torque_DrvReqMod 0;
BA_ "GenSigStartValue" SG_ 204 FD14_Axle_TorqueStatic_D_TTC 32767;
BA_ "GenSigTimeoutTime_BSM" SG_ 204 FD14_Axle_TorqueStatic_D_TTC 0;
BA_ "GenSigTimeoutTime_BSM2" SG_ 204 FD14_Axle_TorqueStatic_D_TTC 0;
BA_ "GenSigTimeoutTime_CVADAS" SG_ 204 FD14_Axle_TorqueStatic_D_TTC 0;
BA_ "GenSigTimeoutTime_ECM" SG_ 204 FD14_Axle_TorqueStatic_D_TTC 0;
BA_ "GenSigTimeoutTime_EPS" SG_ 204 FD14_Axle_TorqueStatic_D_TTC 0;
BA_ "GenSigTimeoutTime_ORC" SG_ 204 FD14_Axle_TorqueStatic_D_TTC 0;
BA_ "GenSigTimeoutTime_BSM2" SG_ 204 FD14_CRC_AXLE_TORQUE_FD_1 0;
BA_ "GenSigTimeoutTime_CVADAS" SG_ 204 FD14_CRC_AXLE_TORQUE_FD_1 0;
BA_ "GenSigTimeoutTime_ECM" SG_ 204 FD14_CRC_AXLE_TORQUE_FD_1 0;
BA_ "GenSigTimeoutTime_EPS" SG_ 204 FD14_CRC_AXLE_TORQUE_FD_1 0;
BA_ "GenSigTimeoutTime_ORC" SG_ 204 FD14_CRC_AXLE_TORQUE_FD_1 0;
BA_ "GenSigTimeoutTime_BSM2" SG_ 204 FD14_MessageCounter_AXLE_TORQUE_ 0;
BA_ "GenSigTimeoutTime_CVADAS" SG_ 204 FD14_MessageCounter_AXLE_TORQUE_ 0;
BA_ "GenSigTimeoutTime_ECM" SG_ 204 FD14_MessageCounter_AXLE_TORQUE_ 0;
BA_ "GenSigTimeoutTime_EPS" SG_ 204 FD14_MessageCounter_AXLE_TORQUE_ 0;
BA_ "GenSigTimeoutTime_ORC" SG_ 204 FD14_MessageCounter_AXLE_TORQUE_ 0;
BA_ "SystemSignalLongSymbol" SG_ 204 FD14_MessageCounter_AXLE_TORQUE_ "FD14_MessageCounter_AXLE_TORQUE_FD_1";
BA_ "GenSigStartValue" SG_ 204 FD14_Total_AxleTorque_Max 32767;
BA_ "GenSigTimeoutTime_BSM" SG_ 204 FD14_Total_AxleTorque_Max 0;
BA_ "GenSigTimeoutTime_BSM2" SG_ 204 FD14_Total_AxleTorque_Max 0;
BA_ "GenSigTimeoutTime_CVADAS" SG_ 204 FD14_Total_AxleTorque_Max 0;
BA_ "GenSigTimeoutTime_ECM" SG_ 204 FD14_Total_AxleTorque_Max 0;
BA_ "GenSigTimeoutTime_EPS" SG_ 204 FD14_Total_AxleTorque_Max 0;
BA_ "GenSigTimeoutTime_ORC" SG_ 204 FD14_Total_AxleTorque_Max 0;
BA_ "GenSigStartValue" SG_ 204 FD14_Total_AxleTorque_Min 32767;
BA_ "GenSigTimeoutTime_BSM" SG_ 204 FD14_Total_AxleTorque_Min 0;
BA_ "GenSigTimeoutTime_BSM2" SG_ 204 FD14_Total_AxleTorque_Min 0;
BA_ "GenSigTimeoutTime_CVADAS" SG_ 204 FD14_Total_AxleTorque_Min 0;
BA_ "GenSigTimeoutTime_ECM" SG_ 204 FD14_Total_AxleTorque_Min 0;
BA_ "GenSigTimeoutTime_EPS" SG_ 204 FD14_Total_AxleTorque_Min 0;
BA_ "GenSigTimeoutTime_ORC" SG_ 204 FD14_Total_AxleTorque_Min 0;
BA_ "GenSigTimeoutTime_BSM" SG_ 513 FD14_ACCFSafe 0;
BA_ "GenSigTimeoutTime_CVADAS" SG_ 513 FD14_ACCFSafe 0;
BA_ "GenSigTimeoutTime_ECM" SG_ 513 FD14_ACCFSafe 0;
BA_ "GenSigTimeoutTime_EPS" SG_ 513 FD14_ACCFSafe 0;
BA_ "GenSigTimeoutTime_ORC" SG_ 513 FD14_ACCFSafe 0;
BA_ "GenSigTimeoutTime_BSM" SG_ 513 FD14_Brk_Jrk_Resp 0;
BA_ "GenSigTimeoutTime_BSM2" SG_ 513 FD14_Brk_Jrk_Resp 0;
BA_ "GenSigTimeoutTime_CVADAS" SG_ 513 FD14_Brk_Jrk_Resp 0;
BA_ "GenSigTimeoutTime_ECM" SG_ 513 FD14_Brk_Jrk_Resp 0;
BA_ "GenSigTimeoutTime_EPS" SG_ 513 FD14_Brk_Jrk_Resp 0;
BA_ "GenSigTimeoutTime_BSM" SG_ 513 FD14_Brk_Thermdl 0;
BA_ "GenSigTimeoutTime_BSM2" SG_ 513 FD14_Brk_Thermdl 0;
BA_ "GenSigTimeoutTime_CVADAS" SG_ 513 FD14_Brk_Thermdl 0;
BA_ "GenSigTimeoutTime_ECM" SG_ 513 FD14_Brk_Thermdl 0;
BA_ "GenSigTimeoutTime_EPS" SG_ 513 FD14_Brk_Thermdl 0;
BA_ "GenSigTimeoutTime_ORC" SG_ 513 FD14_Brk_Thermdl 0;
BA_ "GenSigStartValue" SG_ 513 FD14_BrkTrq 32767;
BA_ "GenSigTimeoutTime_BSM" SG_ 513 FD14_BrkTrq 0;
BA_ "GenSigTimeoutTime_BSM2" SG_ 513 FD14_BrkTrq 0;
BA_ "GenSigTimeoutTime_ECM" SG_ 513 FD14_BrkTrq 0;
BA_ "GenSigTimeoutTime_EPS" SG_ 513 FD14_BrkTrq 0;
BA_ "GenSigTimeoutTime_ORC" SG_ 513 FD14_BrkTrq 0;
BA_ "GenSigStartValue" SG_ 513 FD14_BrkTrq_Driver 32767;
BA_ "GenSigTimeoutTime_BSM" SG_ 513 FD14_BrkTrq_Driver 0;
BA_ "GenSigTimeoutTime_ECM" SG_ 513 FD14_BrkTrq_Driver 0;
BA_ "GenSigTimeoutTime_EPS" SG_ 513 FD14_BrkTrq_Driver 0;
BA_ "GenSigTimeoutTime_ORC" SG_ 513 FD14_BrkTrq_Driver 0;
BA_ "GenSigTimeoutTime_BSM" SG_ 513 FD14_CRC_BRAKE1 0;
BA_ "GenSigTimeoutTime_CVADAS" SG_ 513 FD14_CRC_BRAKE1 0;
BA_ "GenSigTimeoutTime_ECM" SG_ 513 FD14_CRC_BRAKE1 0;
BA_ "GenSigTimeoutTime_EPS" SG_ 513 FD14_CRC_BRAKE1 0;
BA_ "GenSigTimeoutTime_ORC" SG_ 513 FD14_CRC_BRAKE1 0;
BA_ "GenSigTimeoutTime_BSM" SG_ 513 FD14_DASEngReqPos 0;
BA_ "GenSigTimeoutTime_BSM2" SG_ 513 FD14_DASEngReqPos 0;
BA_ "GenSigTimeoutTime_CVADAS" SG_ 513 FD14_DASEngReqPos 0;
BA_ "GenSigTimeoutTime_ECM" SG_ 513 FD14_DASEngReqPos 0;
BA_ "GenSigTimeoutTime_EPS" SG_ 513 FD14_DASEngReqPos 0;
BA_ "GenSigTimeoutTime_ORC" SG_ 513 FD14_DASEngReqPos 0;
BA_ "GenSigStartValue" SG_ 513 FD14_EngSpdInterv 65535;
BA_ "GenSigTimeoutTime_BSM" SG_ 513 FD14_EngSpdInterv 0;
BA_ "GenSigTimeoutTime_BSM2" SG_ 513 FD14_EngSpdInterv 0;
BA_ "GenSigTimeoutTime_CADM" SG_ 513 FD14_EngSpdInterv 0;
BA_ "GenSigTimeoutTime_CVADAS" SG_ 513 FD14_EngSpdInterv 0;
BA_ "GenSigTimeoutTime_ECM" SG_ 513 FD14_EngSpdInterv 0;
BA_ "GenSigTimeoutTime_EPS" SG_ 513 FD14_EngSpdInterv 0;
BA_ "GenSigTimeoutTime_ORC" SG_ 513 FD14_EngSpdInterv 0;
BA_ "GenSigTimeoutTime_BSM" SG_ 513 FD14_EngSpdIntervReq 0;
BA_ "GenSigTimeoutTime_BSM2" SG_ 513 FD14_EngSpdIntervReq 0;
BA_ "GenSigTimeoutTime_CADM" SG_ 513 FD14_EngSpdIntervReq 0;
BA_ "GenSigTimeoutTime_CVADAS" SG_ 513 FD14_EngSpdIntervReq 0;
BA_ "GenSigTimeoutTime_ECM" SG_ 513 FD14_EngSpdIntervReq 0;
BA_ "GenSigTimeoutTime_EPS" SG_ 513 FD14_EngSpdIntervReq 0;
BA_ "GenSigTimeoutTime_ORC" SG_ 513 FD14_EngSpdIntervReq 0;
BA_ "GenSigTimeoutTime_BSM" SG_ 513 FD14_ExternalBrkRequestsDisabled 0;
BA_ "GenSigTimeoutTime_BSM2" SG_ 513 FD14_ExternalBrkRequestsDisabled 0;
BA_ "GenSigTimeoutTime_ECM" SG_ 513 FD14_ExternalBrkRequestsDisabled 0;
BA_ "GenSigTimeoutTime_EPS" SG_ 513 FD14_ExternalBrkRequestsDisabled 0;
BA_ "GenSigTimeoutTime_ORC" SG_ 513 FD14_ExternalBrkRequestsDisabled 0;
BA_ "GenSigTimeoutTime_BSM" SG_ 513 FD14_GrMax_Rq_BSM 0;
BA_ "GenSigTimeoutTime_BSM2" SG_ 513 FD14_GrMax_Rq_BSM 0;
BA_ "GenSigTimeoutTime_CVADAS" SG_ 513 FD14_GrMax_Rq_BSM 0;
BA_ "GenSigTimeoutTime_ECM" SG_ 513 FD14_GrMax_Rq_BSM 0;
BA_ "GenSigTimeoutTime_EPS" SG_ 513 FD14_GrMax_Rq_BSM 0;
BA_ "GenSigTimeoutTime_ORC" SG_ 513 FD14_GrMax_Rq_BSM 0;
BA_ "GenSigTimeoutTime_BSM" SG_ 513 FD14_GrMin_Rq_BSM 0;
BA_ "GenSigTimeoutTime_BSM2" SG_ 513 FD14_GrMin_Rq_BSM 0;
BA_ "GenSigTimeoutTime_CADM" SG_ 513 FD14_GrMin_Rq_BSM 0;
BA_ "GenSigTimeoutTime_CVADAS" SG_ 513 FD14_GrMin_Rq_BSM 0;
BA_ "GenSigTimeoutTime_ECM" SG_ 513 FD14_GrMin_Rq_BSM 0;
BA_ "GenSigTimeoutTime_EPS" SG_ 513 FD14_GrMin_Rq_BSM 0;
BA_ "GenSigTimeoutTime_ORC" SG_ 513 FD14_GrMin_Rq_BSM 0;
BA_ "GenSigTimeoutTime_BSM" SG_ 513 FD14_MessageCounter_BRAKE1 0;
BA_ "GenSigTimeoutTime_CVADAS" SG_ 513 FD14_MessageCounter_BRAKE1 0;
BA_ "GenSigTimeoutTime_ECM" SG_ 513 FD14_MessageCounter_BRAKE1 0;
BA_ "GenSigTimeoutTime_EPS" SG_ 513 FD14_MessageCounter_BRAKE1 0;
BA_ "GenSigTimeoutTime_ORC" SG_ 513 FD14_MessageCounter_BRAKE1 0;
BA_ "GenSigStartValue" SG_ 513 FD14_REF_VEH_SPEED 1023;
BA_ "GenSigTimeoutTime_BSM" SG_ 513 FD14_REF_VEH_SPEED 0;
BA_ "GenSigTimeoutTime_BSM2" SG_ 513 FD14_REF_VEH_SPEED 0;
BA_ "GenSigTimeoutTime_CADM" SG_ 513 FD14_REF_VEH_SPEED 0;
BA_ "GenSigTimeoutTime_ECM" SG_ 513 FD14_REF_VEH_SPEED 0;
BA_ "GenSigTimeoutTime_EPS" SG_ 513 FD14_REF_VEH_SPEED 0;
BA_ "GenSigTimeoutTime_ORC" SG_ 513 FD14_REF_VEH_SPEED 0;
BA_ "GenSigTimeoutTime_BSM" SG_ 513 FD14_SelectSpdSts 0;
BA_ "GenSigTimeoutTime_BSM2" SG_ 513 FD14_SelectSpdSts 0;
BA_ "GenSigTimeoutTime_CADM" SG_ 513 FD14_SelectSpdSts 0;
BA_ "GenSigTimeoutTime_CVADAS" SG_ 513 FD14_SelectSpdSts 0;
BA_ "GenSigTimeoutTime_ECM" SG_ 513 FD14_SelectSpdSts 0;
BA_ "GenSigTimeoutTime_EPS" SG_ 513 FD14_SelectSpdSts 0;
BA_ "GenSigTimeoutTime_ORC" SG_ 513 FD14_SelectSpdSts 0;
BA_ "GenSigTimeoutTime_BSM" SG_ 513 FD14_SelSpdLmp 0;
BA_ "GenSigTimeoutTime_BSM2" SG_ 513 FD14_SelSpdLmp 0;
BA_ "GenSigTimeoutTime_CADM" SG_ 513 FD14_SelSpdLmp 0;
BA_ "GenSigTimeoutTime_CVADAS" SG_ 513 FD14_SelSpdLmp 0;
BA_ "GenSigTimeoutTime_ECM" SG_ 513 FD14_SelSpdLmp 0;
BA_ "GenSigTimeoutTime_EPS" SG_ 513 FD14_SelSpdLmp 0;
BA_ "GenSigTimeoutTime_ORC" SG_ 513 FD14_SelSpdLmp 0;
BA_ "GenSigStartValue" SG_ 513 FD14_VehicleStandStillSts 1;
BA_ "GenSigTimeoutTime_BSM" SG_ 513 FD14_VehicleStandStillSts 0;
BA_ "GenSigTimeoutTime_ECM" SG_ 513 FD14_VehicleStandStillSts 0;
BA_ "GenSigTimeoutTime_ORC" SG_ 513 FD14_VehicleStandStillSts 0;
BA_ "GenSigTimeoutTime_BSM" SG_ 258 FD14_ABSActive 0;
BA_ "GenSigTimeoutTime_BSM2" SG_ 258 FD14_ABSActive 0;
BA_ "GenSigTimeoutTime_CVADAS" SG_ 258 FD14_ABSActive 0;
BA_ "GenSigTimeoutTime_EPS" SG_ 258 FD14_ABSActive 0;
BA_ "GenSigTimeoutTime_ORC" SG_ 258 FD14_ABSActive 0;
BA_ "GenSigStartValue" SG_ 258 FD14_BrakeBoostPressure 2047;
BA_ "GenSigTimeoutTime_BSM" SG_ 258 FD14_BrakeBoostPressure 0;
BA_ "GenSigTimeoutTime_BSM2" SG_ 258 FD14_BrakeBoostPressure 0;
BA_ "GenSigTimeoutTime_CADM" SG_ 258 FD14_BrakeBoostPressure 0;
BA_ "GenSigTimeoutTime_CVADAS" SG_ 258 FD14_BrakeBoostPressure 0;
BA_ "GenSigTimeoutTime_ECM" SG_ 258 FD14_BrakeBoostPressure 0;
BA_ "GenSigTimeoutTime_EPS" SG_ 258 FD14_BrakeBoostPressure 0;
BA_ "GenSigTimeoutTime_ORC" SG_ 258 FD14_BrakeBoostPressure 0;
BA_ "GenSigTimeoutTime_BSM" SG_ 258 FD14_BrakeBoostStat 0;
BA_ "GenSigTimeoutTime_BSM2" SG_ 258 FD14_BrakeBoostStat 0;
BA_ "GenSigTimeoutTime_CADM" SG_ 258 FD14_BrakeBoostStat 0;
BA_ "GenSigTimeoutTime_CVADAS" SG_ 258 FD14_BrakeBoostStat 0;
BA_ "GenSigTimeoutTime_ECM" SG_ 258 FD14_BrakeBoostStat 0;
BA_ "GenSigTimeoutTime_EPS" SG_ 258 FD14_BrakeBoostStat 0;
BA_ "GenSigTimeoutTime_ORC" SG_ 258 FD14_BrakeBoostStat 0;
BA_ "GenSigTimeoutTime_BSM" SG_ 258 FD14_BrakeInterventionSts 0;
BA_ "GenSigTimeoutTime_CVADAS" SG_ 258 FD14_BrakeInterventionSts 0;
BA_ "GenSigTimeoutTime_ECM" SG_ 258 FD14_BrakeInterventionSts 0;
BA_ "GenSigTimeoutTime_EPS" SG_ 258 FD14_BrakeInterventionSts 0;
BA_ "GenSigTimeoutTime_ORC" SG_ 258 FD14_BrakeInterventionSts 0;
BA_ "GenSigStartValue" SG_ 258 FD14_BrakePedalPressure 2047;
BA_ "GenSigTimeoutTime_BSM" SG_ 258 FD14_BrakePedalPressure 0;
BA_ "GenSigTimeoutTime_BSM2" SG_ 258 FD14_BrakePedalPressure 0;
BA_ "GenSigTimeoutTime_CADM" SG_ 258 FD14_BrakePedalPressure 0;
BA_ "GenSigTimeoutTime_CVADAS" SG_ 258 FD14_BrakePedalPressure 0;
BA_ "GenSigTimeoutTime_ECM" SG_ 258 FD14_BrakePedalPressure 0;
BA_ "GenSigTimeoutTime_EPS" SG_ 258 FD14_BrakePedalPressure 0;
BA_ "GenSigTimeoutTime_ORC" SG_ 258 FD14_BrakePedalPressure 0;
BA_ "GenSigTimeoutTime_BSM" SG_ 258 FD14_Brk_Stat 0;
BA_ "GenSigTimeoutTime_BSM2" SG_ 258 FD14_Brk_Stat 0;
BA_ "GenSigTimeoutTime_EPS" SG_ 258 FD14_Brk_Stat 0;
BA_ "GenSigTimeoutTime_ORC" SG_ 258 FD14_Brk_Stat 0;
BA_ "GenSigTimeoutTime_BSM" SG_ 258 FD14_BSM_ESASystemSts 0;
BA_ "GenSigTimeoutTime_BSM2" SG_ 258 FD14_BSM_ESASystemSts 0;
BA_ "GenSigTimeoutTime_CVADAS" SG_ 258 FD14_BSM_ESASystemSts 0;
BA_ "GenSigTimeoutTime_ECM" SG_ 258 FD14_BSM_ESASystemSts 0;
BA_ "GenSigTimeoutTime_ORC" SG_ 258 FD14_BSM_ESASystemSts 0;
BA_ "GenSigTimeoutTime_BSM" SG_ 258 FD14_CRC_BRAKE2 0;
BA_ "GenSigTimeoutTime_ORC" SG_ 258 FD14_CRC_BRAKE2 0;
BA_ "GenSigTimeoutTime_BSM" SG_ 258 FD14_ESCActive 0;
BA_ "GenSigTimeoutTime_BSM2" SG_ 258 FD14_ESCActive 0;
BA_ "GenSigTimeoutTime_CVADAS" SG_ 258 FD14_ESCActive 0;
BA_ "GenSigTimeoutTime_ECM" SG_ 258 FD14_ESCActive 0;
BA_ "GenSigTimeoutTime_EPS" SG_ 258 FD14_ESCActive 0;
BA_ "GenSigTimeoutTime_ORC" SG_ 258 FD14_ESCActive 0;
BA_ "GenSigStartValue" SG_ 258 FD14_ESP_Sys_Stat 1;
BA_ "GenSigTimeoutTime_BSM" SG_ 258 FD14_ESP_Sys_Stat 0;
BA_ "GenSigTimeoutTime_BSM2" SG_ 258 FD14_ESP_Sys_Stat 0;
BA_ "GenSigTimeoutTime_CADM" SG_ 258 FD14_ESP_Sys_Stat 0;
BA_ "GenSigTimeoutTime_CVADAS" SG_ 258 FD14_ESP_Sys_Stat 0;
BA_ "GenSigTimeoutTime_ECM" SG_ 258 FD14_ESP_Sys_Stat 0;
BA_ "GenSigTimeoutTime_EPS" SG_ 258 FD14_ESP_Sys_Stat 0;
BA_ "GenSigTimeoutTime_ORC" SG_ 258 FD14_ESP_Sys_Stat 0;
BA_ "GenSigTimeoutTime_BSM" SG_ 258 FD14_InternalError_BSM 0;
BA_ "GenSigTimeoutTime_BSM2" SG_ 258 FD14_InternalError_BSM 0;
BA_ "GenSigTimeoutTime_CVADAS" SG_ 258 FD14_InternalError_BSM 0;
BA_ "GenSigTimeoutTime_ECM" SG_ 258 FD14_InternalError_BSM 0;
BA_ "GenSigTimeoutTime_EPS" SG_ 258 FD14_InternalError_BSM 0;
BA_ "GenSigTimeoutTime_ORC" SG_ 258 FD14_InternalError_BSM 0;
BA_ "GenSigStartValue" SG_ 258 FD14_LatAcceleration_BSM 4095;
BA_ "GenSigTimeoutTime_BSM" SG_ 258 FD14_LatAcceleration_BSM 0;
BA_ "GenSigTimeoutTime_BSM2" SG_ 258 FD14_LatAcceleration_BSM 0;
BA_ "GenSigTimeoutTime_ECM" SG_ 258 FD14_LatAcceleration_BSM 0;
BA_ "GenSigTimeoutTime_ORC" SG_ 258 FD14_LatAcceleration_BSM 0;
BA_ "GenSigTimeoutTime_BSM" SG_ 258 FD14_LatAccelerationFailSts_BSM 0;
BA_ "GenSigTimeoutTime_BSM2" SG_ 258 FD14_LatAccelerationFailSts_BSM 0;
BA_ "GenSigTimeoutTime_ECM" SG_ 258 FD14_LatAccelerationFailSts_BSM 0;
BA_ "GenSigTimeoutTime_EPS" SG_ 258 FD14_LatAccelerationFailSts_BSM 0;
BA_ "GenSigTimeoutTime_ORC" SG_ 258 FD14_LatAccelerationFailSts_BSM 0;
BA_ "GenSigStartValue" SG_ 258 FD14_LongAcceleration_BSM 4095;
BA_ "GenSigTimeoutTime_BSM" SG_ 258 FD14_LongAcceleration_BSM 0;
BA_ "GenSigTimeoutTime_BSM2" SG_ 258 FD14_LongAcceleration_BSM 0;
BA_ "GenSigTimeoutTime_ECM" SG_ 258 FD14_LongAcceleration_BSM 0;
BA_ "GenSigTimeoutTime_ORC" SG_ 258 FD14_LongAcceleration_BSM 0;
BA_ "GenSigTimeoutTime_BSM" SG_ 258 FD14_LongAccelerationFailSts_BSM 0;
BA_ "GenSigTimeoutTime_BSM2" SG_ 258 FD14_LongAccelerationFailSts_BSM 0;
BA_ "GenSigTimeoutTime_ECM" SG_ 258 FD14_LongAccelerationFailSts_BSM 0;
BA_ "GenSigTimeoutTime_EPS" SG_ 258 FD14_LongAccelerationFailSts_BSM 0;
BA_ "GenSigTimeoutTime_ORC" SG_ 258 FD14_LongAccelerationFailSts_BSM 0;
BA_ "GenSigTimeoutTime_BSM" SG_ 258 FD14_MessageCounter_BRAKE2 0;
BA_ "GenSigTimeoutTime_ORC" SG_ 258 FD14_MessageCounter_BRAKE2 0;
BA_ "GenSigTimeoutTime_BSM" SG_ 258 FD14_ParkingGearShiftReq_BSM 0;
BA_ "GenSigTimeoutTime_BSM2" SG_ 258 FD14_ParkingGearShiftReq_BSM 0;
BA_ "GenSigTimeoutTime_CADM" SG_ 258 FD14_ParkingGearShiftReq_BSM 0;
BA_ "GenSigTimeoutTime_ECM" SG_ 258 FD14_ParkingGearShiftReq_BSM 0;
BA_ "GenSigTimeoutTime_EPS" SG_ 258 FD14_ParkingGearShiftReq_BSM 0;
BA_ "GenSigTimeoutTime_ORC" SG_ 258 FD14_ParkingGearShiftReq_BSM 0;
BA_ "GenSigTimeoutTime_BSM" SG_ 258 FD14_ParkingInterventionSts 0;
BA_ "GenSigTimeoutTime_BSM2" SG_ 258 FD14_ParkingInterventionSts 0;
BA_ "GenSigTimeoutTime_CADM" SG_ 258 FD14_ParkingInterventionSts 0;
BA_ "GenSigTimeoutTime_ECM" SG_ 258 FD14_ParkingInterventionSts 0;
BA_ "GenSigTimeoutTime_EPS" SG_ 258 FD14_ParkingInterventionSts 0;
BA_ "GenSigTimeoutTime_ORC" SG_ 258 FD14_ParkingInterventionSts 0;
BA_ "GenSigTimeoutTime_BSM" SG_ 258 FD14_PrefillActive 0;
BA_ "GenSigTimeoutTime_BSM2" SG_ 258 FD14_PrefillActive 0;
BA_ "GenSigTimeoutTime_CVADAS" SG_ 258 FD14_PrefillActive 0;
BA_ "GenSigTimeoutTime_ECM" SG_ 258 FD14_PrefillActive 0;
BA_ "GenSigTimeoutTime_EPS" SG_ 258 FD14_PrefillActive 0;
BA_ "GenSigTimeoutTime_ORC" SG_ 258 FD14_PrefillActive 0;
BA_ "GenSigTimeoutTime_BSM" SG_ 258 FD14_Slope 0;
BA_ "GenSigTimeoutTime_BSM2" SG_ 258 FD14_Slope 0;
BA_ "GenSigTimeoutTime_CADM" SG_ 258 FD14_Slope 0;
BA_ "GenSigTimeoutTime_ECM" SG_ 258 FD14_Slope 0;
BA_ "GenSigTimeoutTime_EPS" SG_ 258 FD14_Slope 0;
BA_ "GenSigTimeoutTime_ORC" SG_ 258 FD14_Slope 0;
BA_ "GenSigTimeoutTime_BSM" SG_ 258 FD14_VehicleSpeedVSOSig 0;
BA_ "GenSigTimeoutTime_ECM" SG_ 258 FD14_VehicleSpeedVSOSig 0;
BA_ "GenSigTimeoutTime_ORC" SG_ 258 FD14_VehicleSpeedVSOSig 0;
BA_ "GenSigStartValue" SG_ 258 FD14_WheelRPM_FL 65535;
BA_ "GenSigTimeoutTime_BSM" SG_ 258 FD14_WheelRPM_FL 0;
BA_ "GenSigTimeoutTime_BSM2" SG_ 258 FD14_WheelRPM_FL 0;
BA_ "GenSigTimeoutTime_CADM" SG_ 258 FD14_WheelRPM_FL 0;
BA_ "GenSigTimeoutTime_CVADAS" SG_ 258 FD14_WheelRPM_FL 0;
BA_ "GenSigTimeoutTime_ECM" SG_ 258 FD14_WheelRPM_FL 0;
BA_ "GenSigTimeoutTime_ORC" SG_ 258 FD14_WheelRPM_FL 0;
BA_ "GenSigStartValue" SG_ 258 FD14_WheelRPM_FR 65535;
BA_ "GenSigTimeoutTime_BSM" SG_ 258 FD14_WheelRPM_FR 0;
BA_ "GenSigTimeoutTime_BSM2" SG_ 258 FD14_WheelRPM_FR 0;
BA_ "GenSigTimeoutTime_CADM" SG_ 258 FD14_WheelRPM_FR 0;
BA_ "GenSigTimeoutTime_CVADAS" SG_ 258 FD14_WheelRPM_FR 0;
BA_ "GenSigTimeoutTime_ECM" SG_ 258 FD14_WheelRPM_FR 0;
BA_ "GenSigTimeoutTime_ORC" SG_ 258 FD14_WheelRPM_FR 0;
BA_ "GenSigStartValue" SG_ 258 FD14_YawRate_BSM 4095;
BA_ "GenSigTimeoutTime_BSM" SG_ 258 FD14_YawRate_BSM 0;
BA_ "GenSigTimeoutTime_BSM2" SG_ 258 FD14_YawRate_BSM 0;
BA_ "GenSigTimeoutTime_ECM" SG_ 258 FD14_YawRate_BSM 0;
BA_ "GenSigTimeoutTime_ORC" SG_ 258 FD14_YawRate_BSM 0;
BA_ "GenSigTimeoutTime_BSM" SG_ 258 FD14_YawRateFailSts_BSM 0;
BA_ "GenSigTimeoutTime_BSM2" SG_ 258 FD14_YawRateFailSts_BSM 0;
BA_ "GenSigTimeoutTime_ECM" SG_ 258 FD14_YawRateFailSts_BSM 0;
BA_ "GenSigTimeoutTime_ORC" SG_ 258 FD14_YawRateFailSts_BSM 0;
BA_ "GenSigTimeoutTime_BSM" SG_ 259 FD14_CRC__BRAKE3 0;
BA_ "GenSigTimeoutTime_ECM" SG_ 259 FD14_CRC__BRAKE3 0;
BA_ "GenSigTimeoutTime_ORC" SG_ 259 FD14_CRC__BRAKE3 0;
BA_ "GenSigStartValue" SG_ 259 FD14_LatAccelerationOffset_BSM 255;
BA_ "GenSigTimeoutTime_BSM" SG_ 259 FD14_LatAccelerationOffset_BSM 0;
BA_ "GenSigTimeoutTime_CADM" SG_ 259 FD14_LatAccelerationOffset_BSM 0;
BA_ "GenSigTimeoutTime_ECM" SG_ 259 FD14_LatAccelerationOffset_BSM 0;
BA_ "GenSigTimeoutTime_EPS" SG_ 259 FD14_LatAccelerationOffset_BSM 0;
BA_ "GenSigTimeoutTime_ORC" SG_ 259 FD14_LatAccelerationOffset_BSM 0;
BA_ "GenSigTimeoutTime_BSM" SG_ 259 FD14_LHF_FastPulseCounter 0;
BA_ "GenSigTimeoutTime_ECM" SG_ 259 FD14_LHF_FastPulseCounter 0;
BA_ "GenSigTimeoutTime_ORC" SG_ 259 FD14_LHF_FastPulseCounter 0;
BA_ "GenSigTimeoutTime_BSM" SG_ 259 FD14_LHF_Spin 0;
BA_ "GenSigTimeoutTime_ECM" SG_ 259 FD14_LHF_Spin 0;
BA_ "GenSigTimeoutTime_ORC" SG_ 259 FD14_LHF_Spin 0;
BA_ "GenSigTimeoutTime_BSM" SG_ 259 FD14_LHF_WheelSensorFailSts 0;
BA_ "GenSigTimeoutTime_ECM" SG_ 259 FD14_LHF_WheelSensorFailSts 0;
BA_ "GenSigTimeoutTime_ORC" SG_ 259 FD14_LHF_WheelSensorFailSts 0;
BA_ "GenSigTimeoutTime_BSM" SG_ 259 FD14_LHFWheelSpeed 0;
BA_ "GenSigTimeoutTime_ECM" SG_ 259 FD14_LHFWheelSpeed 0;
BA_ "GenSigTimeoutTime_ORC" SG_ 259 FD14_LHFWheelSpeed 0;
BA_ "GenSigTimeoutTime_BSM" SG_ 259 FD14_LHR_FastPulseCounter 0;
BA_ "GenSigTimeoutTime_ECM" SG_ 259 FD14_LHR_FastPulseCounter 0;
BA_ "GenSigTimeoutTime_ORC" SG_ 259 FD14_LHR_FastPulseCounter 0;
BA_ "GenSigTimeoutTime_BSM" SG_ 259 FD14_LHR_Spin 0;
BA_ "GenSigTimeoutTime_ECM" SG_ 259 FD14_LHR_Spin 0;
BA_ "GenSigTimeoutTime_EPS" SG_ 259 FD14_LHR_Spin 0;
BA_ "GenSigTimeoutTime_ORC" SG_ 259 FD14_LHR_Spin 0;
BA_ "GenSigTimeoutTime_BSM" SG_ 259 FD14_LHR_WheelSensorFailSts 0;
BA_ "GenSigTimeoutTime_ECM" SG_ 259 FD14_LHR_WheelSensorFailSts 0;
BA_ "GenSigTimeoutTime_ORC" SG_ 259 FD14_LHR_WheelSensorFailSts 0;
BA_ "GenSigTimeoutTime_BSM" SG_ 259 FD14_LHRWheelSpeed 0;
BA_ "GenSigTimeoutTime_ECM" SG_ 259 FD14_LHRWheelSpeed 0;
BA_ "GenSigTimeoutTime_ORC" SG_ 259 FD14_LHRWheelSpeed 0;
BA_ "GenSigStartValue" SG_ 259 FD14_LongAccelerationOffset_BSM 255;
BA_ "GenSigTimeoutTime_BSM" SG_ 259 FD14_LongAccelerationOffset_BSM 0;
BA_ "GenSigTimeoutTime_CADM" SG_ 259 FD14_LongAccelerationOffset_BSM 0;
BA_ "GenSigTimeoutTime_ECM" SG_ 259 FD14_LongAccelerationOffset_BSM 0;
BA_ "GenSigTimeoutTime_EPS" SG_ 259 FD14_LongAccelerationOffset_BSM 0;
BA_ "GenSigTimeoutTime_ORC" SG_ 259 FD14_LongAccelerationOffset_BSM 0;
BA_ "GenSigStartValue" SG_ 259 FD14_LwsAngleOffset_BSM 1023;
BA_ "GenSigTimeoutTime_BSM" SG_ 259 FD14_LwsAngleOffset_BSM 0;
BA_ "GenSigTimeoutTime_CVADAS" SG_ 259 FD14_LwsAngleOffset_BSM 0;
BA_ "GenSigTimeoutTime_ECM" SG_ 259 FD14_LwsAngleOffset_BSM 0;
BA_ "GenSigTimeoutTime_EPS" SG_ 259 FD14_LwsAngleOffset_BSM 0;
BA_ "GenSigTimeoutTime_ORC" SG_ 259 FD14_LwsAngleOffset_BSM 0;
BA_ "GenSigTimeoutTime_BSM" SG_ 259 FD14_MessageCounter_BRAKE3 0;
BA_ "GenSigTimeoutTime_ECM" SG_ 259 FD14_MessageCounter_BRAKE3 0;
BA_ "GenSigTimeoutTime_ORC" SG_ 259 FD14_MessageCounter_BRAKE3 0;
BA_ "GenSigTimeoutTime_BSM" SG_ 259 FD14_RHF_FastPulseCounter 0;
BA_ "GenSigTimeoutTime_ECM" SG_ 259 FD14_RHF_FastPulseCounter 0;
BA_ "GenSigTimeoutTime_ORC" SG_ 259 FD14_RHF_FastPulseCounter 0;
BA_ "GenSigTimeoutTime_BSM" SG_ 259 FD14_RHF_Spin 0;
BA_ "GenSigTimeoutTime_ECM" SG_ 259 FD14_RHF_Spin 0;
BA_ "GenSigTimeoutTime_ORC" SG_ 259 FD14_RHF_Spin 0;
BA_ "GenSigTimeoutTime_BSM" SG_ 259 FD14_RHF_WheelSensorFailSts 0;
BA_ "GenSigTimeoutTime_ECM" SG_ 259 FD14_RHF_WheelSensorFailSts 0;
BA_ "GenSigTimeoutTime_ORC" SG_ 259 FD14_RHF_WheelSensorFailSts 0;
BA_ "GenSigTimeoutTime_BSM" SG_ 259 FD14_RHFWheelSpeed 0;
BA_ "GenSigTimeoutTime_ECM" SG_ 259 FD14_RHFWheelSpeed 0;
BA_ "GenSigTimeoutTime_ORC" SG_ 259 FD14_RHFWheelSpeed 0;
BA_ "GenSigTimeoutTime_BSM" SG_ 259 FD14_RHR_FastPulseCounter 0;
BA_ "GenSigTimeoutTime_ECM" SG_ 259 FD14_RHR_FastPulseCounter 0;
BA_ "GenSigTimeoutTime_ORC" SG_ 259 FD14_RHR_FastPulseCounter 0;
BA_ "GenSigTimeoutTime_BSM" SG_ 259 FD14_RHR_Spin 0;
BA_ "GenSigTimeoutTime_ECM" SG_ 259 FD14_RHR_Spin 0;
BA_ "GenSigTimeoutTime_EPS" SG_ 259 FD14_RHR_Spin 0;
BA_ "GenSigTimeoutTime_ORC" SG_ 259 FD14_RHR_Spin 0;
BA_ "GenSigTimeoutTime_BSM" SG_ 259 FD14_RHR_WheelSensorFailSts 0;
BA_ "GenSigTimeoutTime_ECM" SG_ 259 FD14_RHR_WheelSensorFailSts 0;
BA_ "GenSigTimeoutTime_ORC" SG_ 259 FD14_RHR_WheelSensorFailSts 0;
BA_ "GenSigTimeoutTime_BSM" SG_ 259 FD14_RHRWheelSpeed 0;
BA_ "GenSigTimeoutTime_ECM" SG_ 259 FD14_RHRWheelSpeed 0;
BA_ "GenSigTimeoutTime_ORC" SG_ 259 FD14_RHRWheelSpeed 0;
BA_ "GenSigStartValue" SG_ 259 FD14_YawRateOffset_BSM 255;
BA_ "GenSigTimeoutTime_BSM" SG_ 259 FD14_YawRateOffset_BSM 0;
BA_ "GenSigTimeoutTime_CADM" SG_ 259 FD14_YawRateOffset_BSM 0;
BA_ "GenSigTimeoutTime_CVADAS" SG_ 259 FD14_YawRateOffset_BSM 0;
BA_ "GenSigTimeoutTime_ECM" SG_ 259 FD14_YawRateOffset_BSM 0;
BA_ "GenSigTimeoutTime_EPS" SG_ 259 FD14_YawRateOffset_BSM 0;
BA_ "GenSigTimeoutTime_ORC" SG_ 259 FD14_YawRateOffset_BSM 0;
BA_ "GenSigSendType" SG_ 609 FD14_ASRActive 3;
BA_ "GenSigTimeoutTime_BSM" SG_ 609 FD14_ASRActive 0;
BA_ "GenSigTimeoutTime_BSM2" SG_ 609 FD14_ASRActive 0;
BA_ "GenSigTimeoutTime_CADM" SG_ 609 FD14_ASRActive 0;
BA_ "GenSigTimeoutTime_CVADAS" SG_ 609 FD14_ASRActive 0;
BA_ "GenSigTimeoutTime_ECM" SG_ 609 FD14_ASRActive 0;
BA_ "GenSigTimeoutTime_EPS" SG_ 609 FD14_ASRActive 0;
BA_ "GenSigTimeoutTime_ORC" SG_ 609 FD14_ASRActive 0;
BA_ "GenSigTimeoutTime_BSM" SG_ 609 FD14_BSM_LnchAbrtSts 0;
BA_ "GenSigTimeoutTime_BSM2" SG_ 609 FD14_BSM_LnchAbrtSts 0;
BA_ "GenSigTimeoutTime_CADM" SG_ 609 FD14_BSM_LnchAbrtSts 0;
BA_ "GenSigTimeoutTime_CVADAS" SG_ 609 FD14_BSM_LnchAbrtSts 0;
BA_ "GenSigTimeoutTime_ECM" SG_ 609 FD14_BSM_LnchAbrtSts 0;
BA_ "GenSigTimeoutTime_EPS" SG_ 609 FD14_BSM_LnchAbrtSts 0;
BA_ "GenSigTimeoutTime_ORC" SG_ 609 FD14_BSM_LnchAbrtSts 0;
BA_ "GenSigTimeoutTime_BSM" SG_ 609 FD14_BSM_LnchCtrl_SftBtn_SelectS 0;
BA_ "GenSigTimeoutTime_BSM2" SG_ 609 FD14_BSM_LnchCtrl_SftBtn_SelectS 0;
BA_ "GenSigTimeoutTime_CADM" SG_ 609 FD14_BSM_LnchCtrl_SftBtn_SelectS 0;
BA_ "GenSigTimeoutTime_CVADAS" SG_ 609 FD14_BSM_LnchCtrl_SftBtn_SelectS 0;
BA_ "GenSigTimeoutTime_ECM" SG_ 609 FD14_BSM_LnchCtrl_SftBtn_SelectS 0;
BA_ "GenSigTimeoutTime_EPS" SG_ 609 FD14_BSM_LnchCtrl_SftBtn_SelectS 0;
BA_ "GenSigTimeoutTime_ORC" SG_ 609 FD14_BSM_LnchCtrl_SftBtn_SelectS 0;
BA_ "SystemSignalLongSymbol" SG_ 609 FD14_BSM_LnchCtrl_SftBtn_SelectS "FD14_BSM_LnchCtrl_SftBtn_SelectSts";
BA_ "GenSigTimeoutTime_BSM" SG_ 609 FD14_BSM_LnchMode 0;
BA_ "GenSigTimeoutTime_BSM2" SG_ 609 FD14_BSM_LnchMode 0;
BA_ "GenSigTimeoutTime_CADM" SG_ 609 FD14_BSM_LnchMode 0;
BA_ "GenSigTimeoutTime_CVADAS" SG_ 609 FD14_BSM_LnchMode 0;
BA_ "GenSigTimeoutTime_ECM" SG_ 609 FD14_BSM_LnchMode 0;
BA_ "GenSigTimeoutTime_EPS" SG_ 609 FD14_BSM_LnchMode 0;
BA_ "GenSigTimeoutTime_ORC" SG_ 609 FD14_BSM_LnchMode 0;
BA_ "GenSigTimeoutTime_BSM" SG_ 609 FD14_CRC_BRAKE4 0;
BA_ "GenSigTimeoutTime_BSM2" SG_ 609 FD14_CRC_BRAKE4 0;
BA_ "GenSigTimeoutTime_CVADAS" SG_ 609 FD14_CRC_BRAKE4 0;
BA_ "GenSigTimeoutTime_ECM" SG_ 609 FD14_CRC_BRAKE4 0;
BA_ "GenSigTimeoutTime_EPS" SG_ 609 FD14_CRC_BRAKE4 0;
BA_ "GenSigTimeoutTime_ORC" SG_ 609 FD14_CRC_BRAKE4 0;
BA_ "GenSigSendType" SG_ 609 FD14_EPBSts 3;
BA_ "GenSigTimeoutTime_BSM" SG_ 609 FD14_EPBSts 0;
BA_ "GenSigTimeoutTime_BSM2" SG_ 609 FD14_EPBSts 0;
BA_ "GenSigTimeoutTime_ECM" SG_ 609 FD14_EPBSts 0;
BA_ "GenSigTimeoutTime_EPS" SG_ 609 FD14_EPBSts 0;
BA_ "GenSigTimeoutTime_ORC" SG_ 609 FD14_EPBSts 0;
BA_ "GenSigTimeoutTime_BSM" SG_ 609 FD14_ESC_OFF_Hrd_Sft_Button_sts 0;
BA_ "GenSigTimeoutTime_BSM2" SG_ 609 FD14_ESC_OFF_Hrd_Sft_Button_sts 0;
BA_ "GenSigTimeoutTime_CADM" SG_ 609 FD14_ESC_OFF_Hrd_Sft_Button_sts 0;
BA_ "GenSigTimeoutTime_CVADAS" SG_ 609 FD14_ESC_OFF_Hrd_Sft_Button_sts 0;
BA_ "GenSigTimeoutTime_ECM" SG_ 609 FD14_ESC_OFF_Hrd_Sft_Button_sts 0;
BA_ "GenSigTimeoutTime_EPS" SG_ 609 FD14_ESC_OFF_Hrd_Sft_Button_sts 0;
BA_ "GenSigTimeoutTime_ORC" SG_ 609 FD14_ESC_OFF_Hrd_Sft_Button_sts 0;
BA_ "GenSigTimeoutTime_BSM" SG_ 609 FD14_LaunchRPMsetting_BSM 0;
BA_ "GenSigTimeoutTime_BSM2" SG_ 609 FD14_LaunchRPMsetting_BSM 0;
BA_ "GenSigTimeoutTime_CADM" SG_ 609 FD14_LaunchRPMsetting_BSM 0;
BA_ "GenSigTimeoutTime_CVADAS" SG_ 609 FD14_LaunchRPMsetting_BSM 0;
BA_ "GenSigTimeoutTime_ECM" SG_ 609 FD14_LaunchRPMsetting_BSM 0;
BA_ "GenSigTimeoutTime_EPS" SG_ 609 FD14_LaunchRPMsetting_BSM 0;
BA_ "GenSigTimeoutTime_ORC" SG_ 609 FD14_LaunchRPMsetting_BSM 0;
BA_ "GenSigTimeoutTime_BSM" SG_ 609 FD14_MessageCounter_BRAKE4 0;
BA_ "GenSigTimeoutTime_BSM2" SG_ 609 FD14_MessageCounter_BRAKE4 0;
BA_ "GenSigTimeoutTime_CVADAS" SG_ 609 FD14_MessageCounter_BRAKE4 0;
BA_ "GenSigTimeoutTime_ECM" SG_ 609 FD14_MessageCounter_BRAKE4 0;
BA_ "GenSigTimeoutTime_EPS" SG_ 609 FD14_MessageCounter_BRAKE4 0;
BA_ "GenSigTimeoutTime_ORC" SG_ 609 FD14_MessageCounter_BRAKE4 0;
BA_ "GenSigSendType" SG_ 609 FD14_MSRActive 3;
BA_ "GenSigTimeoutTime_BSM" SG_ 609 FD14_MSRActive 0;
BA_ "GenSigTimeoutTime_BSM2" SG_ 609 FD14_MSRActive 0;
BA_ "GenSigTimeoutTime_CADM" SG_ 609 FD14_MSRActive 0;
BA_ "GenSigTimeoutTime_CVADAS" SG_ 609 FD14_MSRActive 0;
BA_ "GenSigTimeoutTime_ECM" SG_ 609 FD14_MSRActive 0;
BA_ "GenSigTimeoutTime_EPS" SG_ 609 FD14_MSRActive 0;
BA_ "GenSigTimeoutTime_ORC" SG_ 609 FD14_MSRActive 0;
BA_ "GenSigTimeoutTime_BSM" SG_ 609 FD14_TravelDistance 0;
BA_ "GenSigTimeoutTime_BSM2" SG_ 609 FD14_TravelDistance 0;
BA_ "GenSigTimeoutTime_CADM" SG_ 609 FD14_TravelDistance 0;
BA_ "GenSigTimeoutTime_CVADAS" SG_ 609 FD14_TravelDistance 0;
BA_ "GenSigTimeoutTime_ECM" SG_ 609 FD14_TravelDistance 0;
BA_ "GenSigTimeoutTime_EPS" SG_ 609 FD14_TravelDistance 0;
BA_ "GenSigTimeoutTime_ORC" SG_ 609 FD14_TravelDistance 0;
VAL_ 2654552167 FD14_TrailerAngleSign 2 "None" 1 "Anticlockwise" 0 "Clockwise" ;
VAL_ 1456 FD14_ACC_Blind 0 "Fail_Not_Present" 1 "Fail_Present" ;
VAL_ 1456 FD14_ACC_DispPopupSts 0 "No_Code" 1 "ACC_Unavailable" 2 "ACC_Unavailable_4WD_Low" 3 "ACC_Unavailable_ESC_Off" 4 "ACC_Unavailable_ESC_Event" 5 "ACC_Unavailable_Brakes_Cooling" 6 "ACC_Unavailable_Below_Min_Speed" 7 "ACC_Unavailable_Above_Max_Speed" 8 "ACC_Unavailable_EPB_Active" 9 "ACC_Unavailable_Shift_D" 10 "ACC_Unavailable_Door_Open" 11 "ACC_Unavailable_Seatbelt_Unbuckled" 12 "ACC_Unavailable_Road_to_Steep" 13 "ACC_Unavailable_Wrong_Gear" 14 "ACC_Unavailable_Low_RPM" 15 "ACC_Unavailable_High_RPM" 16 "ACC_Unavailable_Clutch_Engaged" 17 "ACC_Cancel" 18 "ACC_AEB_Cancel_ESC_Off" 19 "ACC_Cancel_ESC_Off" 20 "ACC_Cancel_ESC_Event" 21 "ACC_Cancel_Brakes_Cooling" 22 "ACC_Cancel_Below_Min_Speed" 23 "ACC_Cancel_Above_Max_Speed" 24 "ACC_Cancel_EPB_Active" 25 "ACC_Cancel_Shift_D" 26 "ACC_Cancel_Door_Open" 27 "ACC_Cancel_Seatbelt_Unbuckled" 28 "ACC_Cancel_Road_to_Steep" 29 "ACC_Cancel_Wrong_gear" 30 "ACC_Cancel_Low_RPM" 31 "ACC_Cancel_High_RPM" 32 "ACC_Stop_Vehicle_Object_Detected" 33 "ACC_Warning_Clutch_Engaged" 34 "ACC_Warning_Neutral_Engaged" 35 "ACC_Off_ESC_Fault" 36 "ACC_Proximity_Warning" 37 "NCC_Unavailable" 38 "NCC_Unavailable_4WD_Low" 39 "NCC_Unavailable_ESC_Off" 40 "NCC_Unavailable_ESC_Event" 41 "NCC_Unavailable_Brakes_Cooling" 42 "NCC_Unavailable_Below_Min_Speed" 43 "NCC_Unavailable_Above_Max_Speed" 44 "NCC_Unavailable_EPB_Active" 45 "NCC_Unavailable_Shift_D" 46 "NCC_Unavailable_Wrong_Gear" 47 "NCC_Unavailable_Low_RPM" 48 "NCC_Unavailable_High_RPM" 49 "NCC_Unavailable_Clutch_Engaged" 50 "NCC_Cancel" 51 "NCC_AEB_Cancel_ESC_Off" 52 "NCC_Cancel_ESC_Off" 53 "NCC_Cancel_ESC_Event" 54 "NCC_Cancel_Brakes_Cooling" 55 "NCC_Cancel_Below_Min_Speed" 56 "NCC_Cancel_Above_Max_Speed" 57 "NCC_Cancel_EPB_Active" 58 "NCC_Cancel_Shift_D" 59 "NCC_Cancel_Wrong_Gear" 60 "NCC_Cancel_Low_RPM" 61 "NCC_Cancel_High_RPM" 62 "NCC_Warning_Clutch_Engaged" 63 "NCC_Warning_Neutral_Engaged" 64 "ACC_User_Enabled" 68 "ACC_Set" 76 "ACC_Override" 77 "ACC_User_Disabled" 78 "NCC_User_Enabled" 79 "NCC_Set" 80 "NCC_User_Disbaled" 81 "NCC_Override" 82 "Front_Radar_Sensor_Plant_Mode" 83 "ACC_AEB_LKA_Cam_Blind" 84 "ACC_AEB_Cam_Blind" 85 "ACC_LKA_Cam_Blind" 86 "ACC_Cam_Blind" 87 "ACC_AEB_LKA_LIMITED_Fail" 88 "ACC_AEB_LIMITED_Fail" 89 "ACC_LKA_LIMITED_Fail" 90 "ACC_LIMITED_Fail" 91 "ACC_AEB_Radar_Blind" 92 "ACC_Radar_Blind" 93 "ACC_AEB_LKA_Fail" 94 "ACC_AEB_Fail" 95 "ACC_LKA_Fail" 96 "ACC_Fail" 97 "NCC_AEB_LKA_Fail" 98 "NCC_AEB_Fail" 99 "NCC_LKA_Fail" 100 "NCC_Fail" 101 "Alignment_Mode" 102 "Misaligned_Radar" 103 "ACC_Unavail_Corsa" 104 "NCC_Unavail_Corsa" 105 "ACC_Unavailable_Off_Road" 106 "NCC_Unavailable_Off_Road" 107 "ACC_Resume_Reminder" 108 "ACC_Cancel_Off_Road" 109 "ACC_Unavail_HDC" 110 "NCC_Unavail_HDC" 111 "ACC_AEB_Cancel_Off_Road" ;
VAL_ 1456 FD14_ACC_FailSts 0 "Fail_Not_Present" 1 "Fail_Present" ;
VAL_ 1456 FD14_ACC_Limit_Fail 0 "Fail_Not_Present" 1 "Fail_Present" ;
VAL_ 1456 FD14_ACC_Limited 0 "Fail_Not_Present" 1 "Fail_Present" ;
VAL_ 1456 FD14_ACC_Set_Speed_Strike 0 "Not_Present" 1 "Present" ;
VAL_ 1456 FD14_AEB_Blind 0 "Fail_Not_Present" 1 "Fail_Present" ;
VAL_ 1456 FD14_AEB_DispPopupSts 0 "No_Code" 1 "Pre_Intervention_Warning" 4 "Braking_Complete" 5 "AEB_Unavailble_ESC_Off" 6 "AEB_Unavailble_4WD_Low" 7 "Active_Braking_Enabled" 8 "Active_Braking_Disabled" 9 "AEB_User_Disabled" 10 "AEB_Radar_Blind" 11 "Pre_Intervention_Warning_VRU_L" 12 "AEB_Fail" 13 "Pre_Intervention_Warning_VRU_R" 14 "AEB_Cam_Blind" 15 "Not_used3" 16 "AEB_LIMITED_Fail" 17 "PEB_Off" 18 "PEB_On" 19 "PEB_Radar_Blind" 20 "PEB_Fail" 21 "PEB_Cam_Blind" 22 "FCW_Limited_PEB_Off_Camera_Blinded" 23 "FCW_Limited_PEB_Off_Camera_Fail" 24 "Pre_Intervention_Warning_ICA_L" 25 "Pre_Intervention_Warning_ICA_R" 26 "AEB_Limit_Corner_Blind" 27 "AEB_Unavail_Corsa" 28 "AEB_Unavail_Off_Road" 29 "AEB_Cancel_ESC_Off" 30 "AEB_Cancel_Off_Road" 31 "AEB_Unavail_HDC" 32 "AEB_Initializing_Phase_Ongoing" ;
VAL_ 1456 FD14_AEB_FailSts 0 "Fail_Not_Present" 1 "Fail_Present" ;
VAL_ 1456 FD14_AEB_Limit_Fail 0 "Fail_Not_Present" 1 "Fail_Present" ;
VAL_ 1456 FD14_AEB_Limited 0 "Fail_Not_Present" 1 "Fail_Present" ;
VAL_ 1456 FD14_BlindSpotLeftWarn 0 "No_Req" 1 "Solid" 2 "Flashing" ;
VAL_ 1456 FD14_BlindSpotRightWarn 0 "No_Req" 1 "Solid" 2 "Flashing" ;
VAL_ 1456 FD14_BSS_Blind_RQSts 0 "No_Sensor_Blocked_Request" 1 "Sensor_Blocked_Request" ;
VAL_ 1456 FD14_BSS_CFG_STATSts 0 "Not_enabled" 1 "Enabled_for_LED" 2 "Enabled_for_LED_and_Chime" 3 "SNA" ;
VAL_ 1456 FD14_BSS_SRV_RQSts 0 "No_Service_Request" 1 "Service_Request" ;
VAL_ 1456 FD14_Chime_Priority 0 "A" 1 "B" 2 "C" 3 "D" 4 "E" ;
VAL_ 1456 FD14_Chime_TypSts 0 "Default" 1 "Chime 1" 2 "Chime 2" 3 "Chime 3" 4 "Chime 4" 5 "Chime 5" 6 "Chime 6" 7 "Chime 7" 8 "Chime 8" 9 "Chime 9" 10 "Chime 10" ;
VAL_ 1456 FD14_DDD_DispPopupSts 0 "No_Code" 1 "Drowsniness_Detected" 2 "DDD_Perm_Fail" 3 "SNA" ;
VAL_ 1456 FD14_DDD_FailSts 0 "Fail_Not_Present" 1 "Fail_Present" ;
VAL_ 1456 FD14_DisplaySts_ACC 0 "Off" 1 "Ready_TG1" 2 "Ready_TG2" 3 "Ready_TG3" 4 "Ready_TG4" 5 "ACC_E_NT_TG1" 6 "ACC_E_NT_TG2" 7 "ACC_E_NT_TG3" 8 "ACC_E_NT_TG4" 9 "ACC_E_WT_TG1" 10 "ACC_E_WT_TG2" 11 "ACC_E_WT_TG3" 12 "ACC_E_WT_TG4" 13 "NCC_Ready" 14 "NCC_Engaged" ;
VAL_ 1456 FD14_DisplaySts_Curve 0 "No_Req" 1 "Left" 2 "Right" ;
VAL_ 1456 FD14_DisplaySts_OFF 0 "No_Code" 1 "ACC_LKA_HAS" 2 "ACC_LKA" 3 "ACC_HAS" 4 "ACC" 5 "LKA" ;
VAL_ 1456 FD14_DisplaySts_Veh 0 "Off" 1 "Center_White" 2 "Center_Green" 3 "Right_Crossing_1" 4 "Left_Crossing_1" 5 "Right_Crossing_2" 6 "Left_Crossing_2" ;
VAL_ 1456 FD14_Driver_Model 0 "Attention_Unknown" 1 "Attention_Criteria_Met" 2 "Attention_Criteria_Not_Met" 3 "Faulted" ;
VAL_ 1456 FD14_FCW_Setting_Avail 0 "Available" 1 "Not_Available" ;
VAL_ 1456 FD14_HAS_Blind 0 "Fail_Not_Present" 1 "Fail_Present" ;
VAL_ 1456 FD14_HAS_Escalation_Sts 0 "No_State" 1 "State0" 2 "State1" 3 "State2" 4 "State3a" 5 "State3b" 6 "State4a" 7 "State4b" 8 "State5" ;
VAL_ 1456 FD14_HAS_FailSts 0 "Fail_Not_Present" 1 "Fail_Present" ;
VAL_ 1456 FD14_HAS_TelltaleSts 0 "OFF" 1 "GREY" 2 "GREEN" 3 "YELLOW" 4 "RED" 5 "GREEN_HANDS_FREE" 6 "YELLOW_HANDS_FREE" 7 "SNA" ;
VAL_ 1456 FD14_HAS_TurnSignalRequest 0 "No_Request" 1 "Left" 2 "Right" ;
VAL_ 1456 FD14_ICA_Blind 0 "Blinded" 1 "Not_Blinded" ;
VAL_ 1456 FD14_Lane_DisplaySts_Left 0 "Off" 1 "Gray" 2 "Green" 3 "Yellow" 4 "Yellow_Flashing" 5 "Red" 6 "Dashed" 7 "White" ;
VAL_ 1456 FD14_Lane_DisplaySts_Right 0 "Off" 1 "Gray" 2 "Green" 3 "Yellow" 4 "Yellow_Flashing" 5 "Red" 6 "Dashed" 7 "White" ;
VAL_ 1456 FD14_Lane_DispPopupSts 0 "No_Code" 1 "LKA_On" 2 "LKA_Off" 3 "LKA_Hands_Off" 4 "HAS_Eyes_Off_Yellow" 5 "Take_Control_Red" 6 "HAS_Ready_Highway" 7 "Blind_Spot_OFF" 8 "HAS_Ready_ACC_Set" 9 "HAS_Unavailable_Speed_to_High" 10 "HAS_Unavailable_Trailer" 11 "HAS_Unavailable_TempNAP" 12 "HAS_Cancel_FOW" 13 "HAS_Cancel_Lane" 15 "HAS_Cancel_Curve" 16 "Unsupport_Lane_Ahead_Take_Control" 17 "MRM_In_Prog" 18 "MRM_Complete" 19 "HAS_Unavail_Lane" 20 "HAS_Hands_Off_Yellow" 21 "HAS_Hands_Off_Red" 22 "HAS_Cancel_Hands_Off" 23 "HAS_AEB_LKA_Cam_Blind" 24 "HAS_AEB_Cam_Blind" 25 "HAS_LKA_Cam_Blind" 26 "HAS_Cam_Blind" 27 "LKA_AEB_Cam_Blind" 28 "LKA_Cam_Blind" 29 "HAS_AEB_Radar_Blind" 30 "HAS_Radar_Blind" 31 "HAS_AEB_LKA_LIMITED_Fail" 32 "HAS_AEB_LIMITED_Fail" 33 "LKA_AEB_LIMITED_Fail" 34 "HAS_AEB_LKA_Fail" 35 "HAS_AEB_Fail" 36 "HAS_LKA_Fail" 37 "HAS_Fail" 38 "LKA_AEB_Fail" 39 "LKA_Fail" 40 "HAS_Cancel" 42 "HAS_ON" 43 "HAS_OFF" 44 "BSS_Blind_ALM_On" 45 "BSS_Blind_ALM_Off" 46 "BSS_OPR_ALM_Off" 47 "BSS_OPR_ALM_On" 48 "BSS_SRV_ALM_Off" 49 "BSS_SRV_ALM_On" 50 "HAS_Unavail_Road_Data" 51 "HAS_Unavail_No_Eyes_On" 52 "HAS_Unavail_Map_OOD" 53 "HAS_Unavail_Locked_Out" 54 "HAS_Cancel_Road_Data" 55 "HAS_Cancel_Driver_Not_Attent" 56 "HAS_Cancel_Brake_Event" 57 "HAS_Cancel_Speed_Too_High" 58 "HAS_Cancel_Control_Limit" 59 "HAS_ACC_Unavailable_4WD_Low" 60 "HAS_ACC_Unavailable_ESC_Off" 61 "HAS_ACC_Unavailable_ESC_Event" 62 "HAS_ACC_Unavailable_Brakes_Cooling" 63 "HAS_ACC_Unavailable_EPB_Active" 64 "HAS_ACC_Unavailable_Shift_D" 65 "HAS_ACC_Unavailable_Door_Open" 66 "HAS_ACC_Unavailable_Seatbelt_Unbuckled" 67 "HAS_ACC_Unavailable_Road_to_Steep" 68 "HAS_ACC_Unavailable_Low_RPM" 69 "HAS_ACC_Unavailable_High_RPM" 70 "HAS_ACC_Cancel" 71 "HAS_ACC_AEB_Cancel_ESC_Off" 72 "HAS_ACC_Cancel_ESC_Off" 73 "HAS_ACC_Cancel_ESC_Event" 74 "HAS_ACC_Cancel_Brakes_Cooling" 75 "HAS_ACC_Cancel_EPB_Active" 76 "HAS_ACC_Cancel_Shift_D" 77 "HAS_ACC_Cancel_Door_Open" 78 "HAS_ACC_Cancel_Seatbelt_Unbuckled" 79 "HAS_ACC_Cancel_Road_to_Steep" 80 "HAS_ACC_Cancel_Low_RPM" 81 "HAS_ACC_Cancel_High_RPM" 82 "HAS_ACC_Stop_Vehicle_Object_Detected" 83 "HAS_ACC_User_Enabled" 84 "HAS_ACC_Set" 85 "LKA_Off_Check" 86 "HAS_Curve_Too_Tight" 87 "HAS_Lane_Split" 88 "HAS_On_Reminder" 89 "HAS_ACC_Unavail_Corsa" 90 "LKA_Unavail_Corsa" 91 "HAS_ACC_Unavailable_Off_Road" 92 "BSS_Unavail_Corsa" 93 "BSS_Trailer_On" 94 "BSS_Trailer_Max" 95 "ADAS_Unavailable_Snow_Plow_Detected" 96 "HF_ADA_Set" 97 "Ready_No_Road_HF" 98 "Adjust_Seat_State_2" 99 "Drowsy_State_2" 100 "HF_To_HO_Generic" 101 "HF_To_HO_Hwy_Ending" 102 "HF_Cancel_Not_Attentive" 103 "DA_Set_HF_Service" 104 "Stay_In_Lane" 105 "ALM_Unavail_ESC_Off" 106 "ALM_Off_ESC_Off" 107 "HAS_ACC_Unavail_HDC" 108 "HAS_ACC_AEB_Cancel_Off_Road" 109 "HAS_ACC_Cancel_Off_Road" 110 "HAS_Only_Fail" 111 "HAS_Only_ALM_Fail" 112 "MRM_Complete_Shift_P" 113 "HAS_Eyes_Off_Red" 114 "LKA_Cancel_Hands_Off" ;
VAL_ 1456 FD14_LF_Chime_RqSts 0 "No_Request" 1 "Request" ;
VAL_ 1456 FD14_LKA_Blind 0 "Fail_Not_Present" 1 "Fail_Present" ;
VAL_ 1456 FD14_LKA_FailSts 0 "Fail_Not_Present" 1 "Fail_Present" ;
VAL_ 1456 FD14_LKA_Status 0 "OFF" 1 "ON" ;
VAL_ 1456 FD14_LR_Chime_RqSts 0 "No_left_rear_chime_on_req" 1 "Left_rear_chime_on_req" ;
VAL_ 1456 FD14_NCC_FailSts 0 "Fail_Not_Present" 1 "Fail_Present" ;
VAL_ 1456 FD14_PEB_Setting_Avail 0 "Available" 1 "Not_Available" ;
VAL_ 1456 FD14_RF_Chime_RqSts 0 "No_Request" 1 "Request" ;
VAL_ 1456 FD14_RR_Chime_RqSts 0 "No_rght_rear_chime_on_req" 1 "Right_rear_chime_on_req" ;
VAL_ 1456 FD14_Set_Speed_KPH 255 "SNA" ;
VAL_ 1456 FD14_Set_Speed_MPH 255 "SNA" ;
VAL_ 1456 FD14_SVI_Request 0 "OFF" 1 "Green" 2 "YELLOW" 3 "Red" ;
VAL_ 280 FD14_ACC_Drive_Cmd 0 "Not_Enabled" 1 "Enabled" ;
VAL_ 280 FD14_ACC_StopStart 0 "DEFAULT" 1 "AutoStop_Allowed" 2 "AutoStart_Allowed" 3 "SNA" ;
VAL_ 280 FD14_ACC_Systemsts 0 "OFF" 1 "ACC_Enabled" 2 "ACC_Engaged" 3 "ACC_Engaged_BrakeOnly" 4 "ACC_Cancel" 5 "NCC_Enabled" 6 "NCC_Engaged" 7 "NCC_Cancel" 8 "HAS_BSoC" 9 "RRCC_Enabled_No_Set_Speed" 10 "RRCC_Enabled_With_Set_Speed" 11 "RRCC_Engaged" 15 "SNA" ;
VAL_ 280 FD14_AEB_Sensitivity_Setting 0 "NEAR" 1 "MEDIUM" 2 "FAR" ;
VAL_ 280 FD14_AEB_Systemsts 0 "FCW_Off" 1 "FCW_On_Only_Warning" 2 "FCW_On_Full" ;
VAL_ 280 FD14_AEB_Type 0 "NONE" 1 "ACC" 2 "CMS" 3 "CMS_XTD" 4 "ABA" 5 "LSCM" 6 "PEB" 7 "ICA_L" 8 "ICA_R" 9 "HAS_MRM" 10 "RRCC" 15 "SNA" ;
VAL_ 280 FD14_Brake_Jerk_Req 0 "Not_Active" 1 "Active" ;
VAL_ 280 FD14_CADM_OpStat 0 "Inactive" 1 "FullService" 2 "FailOperational" 3 "FailDegraded" 4 "Emergency" 5 "No_Function" ;
VAL_ 280 FD14_CADM2_EPSSEC_FAIL 0 "False" 1 "True" ;
VAL_ 280 FD14_CIPV_Fused 0 "Not_Active" 1 "Active" ;
VAL_ 280 FD14_DDD_Setting_Avail 0 "Available" 1 "Not_Available" ;
VAL_ 280 FD14_DDD_SystemSts 0 "OFF" 1 "ON" ;
VAL_ 280 FD14_ESA_FailSts 0 "False" 1 "True" ;
VAL_ 280 FD14_ESA_LaneClear_Status 0 "NONE" 1 " Left_Clear" 2 "Right_Clear" 3 "Both_Clear" 4 "Neither-Clear" 5 "Undetermined" 7 "SNA" ;
VAL_ 280 FD14_ESA_LAT_CTRL_RequestSts 0 "No_Request" 1 "ESA_Request" 2 "Faulted" 3 "SNA" ;
VAL_ 280 FD14_ESASystemSts 0 "Not_Enabled" 1 "Pending" 2 "Pre_Active" 3 "Active" 4 "Locked" 5 "Temporarily_Not_Avail" 6 "Permanently_Not_Available" 7 "SNA" ;
VAL_ 280 FD14_ESCALATION_TYPE 0 "None" 1 "Driver_Inattention" 2 "Low_Urgency" 3 "Med_Urgency" 4 "High_Urgency" ;
VAL_ 280 FD14_GrMax_Rq_ACC 0 "Passive" 1 "G1" 2 "G2" 3 "G3" 4 "G4" 5 "G5" 6 "G6" 7 "G7" 8 "G8" 9 "G9" 10 "G10" 11 "G11" 12 "G12" 13 "G13" 14 "G14" 15 "G15" ;
VAL_ 280 FD14_HAS_LAT_CTRL_RequestSts 0 "Idle" 1 "Faulted" 2 "HAS_Request" ;
VAL_ 280 FD14_HAS_OpStat_Prim 0 "Inactive" 1 "FullService" 2 "FailOperational" 3 "FailDegraded" 4 "Emergency" 5 "No_Function" ;
VAL_ 280 FD14_HAS_Status 0 "Disabled" 1 "Enabled" 2 "Engaged" 3 "Faulted" ;
VAL_ 280 FD14_HIS_Req 0 "Not_Active" 1 "Active" ;
VAL_ 280 FD14_Intervention 4095 "SNA" ;
VAL_ 280 FD14_LANE_CHANGE_SIDE 0 "NO_CHNG" 1 "RIGHT" 2 "LEFT" ;
VAL_ 280 FD14_LANE_CHANGE_STATUS 0 "NO_CHNG" 1 "PEND" 2 "EARLY1" 3 "EARLY2" 4 "LATE" 5 "ABORTING" 6 "ABORTED" 7 "COMPL" 8 "LOCKOUT" 9 "CANCELLING" 10 "CANCELLED" 11 "Msg_11" 12 "Msg_12" 13 "Msg_13" 14 "Msg_14" 15 "SNA" ;
VAL_ 280 FD14_LC_Jerk 0 "Not_Active" 1 "Active" ;
VAL_ 280 FD14_LKA_LAT_CTRL_RequestSts 0 "Idle" 1 "Faulted" 2 "LKA_Request" ;
VAL_ 280 FD14_MRM_STATUS 0 "Not_Active" 1 "MRM_in_Process" 2 "Vehicle_Secure_Request" 3 "Vehicle_Securement_Complete" 4 "Canceled" 7 "SNA" ;
VAL_ 280 FD14_Object_Dist 255 "SNA" ;
VAL_ 280 FD14_PEB_SystemSts 0 "OFF" 1 "ON" ;
VAL_ 280 FD14_Prefill_Req 0 "No_Prefill_Requested" 1 "Prefill_Requested" ;
VAL_ 280 FD14_SteeringVibration_Rq 0 "NOT_REQUESTED" 1 "REQUESTED" ;
VAL_ 280 FD14_SteeringVibration_Type 0 "TYPE_0" 1 "TYPE_1" 2 "TYPE_2" 3 "TYPE_3" 4 "TYPE_4" 5 "TYPE_5" 6 "TYPE_6" 7 "TYPE_7" 8 "TYPE_8" 9 "TYPE_9" 10 "TYPE_10" 11 "TYPE_11" 15 "SNA" ;
VAL_ 299 FD14_ACC_Axle_Torque 65535 "SNA" ;
VAL_ 299 FD14_ACC_Axle_Torque_Enabled 0 "Not_Enabled" 1 "Enabled" ;
VAL_ 730 FD14_Camera_Status 0 "None_Active" 1 "Left_Right_Front" 2 "Left_Right" 3 "Left_Front" 4 "Right_Front" 5 "Front" 6 "Left" 7 "Right" ;
VAL_ 730 FD14_FOD_Confidence 0 "Not_Detected" 1 "Detected_Low_Confidence" 2 "Detected_Medium_Confidence" 3 "Detected_High_Confidence" ;
VAL_ 730 FD14_Health_Front_Object_Detecti 0 "Faulted" 1 "Blocked" 2 "Unknown" 3 "Healthy" ;
VAL_ 730 FD14_Health_Lane_Detection 0 "Faulted" 1 "Blocked" 2 "Unknown" 3 "Healthy" ;
VAL_ 730 FD14_Line_1_Type 0 "None" 1 "Solid" 2 "Dashed" 3 "Double" 4 "Road_edge" 5 "Botts_Dotts" 6 "Barrier" ;
VAL_ 730 FD14_Line_2_Type 0 "None" 1 "Solid" 2 "Dashed" 3 "Double" 4 "Road_edge" 5 "Botts_Dotts" 6 "Barrier" ;
VAL_ 730 FD14_Line_3_Type 0 "None" 1 "Solid" 2 "Dashed" 3 "Double" 4 "Road_edge" 5 "Botts_Dotts" 6 "Barrier" ;
VAL_ 730 FD14_Line_4_Type 0 "None" 1 "Solid" 2 "Dashed" 3 "Double" 4 "Road_edge" 5 "Botts_Dotts" 6 "Barrier" ;
VAL_ 204 FD14_Axle_Torque_DrvReqMod 65535 "SNA" ;
VAL_ 204 FD14_Axle_TorqueStatic_D_TTC 65535 "SNA" ;
VAL_ 204 FD14_Total_AxleTorque_Max 65535 "SNA" ;
VAL_ 204 FD14_Total_AxleTorque_Min 65535 "SNA" ;
VAL_ 513 FD14_Brk_Jrk_Resp 0 "Not_Executed" 1 "Executed" ;
VAL_ 513 FD14_Brk_Thermdl 0 "Normal_Temperature" 1 "High_Temperature" ;
VAL_ 513 FD14_BrkTrq 32767 "SNA" ;
VAL_ 513 FD14_BrkTrq_Driver 32767 "SNA" ;
VAL_ 513 FD14_DASEngReqPos 0 "Not_Allowed" 1 "Allowed" ;
VAL_ 513 FD14_EngSpdIntervReq 0 "False" 1 "True" ;
VAL_ 513 FD14_ExternalBrkRequestsDisabled 0 "No request" 1 "External Systems temporary off" 2 "External Systems continuous off" 3 "SNA" ;
VAL_ 513 FD14_GrMax_Rq_BSM 0 "Passive" 1 "G1" 2 "G2" 3 "G3" 4 "G4" 5 "G5" 6 "G6" 7 "G7" 8 "G8" 9 "G9" ;
VAL_ 513 FD14_GrMin_Rq_BSM 0 "Passive" 1 "G1" 2 "G2" 3 "G3" 4 "G4" 5 "G5" 6 "G6" 7 "G7" 8 "G8" 9 "G9" ;
VAL_ 513 FD14_REF_VEH_SPEED 1023 "SNA" ;
VAL_ 513 FD14_SelectSpdSts 0 "OFF" 1 "Select Speed Mode" 2 "Select Speed Mode Inhibit" 3 "SNA" ;
VAL_ 513 FD14_SelSpdLmp 0 "OFF" 1 "CONT" 2 "BLINK" 3 "SNA" ;
VAL_ 513 FD14_VehicleStandStillSts 0 "True" 1 "False" 3 "SNA" ;
VAL_ 258 FD14_ABSActive 0 "Not_active" 1 "Active" ;
VAL_ 258 FD14_BrakeBoostPressure 2047 "SNA" ;
VAL_ 258 FD14_BrakeBoostStat 0 "INIT_Bst" 1 "Normal_Bst" 2 "Limited_Bst" 3 "Shutdown_Bst" 4 "MOCO" 5 "Half_Sys_Bst" 6 "No_Bst" 15 "SNA" ;
VAL_ 258 FD14_BrakeInterventionSts 0 "No_active_brake_intervention" 1 "Active_brake_intervention" ;
VAL_ 258 FD14_BrakePedalPressure 2047 "SNA" ;
VAL_ 258 FD14_Brk_Stat 0 "IDLE" 1 "BRAKING" 2 "NDEF2" 3 "SNA" ;
VAL_ 258 FD14_BSM_ESASystemSts 0 "Not_Enabled" 1 "Pending" 2 "Pre_Active" 3 "Active" 4 "Locked" 5 "Temporarily_Not_Avail" 6 "Permanently_Not_Avail" 7 "SNA" ;
VAL_ 258 FD14_ESCActive 0 "Not_active" 1 "Active" ;
VAL_ 258 FD14_ESP_Sys_Stat 0 "ABSERR_DIAG" 1 "NORM" 2 "HALF" 3 "ABGAS" ;
VAL_ 258 FD14_InternalError_BSM 0 "No_int_processing_error_detected" 1 "Int_processing_error_detected" ;
VAL_ 258 FD14_LatAcceleration_BSM 4095 "SNA" ;
VAL_ 258 FD14_LatAccelerationFailSts_BSM 0 "Fail_Not_Present" 1 "Fail_Present" ;
VAL_ 258 FD14_LongAcceleration_BSM 4095 "SNA" ;
VAL_ 258 FD14_LongAccelerationFailSts_BSM 0 "Fail_Not_Present" 1 "Fail_Present" ;
VAL_ 258 FD14_ParkingGearShiftReq_BSM 0 "Idle" 1 "P" 2 "R" 3 "N" 4 "D" 7 "SNA" ;
VAL_ 258 FD14_ParkingInterventionSts 0 "Not_Active" 1 "Active" 2 "Faulted_External" 3 "Faulted_Internal" ;
VAL_ 258 FD14_PrefillActive 0 "Not_Active" 1 "Active" ;
VAL_ 258 FD14_Slope 255 "SNA" ;
VAL_ 258 FD14_VehicleSpeedVSOSig 8191 "SNA" ;
VAL_ 258 FD14_WheelRPM_FL 65535 "SNA" ;
VAL_ 258 FD14_WheelRPM_FR 65535 "SNA" ;
VAL_ 258 FD14_YawRate_BSM 4095 "SNA" ;
VAL_ 258 FD14_YawRateFailSts_BSM 0 "Fail_Not_Present" 1 "Fail_Present" ;
VAL_ 259 FD14_LatAccelerationOffset_BSM 255 "SNA" ;
VAL_ 259 FD14_LHF_FastPulseCounter 255 "SNA" ;
VAL_ 259 FD14_LHF_Spin 0 "Stand_Still" 1 "Forward" 2 "Backward" 3 "SNA" ;
VAL_ 259 FD14_LHF_WheelSensorFailSts 0 "Fail_Not_Present" 1 "Fail_Present" ;
VAL_ 259 FD14_LHFWheelSpeed 8191 "SNA" ;
VAL_ 259 FD14_LHR_FastPulseCounter 255 "SNA" ;
VAL_ 259 FD14_LHR_Spin 0 "Stand_Still" 1 "Forward" 2 "Backward" 3 "SNA" ;
VAL_ 259 FD14_LHR_WheelSensorFailSts 0 "Fail_Not_Present" 1 "Fail_Present" ;
VAL_ 259 FD14_LHRWheelSpeed 8191 "SNA" ;
VAL_ 259 FD14_LongAccelerationOffset_BSM 255 "SNA" ;
VAL_ 259 FD14_LwsAngleOffset_BSM 1023 "SNA" ;
VAL_ 259 FD14_RHF_FastPulseCounter 255 "SNA" ;
VAL_ 259 FD14_RHF_Spin 0 "Stand_Still" 1 "Forward" 2 "Backward" 3 "SNA" ;
VAL_ 259 FD14_RHF_WheelSensorFailSts 0 "Fail_Not_Present" 1 "Fail_Present" ;
VAL_ 259 FD14_RHFWheelSpeed 8191 "SNA" ;
VAL_ 259 FD14_RHR_FastPulseCounter 255 "SNA" ;
VAL_ 259 FD14_RHR_Spin 0 "Stand_Still" 1 "Forward" 2 "Backward" 3 "SNA" ;
VAL_ 259 FD14_RHR_WheelSensorFailSts 0 "Fail_Not_Present" 1 "Fail_Present" ;
VAL_ 259 FD14_RHRWheelSpeed 8191 "SNA" ;
VAL_ 259 FD14_YawRateOffset_BSM 255 "SNA" ;
VAL_ 609 FD14_ASRActive 0 "Not_active" 1 "Active" ;
VAL_ 609 FD14_BSM_LnchAbrtSts 0 "NOT" 1 "AwE" 2 "AwA" 3 "SNA" ;
VAL_ 609 FD14_BSM_LnchCtrl_SftBtn_SelectS 0 "False" 1 "True" ;
VAL_ 609 FD14_BSM_LnchMode 0 "LAUNCH_OFF" 1 "LAUNCH_ON" 2 "LAUNCH_ACT" 3 "CNC" 4 "LAUNCH_ACT_RPM_PHASE" 7 "SNA" ;
VAL_ 609 FD14_EPBSts 0 "Released" 1 "Applied" 2 "DynamicBrkESC" 3 "DynamicBrkEPB" 4 "Emergency_Braking" 5 "Applying" 6 "Maintenance_Mode" 7 "Assembly_Check" 8 "Inspection_Mode" 9 "Re_Clamping" 10 "Adjuste_Mode" 11 "Releasing" 12 "Fault_EPB_Released" 13 "Fault_EPB_Applied" 14 "Fault_Present" 15 "SNA" ;
VAL_ 609 FD14_ESC_OFF_Hrd_Sft_Button_sts 0 "STREET" 1 "SPORT" 2 "TRACK" 3 "OFF" 4 "SNOW" 5 "OFFROAD" 7 "SNA" ;
VAL_ 609 FD14_MSRActive 0 "Not_Active" 1 "Active" ;
VAL_ 609 FD14_TravelDistance 255 "SNA" ;
SIG_VALTYPE_ 2654552167 FD14_Trailer_tracking_confidence : 1;
SIG_VALTYPE_ 2654552167 FD14_Trailer_Recognition_Confide : 1;
SIG_VALTYPE_ 2654552167 FD14_JackknifeThrAngle : 1;
SIG_VALTYPE_ 2654552167 FD14_JackknifeAngle : 1;
SIG_VALTYPE_ 2654552167 FD14_hitchLength : 1;
SIG_VALTYPE_ 2654552167 FD14_TADAngleRate : 1;
SIG_VALTYPE_ 2654552167 FD14_trailerAngle : 1;
SIG_VALTYPE_ 2654552328 FD14_stUSSParkingSlot4RearRightY : 1;
SIG_VALTYPE_ 2654552328 FD14_stUSSParkingSlot4FrontLeftY : 1;
SIG_VALTYPE_ 2654552328 FD14_stUSSParkingSlot1RearRightY : 1;
SIG_VALTYPE_ 2654552328 FD14_stUSSParkingSlot1FrontLeftY : 1;
SIG_VALTYPE_ 2654552328 FD14_stUSSParkingSlot4RearRightX : 1;
SIG_VALTYPE_ 2654552328 FD14_stUSSParkingSlot4FrontLeftX : 1;
SIG_VALTYPE_ 2654552328 FD14_stUSSParkingSlot1RearRightX : 1;
SIG_VALTYPE_ 2654552328 FD14_stUSSParkingSlot1FrontLeftX : 1;
SIG_VALTYPE_ 2654552329 FD14_stUSSLockedSlotDataRearRigh : 1;
SIG_VALTYPE_ 2654552329 FD14_stUSSLockedSlotDataFrontLef : 1;
SIG_VALTYPE_ 2654552329 FD14_stUSSLockedSlotDataRea_0000 : 1;
SIG_VALTYPE_ 2654552329 FD14_stUSSLockedSlotDataFro_0000 : 1;
